VERSION ""

NS_ :

BS_:

BU_:

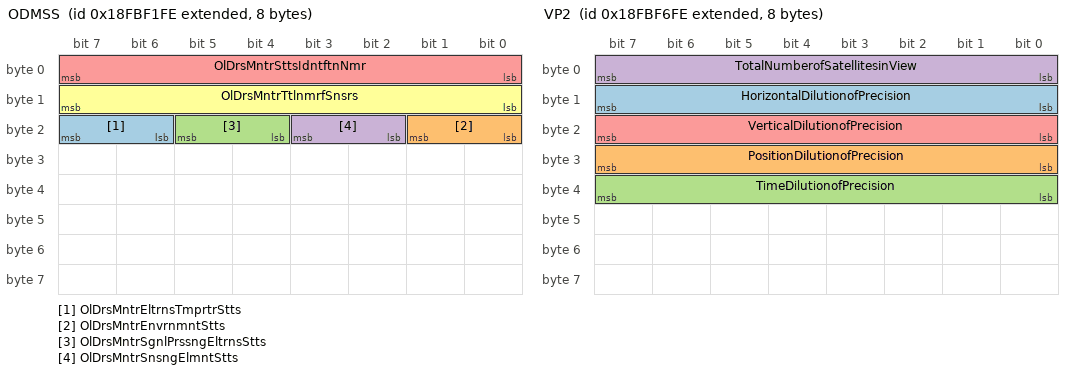
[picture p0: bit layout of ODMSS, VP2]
BO_ 2566648318 ODMSS: 8 Vector__XXX
 SG_ OlDrsMntrEltrnsTmprtrStts : 22|2@1+ (1,0) [0|3] "" Vector__XXX
 SG_ OlDrsMntrEnvrnmntStts : 16|2@1+ (1,0) [0|3] "" Vector__XXX
 SG_ OlDrsMntrSgnlPrssngEltrnsStts : 20|2@1+ (1,0) [0|3] "" Vector__XXX
 SG_ OlDrsMntrSnsngElmntStts : 18|2@1+ (1,0) [0|3] "" Vector__XXX
 SG_ OlDrsMntrSttsIdntftnNmr : 0|8@1+ (1,0) [0|250] "count" Vector__XXX
 SG_ OlDrsMntrTtlnmrfSnsrs : 8|8@1+ (1,0) [0|250] "count" Vector__XXX

BO_ 2566649086 A2DOC2: 8 Vector__XXX
 SG_ Atttt2DOCIttDPFOttDtPss : 32|16@1+ (0.1,0) [0|6425.5] "kPa" Vector__XXX
 SG_ Atttt2DsOxdtCtstItPss : 0|16@1+ (0.1,0) [0|6425.5] "kPa" Vector__XXX
 SG_ Atttt2DsOxdtCtstOttPss : 16|16@1+ (0.1,0) [0|6425.5] "kPa" Vector__XXX

BO_ 2566649342 A1DOC2: 8 Vector__XXX
 SG_ Atttt1DOCIttDPFOttDtPss : 32|16@1+ (0.1,0) [0|6425.5] "kPa" Vector__XXX
 SG_ Atttt1DsOxdtCtstItPss : 0|16@1+ (0.1,0) [0|6425.5] "kPa" Vector__XXX
 SG_ Atttt1DsOxdtCtstOttPss : 16|16@1+ (0.1,0) [0|6425.5] "kPa" Vector__XXX

BO_ 2566649598 VP2: 8 Vector__XXX
 SG_ HorizontalDilutionofPrecision : 8|8@1+ (0.1,0) [0|25] "Ratio" Vector__XXX
 SG_ PositionDilutionofPrecision : 24|8@1+ (0.1,0) [0|25] "Ratio" Vector__XXX
 SG_ TimeDilutionofPrecision : 32|8@1+ (0.1,0) [0|25] "Ratio" Vector__XXX
 SG_ TotalNumberofSatellitesinView : 0|8@1+ (1,0) [0|250] "count" Vector__XXX
 SG_ VerticalDilutionofPrecision : 16|8@1+ (0.1,0) [0|25] "Ratio" Vector__XXX

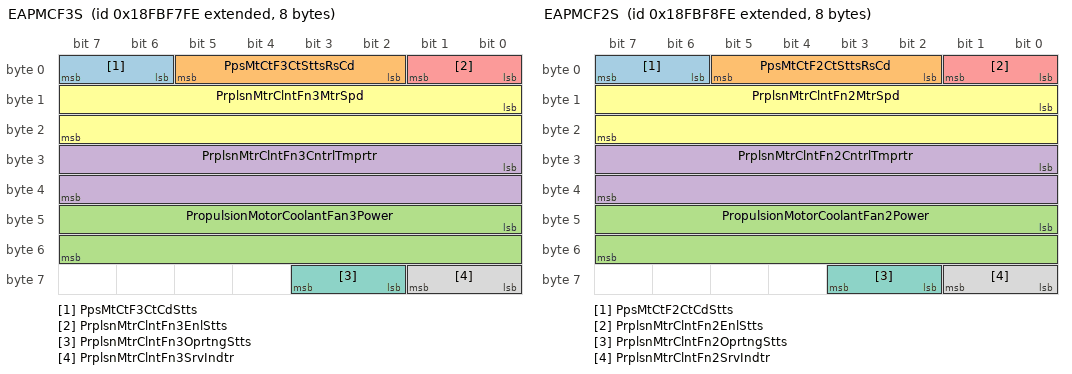
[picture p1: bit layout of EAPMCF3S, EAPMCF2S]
BO_ 2566649854 EAPMCF3S: 8 Vector__XXX
 SG_ PpsMtCtF3CtCdStts : 6|2@1+ (1,0) [0|3] "" Vector__XXX
 SG_ PpsMtCtF3CtSttsRsCd : 2|4@1+ (1,0) [0|15] "" Vector__XXX
 SG_ PropulsionMotorCoolantFan3Power : 40|16@1+ (0.5,0) [0|32127.5] "W" Vector__XXX
 SG_ PrplsnMtrClntFn3CntrlTmprtr : 24|16@1+ (0.03125,-273) [-273|1734.96875] "degC" Vector__XXX
 SG_ PrplsnMtrClntFn3EnlStts : 0|2@1+ (1,0) [0|3] "" Vector__XXX
 SG_ PrplsnMtrClntFn3MtrSpd : 8|16@1+ (0.5,0) [0|32127.5] "rpm" Vector__XXX
 SG_ PrplsnMtrClntFn3OprtngStts : 58|2@1+ (1,0) [0|3] "" Vector__XXX
 SG_ PrplsnMtrClntFn3SrvIndtr : 56|2@1+ (1,0) [0|3] "" Vector__XXX

BO_ 2566650110 EAPMCF2S: 8 Vector__XXX
 SG_ PpsMtCtF2CtCdStts : 6|2@1+ (1,0) [0|3] "" Vector__XXX
 SG_ PpsMtCtF2CtSttsRsCd : 2|4@1+ (1,0) [0|15] "" Vector__XXX
 SG_ PropulsionMotorCoolantFan2Power : 40|16@1+ (0.5,0) [0|32127.5] "W" Vector__XXX
 SG_ PrplsnMtrClntFn2CntrlTmprtr : 24|16@1+ (0.03125,-273) [-273|1734.96875] "degC" Vector__XXX
 SG_ PrplsnMtrClntFn2EnlStts : 0|2@1+ (1,0) [0|3] "" Vector__XXX
 SG_ PrplsnMtrClntFn2MtrSpd : 8|16@1+ (0.5,0) [0|32127.5] "rpm" Vector__XXX
 SG_ PrplsnMtrClntFn2OprtngStts : 58|2@1+ (1,0) [0|3] "" Vector__XXX
 SG_ PrplsnMtrClntFn2SrvIndtr : 56|2@1+ (1,0) [0|3] "" Vector__XXX

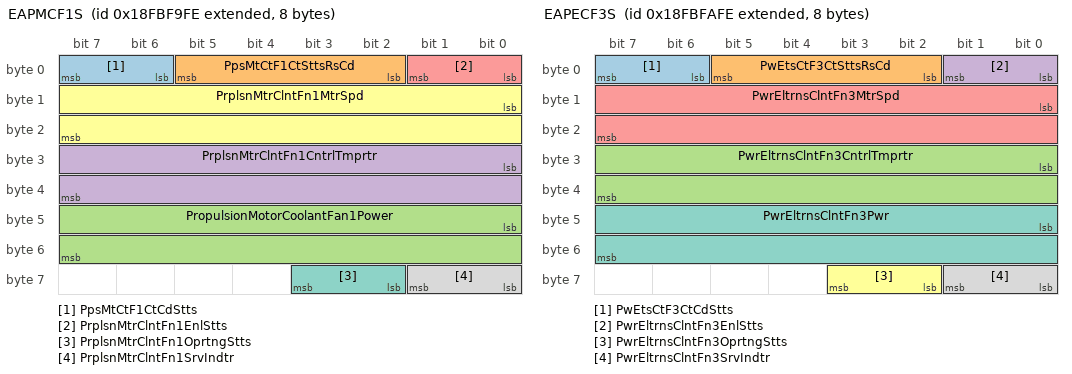
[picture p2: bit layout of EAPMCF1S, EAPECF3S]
BO_ 2566650366 EAPMCF1S: 8 Vector__XXX
 SG_ PpsMtCtF1CtCdStts : 6|2@1+ (1,0) [0|3] "" Vector__XXX
 SG_ PpsMtCtF1CtSttsRsCd : 2|4@1+ (1,0) [0|15] "" Vector__XXX
 SG_ PropulsionMotorCoolantFan1Power : 40|16@1+ (0.5,0) [0|32127.5] "W" Vector__XXX
 SG_ PrplsnMtrClntFn1CntrlTmprtr : 24|16@1+ (0.03125,-273) [-273|1734.96875] "degC" Vector__XXX
 SG_ PrplsnMtrClntFn1EnlStts : 0|2@1+ (1,0) [0|3] "" Vector__XXX
 SG_ PrplsnMtrClntFn1MtrSpd : 8|16@1+ (0.5,0) [0|32127.5] "rpm" Vector__XXX
 SG_ PrplsnMtrClntFn1OprtngStts : 58|2@1+ (1,0) [0|3] "" Vector__XXX
 SG_ PrplsnMtrClntFn1SrvIndtr : 56|2@1+ (1,0) [0|3] "" Vector__XXX

BO_ 2566650622 EAPECF3S: 8 Vector__XXX
 SG_ PwEtsCtF3CtCdStts : 6|2@1+ (1,0) [0|3] "" Vector__XXX
 SG_ PwEtsCtF3CtSttsRsCd : 2|4@1+ (1,0) [0|15] "" Vector__XXX
 SG_ PwrEltrnsClntFn3CntrlTmprtr : 24|16@1+ (0.03125,-273) [-273|1734.96875] "degC" Vector__XXX
 SG_ PwrEltrnsClntFn3EnlStts : 0|2@1+ (1,0) [0|3] "" Vector__XXX
 SG_ PwrEltrnsClntFn3MtrSpd : 8|16@1+ (0.5,0) [0|32127.5] "rpm" Vector__XXX
 SG_ PwrEltrnsClntFn3OprtngStts : 58|2@1+ (1,0) [0|3] "" Vector__XXX
 SG_ PwrEltrnsClntFn3Pwr : 40|16@1+ (0.5,0) [0|32127.5] "W" Vector__XXX
 SG_ PwrEltrnsClntFn3SrvIndtr : 56|2@1+ (1,0) [0|3] "" Vector__XXX

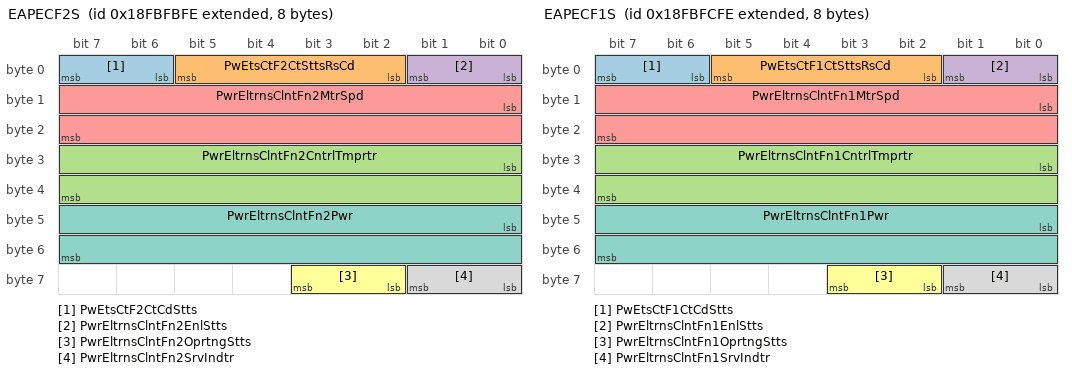
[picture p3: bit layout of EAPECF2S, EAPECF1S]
BO_ 2566650878 EAPECF2S: 8 Vector__XXX
 SG_ PwEtsCtF2CtCdStts : 6|2@1+ (1,0) [0|3] "" Vector__XXX
 SG_ PwEtsCtF2CtSttsRsCd : 2|4@1+ (1,0) [0|15] "" Vector__XXX
 SG_ PwrEltrnsClntFn2CntrlTmprtr : 24|16@1+ (0.03125,-273) [-273|1734.96875] "degC" Vector__XXX
 SG_ PwrEltrnsClntFn2EnlStts : 0|2@1+ (1,0) [0|3] "" Vector__XXX
 SG_ PwrEltrnsClntFn2MtrSpd : 8|16@1+ (0.5,0) [0|32127.5] "rpm" Vector__XXX
 SG_ PwrEltrnsClntFn2OprtngStts : 58|2@1+ (1,0) [0|3] "" Vector__XXX
 SG_ PwrEltrnsClntFn2Pwr : 40|16@1+ (0.5,0) [0|32127.5] "W" Vector__XXX
 SG_ PwrEltrnsClntFn2SrvIndtr : 56|2@1+ (1,0) [0|3] "" Vector__XXX

BO_ 2566651134 EAPECF1S: 8 Vector__XXX
 SG_ PwEtsCtF1CtCdStts : 6|2@1+ (1,0) [0|3] "" Vector__XXX
 SG_ PwEtsCtF1CtSttsRsCd : 2|4@1+ (1,0) [0|15] "" Vector__XXX
 SG_ PwrEltrnsClntFn1CntrlTmprtr : 24|16@1+ (0.03125,-273) [-273|1734.96875] "degC" Vector__XXX
 SG_ PwrEltrnsClntFn1EnlStts : 0|2@1+ (1,0) [0|3] "" Vector__XXX
 SG_ PwrEltrnsClntFn1MtrSpd : 8|16@1+ (0.5,0) [0|32127.5] "rpm" Vector__XXX
 SG_ PwrEltrnsClntFn1OprtngStts : 58|2@1+ (1,0) [0|3] "" Vector__XXX
 SG_ PwrEltrnsClntFn1Pwr : 40|16@1+ (0.5,0) [0|32127.5] "W" Vector__XXX
 SG_ PwrEltrnsClntFn1SrvIndtr : 56|2@1+ (1,0) [0|3] "" Vector__XXX

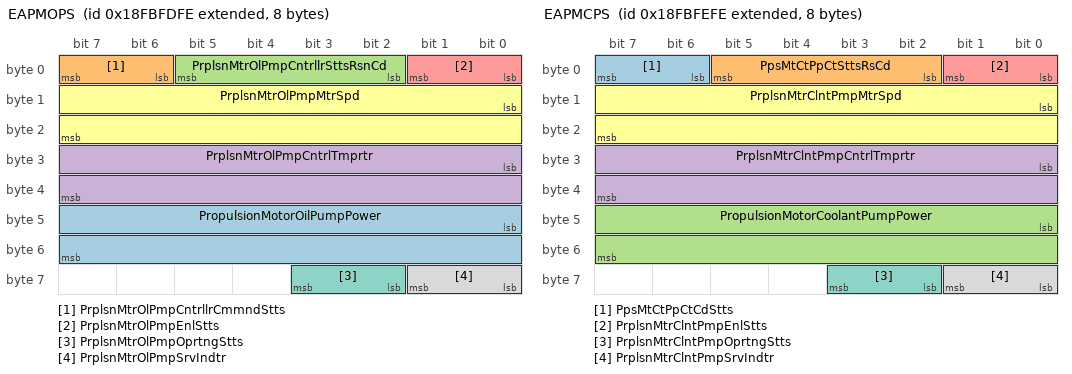
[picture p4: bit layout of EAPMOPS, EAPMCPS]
BO_ 2566651390 EAPMOPS: 8 Vector__XXX
 SG_ PropulsionMotorOilPumpPower : 40|16@1+ (0.5,0) [0|32127.5] "W" Vector__XXX
 SG_ PrplsnMtrOlPmpCntrllrCmmndStts : 6|2@1+ (1,0) [0|3] "" Vector__XXX
 SG_ PrplsnMtrOlPmpCntrllrSttsRsnCd : 2|4@1+ (1,0) [0|15] "" Vector__XXX
 SG_ PrplsnMtrOlPmpCntrlTmprtr : 24|16@1+ (0.03125,-273) [-273|1734.96875] "degC" Vector__XXX
 SG_ PrplsnMtrOlPmpEnlStts : 0|2@1+ (1,0) [0|3] "" Vector__XXX
 SG_ PrplsnMtrOlPmpMtrSpd : 8|16@1+ (0.5,0) [0|32127.5] "rpm" Vector__XXX
 SG_ PrplsnMtrOlPmpOprtngStts : 58|2@1+ (1,0) [0|3] "" Vector__XXX
 SG_ PrplsnMtrOlPmpSrvIndtr : 56|2@1+ (1,0) [0|3] "" Vector__XXX

BO_ 2566651646 EAPMCPS: 8 Vector__XXX
 SG_ PpsMtCtPpCtCdStts : 6|2@1+ (1,0) [0|3] "" Vector__XXX
 SG_ PpsMtCtPpCtSttsRsCd : 2|4@1+ (1,0) [0|15] "" Vector__XXX
 SG_ PropulsionMotorCoolantPumpPower : 40|16@1+ (0.5,0) [0|32127.5] "W" Vector__XXX
 SG_ PrplsnMtrClntPmpCntrlTmprtr : 24|16@1+ (0.03125,-273) [-273|1734.96875] "degC" Vector__XXX
 SG_ PrplsnMtrClntPmpEnlStts : 0|2@1+ (1,0) [0|3] "" Vector__XXX
 SG_ PrplsnMtrClntPmpMtrSpd : 8|16@1+ (0.5,0) [0|32127.5] "rpm" Vector__XXX
 SG_ PrplsnMtrClntPmpOprtngStts : 58|2@1+ (1,0) [0|3] "" Vector__XXX
 SG_ PrplsnMtrClntPmpSrvIndtr : 56|2@1+ (1,0) [0|3] "" Vector__XXX

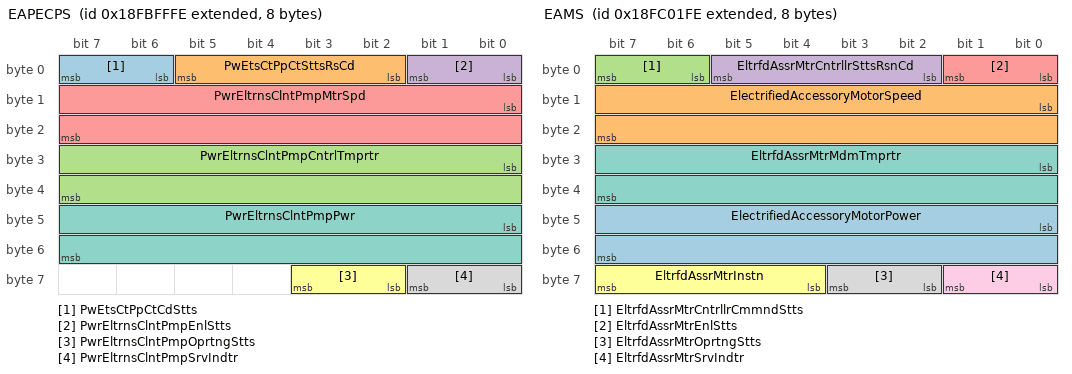
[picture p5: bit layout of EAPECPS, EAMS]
BO_ 2566651902 EAPECPS: 8 Vector__XXX
 SG_ PwEtsCtPpCtCdStts : 6|2@1+ (1,0) [0|3] "" Vector__XXX
 SG_ PwEtsCtPpCtSttsRsCd : 2|4@1+ (1,0) [0|15] "" Vector__XXX
 SG_ PwrEltrnsClntPmpCntrlTmprtr : 24|16@1+ (0.03125,-273) [-273|1734.96875] "degC" Vector__XXX
 SG_ PwrEltrnsClntPmpEnlStts : 0|2@1+ (1,0) [0|3] "" Vector__XXX
 SG_ PwrEltrnsClntPmpMtrSpd : 8|16@1+ (0.5,0) [0|32127.5] "rpm" Vector__XXX
 SG_ PwrEltrnsClntPmpOprtngStts : 58|2@1+ (1,0) [0|3] "" Vector__XXX
 SG_ PwrEltrnsClntPmpPwr : 40|16@1+ (0.5,0) [0|32127.5] "W" Vector__XXX
 SG_ PwrEltrnsClntPmpSrvIndtr : 56|2@1+ (1,0) [0|3] "" Vector__XXX

BO_ 2566652414 EAMS: 8 Vector__XXX
 SG_ ElectrifiedAccessoryMotorPower : 40|16@1+ (0.5,0) [0|32127.5] "W" Vector__XXX
 SG_ ElectrifiedAccessoryMotorSpeed : 8|16@1+ (0.5,0) [0|32127.5] "rpm" Vector__XXX
 SG_ EltrfdAssrMtrCntrllrCmmndStts : 6|2@1+ (1,0) [0|3] "" Vector__XXX
 SG_ EltrfdAssrMtrCntrllrSttsRsnCd : 2|4@1+ (1,0) [0|15] "" Vector__XXX
 SG_ EltrfdAssrMtrEnlStts : 0|2@1+ (1,0) [0|3] "" Vector__XXX
 SG_ EltrfdAssrMtrInstn : 60|4@1+ (1,0) [0|15] "" Vector__XXX
 SG_ EltrfdAssrMtrMdmTmprtr : 24|16@1+ (0.03125,-273) [-273|1734.96875] "degC" Vector__XXX
 SG_ EltrfdAssrMtrOprtngStts : 58|2@1+ (1,0) [0|3] "" Vector__XXX
 SG_ EltrfdAssrMtrSrvIndtr : 56|2@1+ (1,0) [0|3] "" Vector__XXX

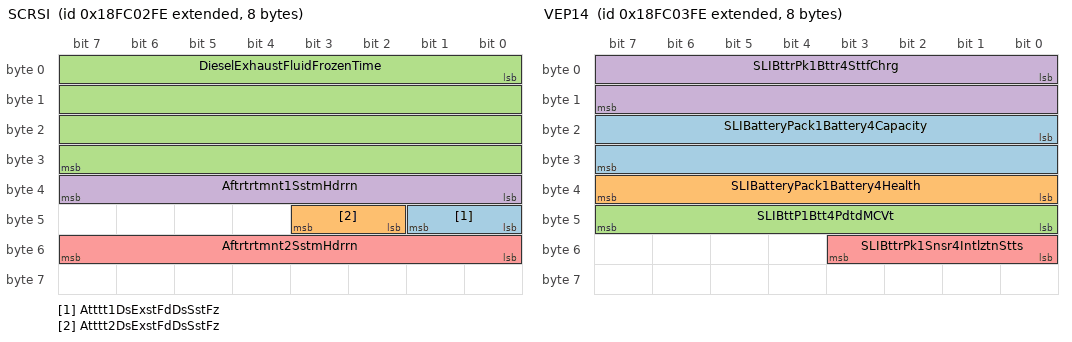
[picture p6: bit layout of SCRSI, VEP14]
BO_ 2566652670 SCRSI: 8 Vector__XXX
 SG_ Atttt1DsExstFdDsSstFz : 40|2@1+ (1,0) [0|3] "" Vector__XXX
 SG_ Atttt2DsExstFdDsSstFz : 42|2@1+ (1,0) [0|3] "" Vector__XXX
 SG_ DieselExhaustFluidFrozenTime : 0|32@1+ (1,0) [0|4211081215] "s" Vector__XXX
 SG_ Aftrtrtmnt1SstmHdrrn : 32|8@1+ (1,0) [0|250] "%" Vector__XXX
 SG_ Aftrtrtmnt2SstmHdrrn : 48|8@1+ (1,0) [0|250] "%" Vector__XXX

BO_ 2566652926 VEP14: 8 Vector__XXX
 SG_ SLIBatteryPack1Battery4Capacity : 16|16@1+ (1,0) [0|64255] "Ah" Vector__XXX
 SG_ SLIBatteryPack1Battery4Health : 32|8@1+ (0.5,0) [0|125] "%" Vector__XXX
 SG_ SLIBttP1Btt4PdtdMCVt : 40|8@1+ (0.2,0) [0|50] "V" Vector__XXX
 SG_ SLIBttrPk1Bttr4SttfChrg : 0|16@1+ (0.0025,0) [0|160.6375] "%" Vector__XXX
 SG_ SLIBttrPk1Snsr4IntlztnStts : 48|4@1+ (1,0) [0|15] "" Vector__XXX

BO_ 2566653182 VEP13: 8 Vector__XXX
 SG_ SLIBatteryPack1Battery4Voltage : 24|16@1+ (0.05,0) [0|3212.75] "V" Vector__XXX
 SG_ SLIBttrPk1Bttr4NtCrrnt : 0|16@1+ (0.05,-1600) [-1600|1612.75] "A" Vector__XXX
 SG_ SLIBttrPk1Bttr4Tmprtr : 16|8@1+ (1,-40) [-40|210] "degC" Vector__XXX

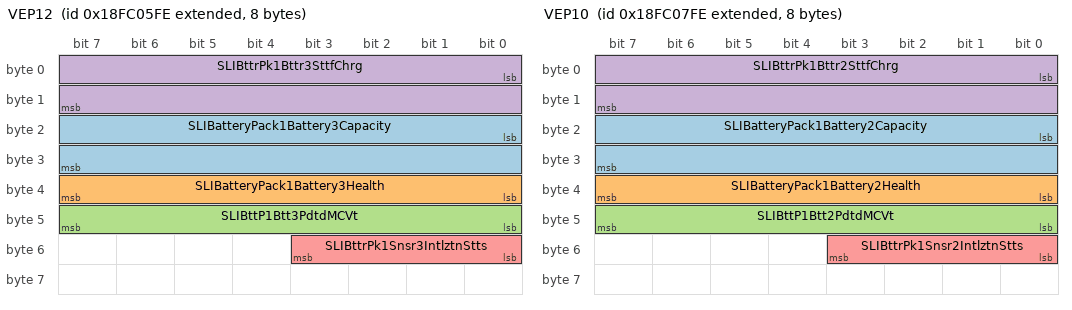
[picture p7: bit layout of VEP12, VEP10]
BO_ 2566653438 VEP12: 8 Vector__XXX
 SG_ SLIBatteryPack1Battery3Capacity : 16|16@1+ (1,0) [0|64255] "Ah" Vector__XXX
 SG_ SLIBatteryPack1Battery3Health : 32|8@1+ (0.5,0) [0|125] "%" Vector__XXX
 SG_ SLIBttP1Btt3PdtdMCVt : 40|8@1+ (0.2,0) [0|50] "V" Vector__XXX
 SG_ SLIBttrPk1Bttr3SttfChrg : 0|16@1+ (0.0025,0) [0|160.6375] "%" Vector__XXX
 SG_ SLIBttrPk1Snsr3IntlztnStts : 48|4@1+ (1,0) [0|15] "" Vector__XXX

BO_ 2566653694 VEP11: 8 Vector__XXX
 SG_ SLIBatteryPack1Battery3Voltage : 24|16@1+ (0.05,0) [0|3212.75] "V" Vector__XXX
 SG_ SLIBttrPk1Bttr3NtCrrnt : 0|16@1+ (0.05,-1600) [-1600|1612.75] "A" Vector__XXX
 SG_ SLIBttrPk1Bttr3Tmprtr : 16|8@1+ (1,-40) [-40|210] "degC" Vector__XXX

BO_ 2566653950 VEP10: 8 Vector__XXX
 SG_ SLIBatteryPack1Battery2Capacity : 16|16@1+ (1,0) [0|64255] "Ah" Vector__XXX
 SG_ SLIBatteryPack1Battery2Health : 32|8@1+ (0.5,0) [0|125] "%" Vector__XXX
 SG_ SLIBttP1Btt2PdtdMCVt : 40|8@1+ (0.2,0) [0|50] "V" Vector__XXX
 SG_ SLIBttrPk1Bttr2SttfChrg : 0|16@1+ (0.0025,0) [0|160.6375] "%" Vector__XXX
 SG_ SLIBttrPk1Snsr2IntlztnStts : 48|4@1+ (1,0) [0|15] "" Vector__XXX

BO_ 2566654206 VEP9: 8 Vector__XXX
 SG_ SLIBatteryPack1Battery2Voltage : 24|16@1+ (0.05,0) [0|3212.75] "V" Vector__XXX
 SG_ SLIBttrPk1Bttr2NtCrrnt : 0|16@1+ (0.05,-1600) [-1600|1612.75] "A" Vector__XXX
 SG_ SLIBttrPk1Bttr2Tmprtr : 16|8@1+ (1,-40) [-40|210] "degC" Vector__XXX

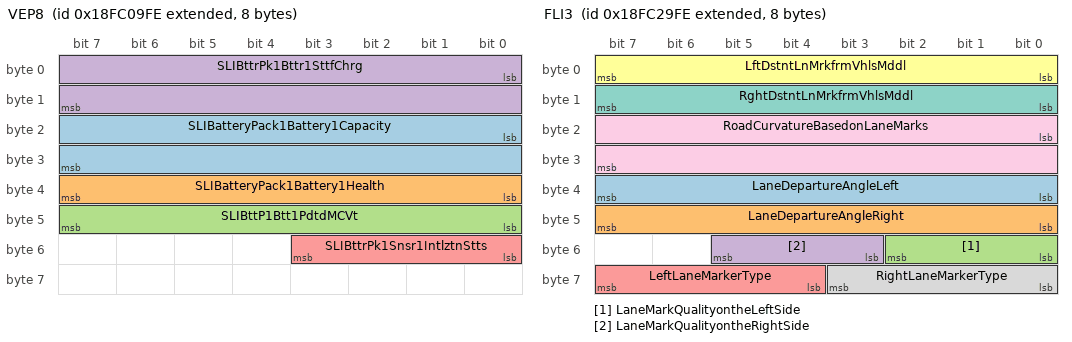
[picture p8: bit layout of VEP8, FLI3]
BO_ 2566654462 VEP8: 8 Vector__XXX
 SG_ SLIBatteryPack1Battery1Capacity : 16|16@1+ (1,0) [0|64255] "Ah" Vector__XXX
 SG_ SLIBatteryPack1Battery1Health : 32|8@1+ (0.5,0) [0|125] "%" Vector__XXX
 SG_ SLIBttP1Btt1PdtdMCVt : 40|8@1+ (0.2,0) [0|50] "V" Vector__XXX
 SG_ SLIBttrPk1Bttr1SttfChrg : 0|16@1+ (0.0025,0) [0|160.6375] "%" Vector__XXX
 SG_ SLIBttrPk1Snsr1IntlztnStts : 48|4@1+ (1,0) [0|15] "" Vector__XXX

BO_ 2566654718 VEP7: 8 Vector__XXX
 SG_ SLIBatteryPack1Battery1Voltage : 24|16@1+ (0.05,0) [0|3212.75] "V" Vector__XXX
 SG_ SLIBttrPk1Bttr1NtCrrnt : 0|16@1+ (0.05,-1600) [-1600|1612.75] "A" Vector__XXX
 SG_ SLIBttrPk1Bttr1Tmprtr : 16|8@1+ (1,-40) [-40|210] "degC" Vector__XXX

BO_ 2566654974 EEC20: 8 Vector__XXX
 SG_ AtlMxmmAvllEngnPrntFl : 16|8@1+ (0.4,0) [0|100] "%" Vector__XXX
 SG_ EsttdEPstLsssPtTqHRst : 0|16@1+ (0.0015625,0) [0|100.3984375] "%" Vector__XXX
 SG_ NmnlFrtnPrntTrqHghRsltn : 24|16@1+ (0.0015625,0) [0|100.3984375] "%" Vector__XXX
 SG_ AsltEngnLdPrntArMss : 40|16@1+ (0.025,0) [0|1606.375] "%" Vector__XXX

BO_ 2566655742 PHRPS: 8 Vector__XXX
 SG_ RearHitchPitchSensitivity : 8|8@1+ (0.4,0) [0|100] "%" Vector__XXX
 SG_ RearHitchRollSensitivity : 0|8@1+ (0.4,0) [0|100] "%" Vector__XXX

BO_ 2566656254 AMB3: 8 Vector__XXX
 SG_ BarometricAbsolutePressure2 : 0|16@1+ (0.1,0) [0|6425.5] "kPa" Vector__XXX
 SG_ EngineIntake2AirTemperature : 16|8@1+ (1,-40) [-40|210] "degC" Vector__XXX
 SG_ EngnPwrDrtRltvHmdtDffrn : 24|16@1+ (0.01,-321.27) [-321.27|321.28] "%" Vector__XXX

BO_ 2566656510 TGFI: 8 Vector__XXX
 SG_ EngnTtlGssFlVlmUsd : 0|32@1+ (0.5,0) [0|2105540607.5] "m*m*m" Vector__XXX
 SG_ EngnTtlGssIdlFlVlmUsd : 32|32@1+ (0.5,0) [0|2105540607.5] "m*m*m" Vector__XXX

BO_ 2566658302 PLST2: 8 Vector__XXX
 SG_ TotalPayloadTransactionCount : 0|32@1+ (1,0) [0|4211081215] "count" Vector__XXX

BO_ 2566658558 PLST1: 8 Vector__XXX
 SG_ TotalDeliveredPayloadWeight : 0|32@1+ (100,0) [0|421108121500] "kg" Vector__XXX
 SG_ TotalHaulCycleCount : 32|32@1+ (1,0) [0|4211081215] "count" Vector__XXX

BO_ 2566661118 LFC2: 8 Vector__XXX
 SG_ EngineTotalDieselFuelDemand : 0|32@1+ (0.5,0) [0|2105540607.5] "l" Vector__XXX

BO_ 2566661374 AT2T1I2: 8 Vector__XXX
 SG_ Aftrtrtmnt2DslExhstFldTnkHtr2 : 16|8@1+ (0.4,0) [0|100] "%" Vector__XXX
 SG_ Aftrtrtmnt2DslExhstFldTnkVlm2 : 0|8@1+ (0.4,0) [0|100] "%" Vector__XXX
 SG_ Atttt2DsExstFdTTpt2 : 8|8@1+ (1,-40) [-40|210] "degC" Vector__XXX

BO_ 2566661630 AT1T1I2: 8 Vector__XXX
 SG_ Aftrtrtmnt1DslExhstFldTnkHtr2 : 16|8@1+ (0.4,0) [0|100] "%" Vector__XXX
 SG_ Aftrtrtmnt1DslExhstFldTnkVlm2 : 0|8@1+ (0.4,0) [0|100] "%" Vector__XXX
 SG_ Atttt1DsExstFdTTpt2 : 8|8@1+ (1,-40) [-40|210] "degC" Vector__XXX

BO_ 2566661886 A2DEFI2: 8 Vector__XXX
 SG_ Atttt2DsExstFdCt2Tpt : 8|8@1+ (1,-40) [-40|210] "degC" Vector__XXX
 SG_ Atttt2DsExstFdCtTpt : 0|8@1+ (1,-40) [-40|210] "degC" Vector__XXX

BO_ 2566662142 A1DEFI2: 8 Vector__XXX
 SG_ Atttt1DsExstFdCt1Tpt : 0|8@1+ (1,-40) [-40|210] "degC" Vector__XXX
 SG_ Atttt1DsExstFdCt2Tpt : 8|8@1+ (1,-40) [-40|210] "degC" Vector__XXX

BO_ 2566662654 FLI3: 8 Vector__XXX
 SG_ LaneDepartureAngleLeft : 32|8@1+ (0.1,-12.5) [-12.5|12.5] "deg" Vector__XXX
 SG_ LaneDepartureAngleRight : 40|8@1+ (0.1,-12.5) [-12.5|12.5] "deg" Vector__XXX
 SG_ LaneMarkQualityontheLeftSide : 48|3@1+ (1,0) [0|7] "" Vector__XXX
 SG_ LaneMarkQualityontheRightSide : 51|3@1+ (1,0) [0|7] "" Vector__XXX
 SG_ LeftLaneMarkerType : 60|4@1+ (1,0) [0|15] "" Vector__XXX
 SG_ LftDstntLnMrkfrmVhlsMddl : 0|8@1+ (0.02,0) [0|5] "m" Vector__XXX
 SG_ RghtDstntLnMrkfrmVhlsMddl : 8|8@1+ (0.02,0) [0|5] "m" Vector__XXX
 SG_ RightLaneMarkerType : 56|4@1+ (1,0) [0|15] "" Vector__XXX
 SG_ RoadCurvatureBasedonLaneMarks : 16|16@1+ (0.0078125,-250) [-250|251.992] "1/km" Vector__XXX

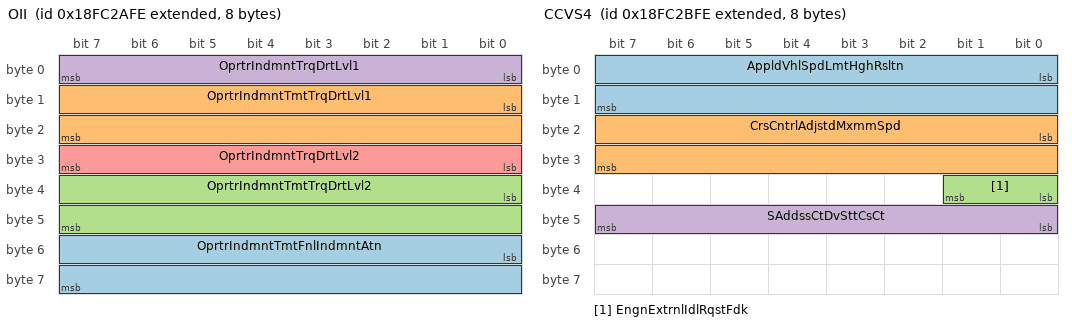
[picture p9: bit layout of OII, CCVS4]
BO_ 2566662910 OII: 8 Vector__XXX
 SG_ OprtrIndmntTmtFnlIndmntAtn : 48|16@1+ (1,0) [0|64255] "min" Vector__XXX
 SG_ OprtrIndmntTmtTrqDrtLvl1 : 8|16@1+ (1,0) [0|64255] "min" Vector__XXX
 SG_ OprtrIndmntTmtTrqDrtLvl2 : 32|16@1+ (1,0) [0|64255] "min" Vector__XXX
 SG_ OprtrIndmntTrqDrtLvl1 : 0|8@1+ (1,0) [0|250] "%" Vector__XXX
 SG_ OprtrIndmntTrqDrtLvl2 : 24|8@1+ (1,0) [0|250] "%" Vector__XXX

BO_ 2566663166 CCVS4: 8 Vector__XXX
 SG_ AppldVhlSpdLmtHghRsltn : 0|16@1+ (0.00390625,0) [0|250.996] "km/h" Vector__XXX
 SG_ CrsCntrlAdjstdMxmmSpd : 16|16@1+ (0.00390625,0) [0|250.996] "km/h" Vector__XXX
 SG_ EngnExtrnlIdlRqstFdk : 32|2@1+ (1,0) [0|3] "" Vector__XXX
 SG_ SAddssCtDvSttCsCt : 40|8@1+ (1,0) [0|255] "SA" Vector__XXX

BO_ 2566663422 BCLC: 8 Vector__XXX
 SG_ TrlrBrkClprLnngClrnAxl1Lft : 20|2@1+ (1,0) [0|3] "" Vector__XXX
 SG_ TrlrBrkClprLnngClrnAxl1Rght : 22|2@1+ (1,0) [0|3] "" Vector__XXX
 SG_ TrlrBrkClprLnngClrnAxl2Lft : 24|2@1+ (1,0) [0|3] "" Vector__XXX
 SG_ TrlrBrkClprLnngClrnAxl2Rght : 26|2@1+ (1,0) [0|3] "" Vector__XXX
 SG_ TrlrBrkClprLnngClrnAxl3Lft : 28|2@1+ (1,0) [0|3] "" Vector__XXX
 SG_ TrlrBrkClprLnngClrnAxl3Rght : 30|2@1+ (1,0) [0|3] "" Vector__XXX
 SG_ TrlrBrkClprLnngClrnAxl4Lft : 32|2@1+ (1,0) [0|3] "" Vector__XXX
 SG_ TrlrBrkClprLnngClrnAxl4Rght : 34|2@1+ (1,0) [0|3] "" Vector__XXX
 SG_ TrlrBrkClprLnngClrnAxl5Lft : 36|2@1+ (1,0) [0|3] "" Vector__XXX
 SG_ TrlrBrkClprLnngClrnAxl5Rght : 38|2@1+ (1,0) [0|3] "" Vector__XXX
 SG_ TrtrBrkClprLnngClrnAxl1Lft : 0|2@1+ (1,0) [0|3] "" Vector__XXX
 SG_ TrtrBrkClprLnngClrnAxl1Rght : 2|2@1+ (1,0) [0|3] "" Vector__XXX
 SG_ TrtrBrkClprLnngClrnAxl2Lft : 4|2@1+ (1,0) [0|3] "" Vector__XXX
 SG_ TrtrBrkClprLnngClrnAxl2Rght : 6|2@1+ (1,0) [0|3] "" Vector__XXX
 SG_ TrtrBrkClprLnngClrnAxl3Lft : 8|2@1+ (1,0) [0|3] "" Vector__XXX
 SG_ TrtrBrkClprLnngClrnAxl3Rght : 10|2@1+ (1,0) [0|3] "" Vector__XXX
 SG_ TrtrBrkClprLnngClrnAxl4Lft : 12|2@1+ (1,0) [0|3] "" Vector__XXX
 SG_ TrtrBrkClprLnngClrnAxl4Rght : 14|2@1+ (1,0) [0|3] "" Vector__XXX
 SG_ TrtrBrkClprLnngClrnAxl5Lft : 16|2@1+ (1,0) [0|3] "" Vector__XXX
 SG_ TrtrBrkClprLnngClrnAxl5Rght : 18|2@1+ (1,0) [0|3] "" Vector__XXX

BO_ 2566663678 AF5: 8 Vector__XXX
 SG_ EngnFl2InjtrMtrngRl1Tmprtr2 : 32|8@1+ (1,-40) [-40|210] "degC" Vector__XXX
 SG_ LNGTank1VaporPressure : 0|16@1+ (0.1,0) [0|6425.5] "kPa" Vector__XXX
 SG_ LNGTank2VaporPressure : 16|16@1+ (0.1,0) [0|6425.5] "kPa" Vector__XXX

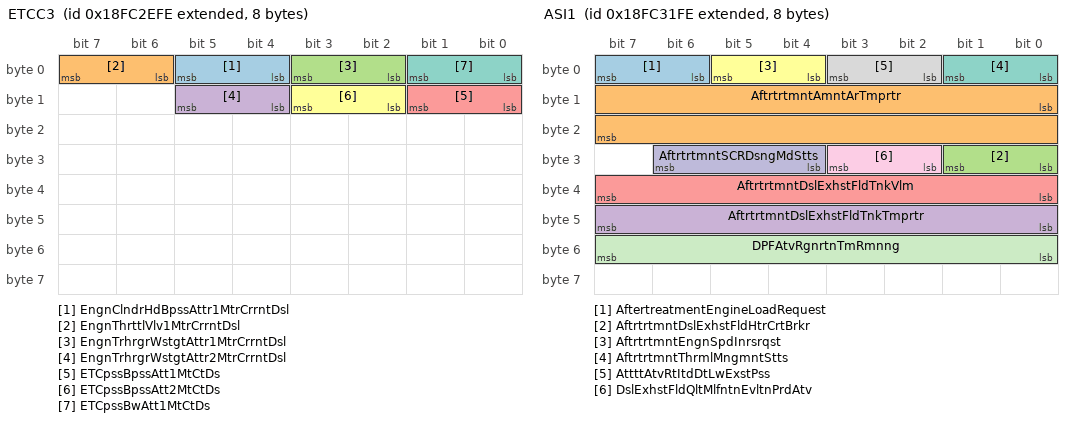
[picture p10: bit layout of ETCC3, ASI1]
BO_ 2566663934 ETCC3: 8 Vector__XXX
 SG_ EngnClndrHdBpssAttr1MtrCrrntDsl : 4|2@1+ (1,0) [0|3] "" Vector__XXX
 SG_ EngnThrttlVlv1MtrCrrntDsl : 6|2@1+ (1,0) [0|3] "" Vector__XXX
 SG_ EngnTrhrgrWstgtAttr1MtrCrrntDsl : 2|2@1+ (1,0) [0|3] "" Vector__XXX
 SG_ EngnTrhrgrWstgtAttr2MtrCrrntDsl : 12|2@1+ (1,0) [0|3] "" Vector__XXX
 SG_ ETCpssBpssAtt1MtCtDs : 8|2@1+ (1,0) [0|3] "" Vector__XXX
 SG_ ETCpssBpssAtt2MtCtDs : 10|2@1+ (1,0) [0|3] "" Vector__XXX
 SG_ ETCpssBwAtt1MtCtDs : 0|2@1+ (1,0) [0|3] "" Vector__XXX

BO_ 2566664702 ASI1: 8 Vector__XXX
 SG_ AftertreatmentEngineLoadRequest : 6|2@1+ (1,0) [0|3] "" Vector__XXX
 SG_ AftrtrtmntAmntArTmprtr : 8|16@1+ (0.03125,-273) [-273|1734.96875] "degC" Vector__XXX
 SG_ AftrtrtmntDslExhstFldHtrCrtBrkr : 24|2@1+ (1,0) [0|3] "" Vector__XXX
 SG_ AftrtrtmntDslExhstFldTnkTmprtr : 40|8@1+ (1,-40) [-40|210] "degC" Vector__XXX
 SG_ AftrtrtmntDslExhstFldTnkVlm : 32|8@1+ (0.4,0) [0|100] "%" Vector__XXX
 SG_ AftrtrtmntEngnSpdInrsrqst : 4|2@1+ (1,0) [0|3] "" Vector__XXX
 SG_ AftrtrtmntThrmlMngmntStts : 0|2@1+ (1,0) [0|3] "" Vector__XXX
 SG_ AttttAtvRtItdDtLwExstPss : 2|2@1+ (1,0) [0|3] "" Vector__XXX
 SG_ DslExhstFldQltMlfntnEvltnPrdAtv : 26|2@1+ (1,0) [0|3] "" Vector__XXX
 SG_ AftrtrtmntSCRDsngMdStts : 28|3@1+ (1,0) [0|7] "" Vector__XXX
 SG_ DPFAtvRgnrtnTmRmnng : 48|8@1+ (1,0) [0|250] "min" Vector__XXX

BO_ 2566665726 AT2P1I: 8 Vector__XXX
 SG_ Aftrtrtmnt2DslExhstFldPmpHtr : 0|8@1+ (0.4,0) [0|100] "%" Vector__XXX
 SG_ Atttt2DsExstFdPp2MtSpd : 8|16@1+ (0.5,0) [0|32127.5] "rpm" Vector__XXX

BO_ 2566667262 EEBT3: 8 Vector__XXX
 SG_ EngineEndBearing17Temperature : 0|8@1+ (1,-40) [-40|210] "degC" Vector__XXX
 SG_ EngineEndBearing18Temperature : 8|8@1+ (1,-40) [-40|210] "degC" Vector__XXX
 SG_ EngineEndBearing19Temperature : 16|8@1+ (1,-40) [-40|210] "degC" Vector__XXX
 SG_ EngineEndBearing20Temperature : 24|8@1+ (1,-40) [-40|210] "degC" Vector__XXX

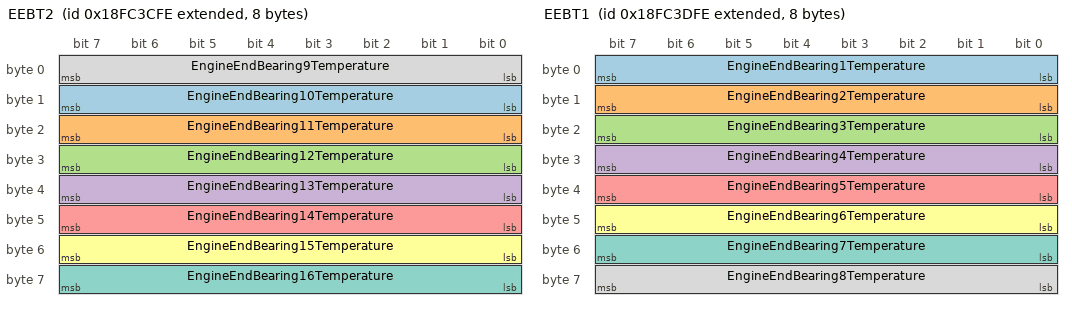
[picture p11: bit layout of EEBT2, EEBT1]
BO_ 2566667518 EEBT2: 8 Vector__XXX
 SG_ EngineEndBearing10Temperature : 8|8@1+ (1,-40) [-40|210] "degC" Vector__XXX
 SG_ EngineEndBearing11Temperature : 16|8@1+ (1,-40) [-40|210] "degC" Vector__XXX
 SG_ EngineEndBearing12Temperature : 24|8@1+ (1,-40) [-40|210] "degC" Vector__XXX
 SG_ EngineEndBearing13Temperature : 32|8@1+ (1,-40) [-40|210] "degC" Vector__XXX
 SG_ EngineEndBearing14Temperature : 40|8@1+ (1,-40) [-40|210] "degC" Vector__XXX
 SG_ EngineEndBearing15Temperature : 48|8@1+ (1,-40) [-40|210] "degC" Vector__XXX
 SG_ EngineEndBearing16Temperature : 56|8@1+ (1,-40) [-40|210] "degC" Vector__XXX
 SG_ EngineEndBearing9Temperature : 0|8@1+ (1,-40) [-40|210] "degC" Vector__XXX

BO_ 2566667774 EEBT1: 8 Vector__XXX
 SG_ EngineEndBearing1Temperature : 0|8@1+ (1,-40) [-40|210] "degC" Vector__XXX
 SG_ EngineEndBearing2Temperature : 8|8@1+ (1,-40) [-40|210] "degC" Vector__XXX
 SG_ EngineEndBearing3Temperature : 16|8@1+ (1,-40) [-40|210] "degC" Vector__XXX
 SG_ EngineEndBearing4Temperature : 24|8@1+ (1,-40) [-40|210] "degC" Vector__XXX
 SG_ EngineEndBearing5Temperature : 32|8@1+ (1,-40) [-40|210] "degC" Vector__XXX
 SG_ EngineEndBearing6Temperature : 40|8@1+ (1,-40) [-40|210] "degC" Vector__XXX
 SG_ EngineEndBearing7Temperature : 48|8@1+ (1,-40) [-40|210] "degC" Vector__XXX
 SG_ EngineEndBearing8Temperature : 56|8@1+ (1,-40) [-40|210] "degC" Vector__XXX

BO_ 2566668030 HEDPI: 8 Vector__XXX
 SG_ HeatExchangerDebrisPurgeStatus : 0|2@1+ (1,0) [0|3] "" Vector__XXX
 SG_ HtExhngrDrsPrgApprhng : 2|2@1+ (1,0) [0|3] "" Vector__XXX

BO_ 2566668286 ETCC2: 8 Vector__XXX
 SG_ EngnStgdTrhrgrSlndStts : 0|8@1+ (0.4,0) [0|100] "%" Vector__XXX

BO_ 2566668542 EHF2PC: 8 Vector__XXX
 SG_ EngnFl2PmpHdrlDrtnlVlv : 16|8@1+ (0.4,0) [0|100] "%" Vector__XXX
 SG_ EngnFl2PmpHdrlFlwCntrlVlv : 0|8@1+ (0.4,0) [0|100] "%" Vector__XXX
 SG_ EngnFl2PmpHdrlPrssr : 24|16@1+ (2,0) [0|128510] "kPa" Vector__XXX
 SG_ EngnFl2PmpHdrlSwshPltAngl : 8|8@1+ (0.4,0) [0|100] "%" Vector__XXX

BO_ 2566668798 AF4: 8 Vector__XXX
 SG_ EngnFl2InjtrMtrngRl1Prssr : 0|16@1+ (2,0) [0|128510] "kPa" Vector__XXX
 SG_ EngnFl2InjtrMtrngRl1Prssr2 : 48|16@1+ (2,0) [0|128510] "kPa" Vector__XXX
 SG_ EngnFl2InjtrMtrngRl1Tmprtr : 32|8@1+ (1,-40) [-40|210] "degC" Vector__XXX
 SG_ EngnFl2InjtrMtrngRl2Prssr : 16|16@1+ (2,0) [0|128510] "kPa" Vector__XXX
 SG_ EngnFl2InjtrMtrngRl2Tmprtr : 40|8@1+ (1,-40) [-40|210] "degC" Vector__XXX

BO_ 2566669054 TIRE2: 8 Vector__XXX
 SG_ RequiredTirePressure : 24|16@1+ (1,0) [0|64255] "kPa" Vector__XXX
 SG_ TireLocation : 0|8@1+ (8,0) [0|0] "bit-mapped" Vector__XXX
 SG_ TirePressureExtendedRange : 8|16@1+ (1,0) [0|64255] "kPa" Vector__XXX

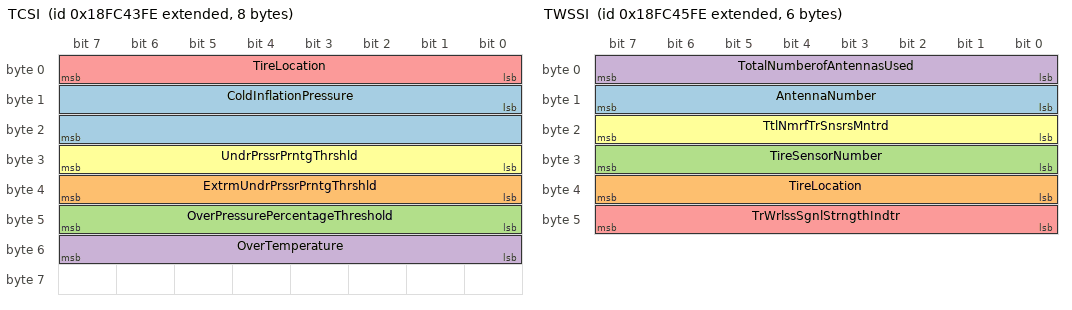
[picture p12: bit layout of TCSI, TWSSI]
BO_ 2566669310 TCSI: 8 Vector__XXX
 SG_ ColdInflationPressure : 8|16@1+ (1,0) [0|64255] "kPa" Vector__XXX
 SG_ ExtrmUndrPrssrPrntgThrshld : 32|8@1+ (0.5,0) [0|125] "%" Vector__XXX
 SG_ OverPressurePercentageThreshold : 40|8@1+ (0.5,0) [0|125] "%" Vector__XXX
 SG_ OverTemperature : 48|8@1+ (1,-40) [-40|210] "degC" Vector__XXX
 SG_ TireLocation : 0|8@1+ (8,0) [0|0] "bit-mapped" Vector__XXX
 SG_ UndrPrssrPrntgThrshld : 24|8@1+ (0.5,0) [0|125] "%" Vector__XXX

BO_ 2566669822 TWSSI: 6 Vector__XXX
 SG_ AntennaNumber : 8|8@1+ (1,0) [0|250] "count" Vector__XXX
 SG_ TireLocation : 32|8@1+ (8,0) [0|0] "bit-mapped" Vector__XXX
 SG_ TireSensorNumber : 24|8@1+ (1,0) [0|250] "count" Vector__XXX
 SG_ TotalNumberofAntennasUsed : 0|8@1+ (1,0) [0|250] "count" Vector__XXX
 SG_ TrWrlssSgnlStrngthIndtr : 40|8@1+ (0.5,-125) [-125|0] "dBm" Vector__XXX
 SG_ TtlNmrfTrSnsrsMntrd : 16|8@1+ (1,0) [0|250] "count" Vector__XXX

BO_ 2566670078 TSIS: 200 Vector__XXX
 SG_ NumberofTireSensors : 0|8@1+ (1,0) [0|250] "count" Vector__XXX
 SG_ TireLocation : 16|8@1+ (1,0) [0|255] "count" Vector__XXX
 SG_ TireNumber : 8|8@1+ (1,0) [0|250] "count" Vector__XXX
 SG_ TireSensorIdentificationNumber : 24|8@1+ (1,0) [0|255] "ASCII" Vector__XXX

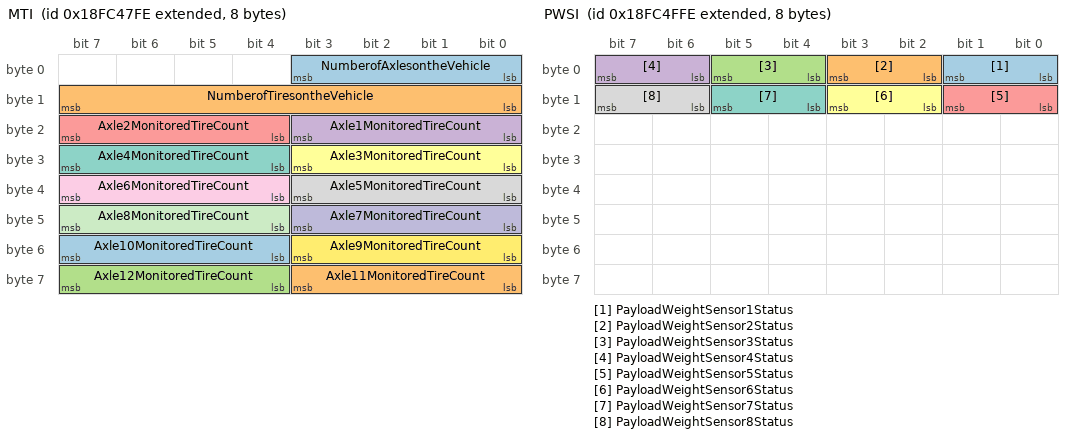
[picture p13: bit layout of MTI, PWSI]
BO_ 2566670334 MTI: 8 Vector__XXX
 SG_ Axle10MonitoredTireCount : 52|4@1+ (1,0) [0|13] "count" Vector__XXX
 SG_ Axle11MonitoredTireCount : 56|4@1+ (1,0) [0|13] "count" Vector__XXX
 SG_ Axle12MonitoredTireCount : 60|4@1+ (1,0) [0|13] "count" Vector__XXX
 SG_ Axle1MonitoredTireCount : 16|4@1+ (1,0) [0|13] "count" Vector__XXX
 SG_ Axle2MonitoredTireCount : 20|4@1+ (1,0) [0|13] "count" Vector__XXX
 SG_ Axle3MonitoredTireCount : 24|4@1+ (1,0) [0|13] "count" Vector__XXX
 SG_ Axle4MonitoredTireCount : 28|4@1+ (1,0) [0|13] "count" Vector__XXX
 SG_ Axle5MonitoredTireCount : 32|4@1+ (1,0) [0|13] "count" Vector__XXX
 SG_ Axle6MonitoredTireCount : 36|4@1+ (1,0) [0|13] "count" Vector__XXX
 SG_ Axle7MonitoredTireCount : 40|4@1+ (1,0) [0|13] "count" Vector__XXX
 SG_ Axle8MonitoredTireCount : 44|4@1+ (1,0) [0|13] "count" Vector__XXX
 SG_ Axle9MonitoredTireCount : 48|4@1+ (1,0) [0|13] "count" Vector__XXX
 SG_ NumberofAxlesontheVehicle : 0|4@1+ (1,0) [0|13] "count" Vector__XXX
 SG_ NumberofTiresontheVehicle : 8|8@1+ (1,0) [0|250] "count" Vector__XXX

BO_ 2566670590 AT2HI2: 24 Vector__XXX
 SG_ Atttt2SCRSstAvDstBtwSstCEvts : 160|32@1+ (0.125,0) [0|526385151.875] "km" Vector__XXX
 SG_ Atttt2SCRSstAvTBtwSstCEvts : 128|32@1+ (1,0) [0|4211081215] "s" Vector__XXX
 SG_ Atttt2SCRSstTtNSstCEvts : 32|32@1+ (1,0) [0|4211081215] "count" Vector__XXX
 SG_ Atttt2SCRSstTtNSstCItRqsts : 64|32@1+ (1,0) [0|4211081215] "count" Vector__XXX
 SG_ Atttt2SCRSstTtNSstCMRqsts : 96|32@1+ (1,0) [0|4211081215] "count" Vector__XXX
 SG_ Atttt2SCRSstTtSstCT : 0|32@1+ (1,0) [0|4211081215] "s" Vector__XXX

BO_ 2566670846 AT1HI2: 28 Vector__XXX
 SG_ Aftrtrtmnt1SCRSstmTtlClnngTm : 0|32@1+ (1,0) [0|4211081215] "s" Vector__XXX
 SG_ Atttt1SCRSstAvDstBtwSstCEvts : 160|32@1+ (0.125,0) [0|526385151.875] "km" Vector__XXX
 SG_ Atttt1SCRSstAvTBtwSstCEvts : 128|32@1+ (1,0) [0|4211081215] "s" Vector__XXX
 SG_ Atttt1SCRSstTtNSstCEvts : 32|32@1+ (1,0) [0|4211081215] "count" Vector__XXX
 SG_ Atttt1SCRSstTtNSstCItRqsts : 64|32@1+ (1,0) [0|4211081215] "count" Vector__XXX
 SG_ Atttt1SCRSstTtNSstCMRqsts : 96|32@1+ (1,0) [0|4211081215] "count" Vector__XXX
 SG_ TtlAftrtrtmntOprtngHrs : 192|32@1+ (1,0) [0|4211081215] "s" Vector__XXX

BO_ 2566671102 SCRSC: 8 Vector__XXX
 SG_ Atttt1SCRSstCdtsNtMtAtvC : 60|2@1+ (1,0) [0|3] "" Vector__XXX
 SG_ SCRSstCItdDtAtPdOId : 26|2@1+ (1,0) [0|3] "" Vector__XXX
 SG_ SCRSstCItdDtLwExstTpt : 34|2@1+ (1,0) [0|3] "" Vector__XXX
 SG_ SCRSstCItdDtPtSstLt : 42|2@1+ (1,0) [0|3] "" Vector__XXX
 SG_ SCRSstCItdDtVSpdAvAwdSpd : 30|2@1+ (1,0) [0|3] "" Vector__XXX
 SG_ SCRSstCItdDtVSpdBwAwdSpd : 46|2@1+ (1,0) [0|3] "" Vector__XXX
 SG_ SCRSstmClnngAtmtInttnCnfgrtn : 48|2@1+ (1,0) [0|3] "" Vector__XXX
 SG_ SCRSstmClnngInhtdDtClthDsnggd : 20|2@1+ (1,0) [0|3] "" Vector__XXX
 SG_ SCRSstmClnngInhtdDtEngnNtWrmdUp : 44|2@1+ (1,0) [0|3] "" Vector__XXX
 SG_ SCRSstmClnngInhtdDtInhtSwth : 18|2@1+ (1,0) [0|3] "" Vector__XXX
 SG_ SCRSstmClnngInhtdDtOtfNtrl : 28|2@1+ (1,0) [0|3] "" Vector__XXX
 SG_ SCRSstmClnngInhtdDtPrkngBrkNtSt : 32|2@1+ (1,0) [0|3] "" Vector__XXX
 SG_ SCRSstmClnngInhtdDtPTOAtv : 24|2@1+ (1,0) [0|3] "" Vector__XXX
 SG_ SCRSstmClnngInhtdDtSrvBrkAtv : 22|2@1+ (1,0) [0|3] "" Vector__XXX
 SG_ SCRSstmClnngInhtdDtSstmFltAtv : 36|2@1+ (1,0) [0|3] "" Vector__XXX
 SG_ SCRSstmClnngInhtdDtSstmTmt : 38|2@1+ (1,0) [0|3] "" Vector__XXX
 SG_ SCRSstmClnngInhtdDtTmprrSstmLkt : 40|2@1+ (1,0) [0|3] "" Vector__XXX
 SG_ SCRSstmClnngInhtdStts : 16|2@1+ (1,0) [0|3] "" Vector__XXX
 SG_ SCRSystemCleaningForcedStatus : 53|3@1+ (1,0) [0|7] "" Vector__XXX
 SG_ SCRSystemCleaningLampCommand : 0|3@1+ (1,0) [0|7] "" Vector__XXX
 SG_ SCRSystemCleaningStatus : 10|2@1+ (1,0) [0|3] "" Vector__XXX

BO_ 2566671358 EEC17: 8 Vector__XXX
 SG_ CylinderFuelRate : 48|16@1+ (0.03125,0) [0|2007.96875] "mg/stroke" Vector__XXX
 SG_ EngineExhaustFlowRate : 32|16@1+ (0.2,0) [0|12851] "kg/h" Vector__XXX
 SG_ PEMSEngineFuelMassFlowRate : 0|16@1+ (0.02,0) [0|1285.1] "g/s" Vector__XXX
 SG_ VehicleFuelRate : 16|16@1+ (0.02,0) [0|1285.1] "g/s" Vector__XXX

BO_ 2566671614 SCROII3: 8 Vector__XXX
 SG_ NSCROptIdtOvdEvtsR : 24|8@1+ (1,0) [0|250] "count" Vector__XXX
 SG_ SCROprtrIndmntOvrrdEnl : 0|2@1+ (1,0) [0|3] "" Vector__XXX
 SG_ SCROprtrIndmntOvrrdTmRmnng : 8|16@1+ (1,0) [0|64255] "s" Vector__XXX
 SG_ TtlNmrfSCROprtrIndmntOvrrdEvnts : 32|16@1+ (1,0) [0|64255] "count" Vector__XXX

BO_ 2566671870 A2SCRDSI3: 8 Vector__XXX
 SG_ Aftrtrtmnt2DslExhstFldDsr2Prssr : 24|8@1+ (4,0) [0|1000] "kPa" Vector__XXX
 SG_ Aftrtrtmnt2DslExhstFldDsrPrssr : 0|8@1+ (4,0) [0|1000] "kPa" Vector__XXX
 SG_ Atttt2DsExstFdDs2AstPss : 8|8@1+ (8,0) [0|2000] "kPa" Vector__XXX
 SG_ Atttt2DsExstFdDs2Tpt : 16|8@1+ (1,-40) [-40|210] "degC" Vector__XXX

BO_ 2566672126 A1SCRDSI3: 8 Vector__XXX
 SG_ Aftrtrtmnt1DslExhstFldDsr2Prssr : 24|8@1+ (4,0) [0|1000] "kPa" Vector__XXX
 SG_ Aftrtrtmnt1DslExhstFldDsrPrssr : 0|8@1+ (4,0) [0|1000] "kPa" Vector__XXX
 SG_ Atttt1DsExstFdDs2AstPss : 8|8@1+ (8,0) [0|2000] "kPa" Vector__XXX
 SG_ Atttt1DsExstFdDs2Tpt : 16|8@1+ (1,-40) [-40|210] "degC" Vector__XXX

BO_ 2566672382 PWSI: 8 Vector__XXX
 SG_ PayloadWeightSensor1Status : 0|2@1+ (1,0) [0|3] "" Vector__XXX
 SG_ PayloadWeightSensor2Status : 2|2@1+ (1,0) [0|3] "" Vector__XXX
 SG_ PayloadWeightSensor3Status : 4|2@1+ (1,0) [0|3] "" Vector__XXX
 SG_ PayloadWeightSensor4Status : 6|2@1+ (1,0) [0|3] "" Vector__XXX
 SG_ PayloadWeightSensor5Status : 8|2@1+ (1,0) [0|3] "" Vector__XXX
 SG_ PayloadWeightSensor6Status : 10|2@1+ (1,0) [0|3] "" Vector__XXX
 SG_ PayloadWeightSensor7Status : 12|2@1+ (1,0) [0|3] "" Vector__XXX
 SG_ PayloadWeightSensor8Status : 14|2@1+ (1,0) [0|3] "" Vector__XXX

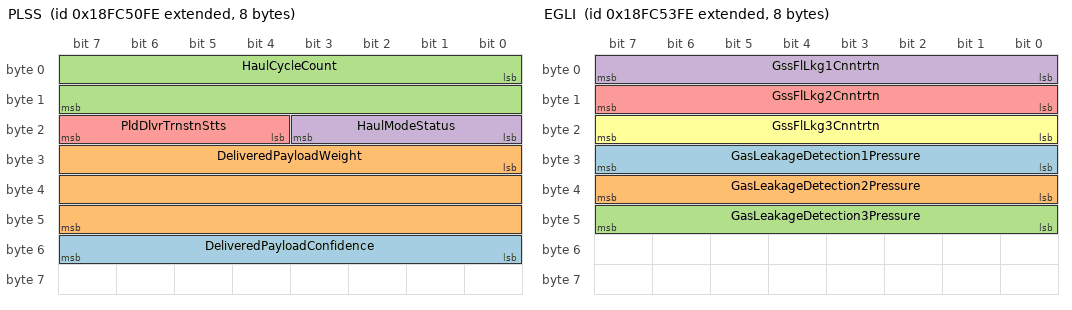
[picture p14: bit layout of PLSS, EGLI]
BO_ 2566672638 PLSS: 8 Vector__XXX
 SG_ DeliveredPayloadConfidence : 48|8@1+ (0.5,0) [0|125] "%" Vector__XXX
 SG_ DeliveredPayloadWeight : 24|24@1+ (2,0) [0|32899070] "kg" Vector__XXX
 SG_ HaulCycleCount : 0|16@1+ (1,0) [0|64255] "count" Vector__XXX
 SG_ HaulModeStatus : 16|4@1+ (1,0) [0|15] "" Vector__XXX
 SG_ PldDlvrTrnstnStts : 20|4@1+ (1,0) [0|15] "" Vector__XXX

BO_ 2566673406 EGLI: 8 Vector__XXX
 SG_ GasLeakageDetection1Pressure : 24|8@1+ (4,0) [0|1000] "kPa" Vector__XXX
 SG_ GasLeakageDetection2Pressure : 32|8@1+ (4,0) [0|1000] "kPa" Vector__XXX
 SG_ GasLeakageDetection3Pressure : 40|8@1+ (4,0) [0|1000] "kPa" Vector__XXX
 SG_ GssFlLkg1Cnntrtn : 0|8@1+ (0.5,0) [0|125] "%" Vector__XXX
 SG_ GssFlLkg2Cnntrtn : 8|8@1+ (0.5,0) [0|125] "%" Vector__XXX
 SG_ GssFlLkg3Cnntrtn : 16|8@1+ (0.5,0) [0|125] "%" Vector__XXX

BO_ 2566674174 SCROII2: 8 Vector__XXX
 SG_ AftrtrtmntSCRMlfntnTm : 0|32@1+ (1,0) [0|4211081215] "s" Vector__XXX
 SG_ SCROperatorInducementTotalTime : 32|32@1+ (1,0) [0|4211081215] "s" Vector__XXX

BO_ 2566674430 SCROII1: 8 Vector__XXX
 SG_ DslExhstFldQltMlfntnTm : 32|32@1+ (1,0) [0|4211081215] "s" Vector__XXX
 SG_ DslExhstFldTnk1EmptTm : 0|32@1+ (1,0) [0|4211081215] "s" Vector__XXX

BO_ 2566674686 TCI7: 8 Vector__XXX
 SG_ EngnTrhrgr2LOlPrssr : 0|8@1+ (4,0) [0|1000] "kPa" Vector__XXX
 SG_ EngnTrhrgr2OlTmprtr : 24|16@1+ (0.03125,-273) [-273|1734.96875] "degC" Vector__XXX
 SG_ EngnTrhrgr3LOlPrssr : 8|8@1+ (4,0) [0|1000] "kPa" Vector__XXX
 SG_ EngnTrhrgr4LOlPrssr : 16|8@1+ (4,0) [0|1000] "kPa" Vector__XXX

BO_ 2566675966 HVESSCFG: 200 Vector__XXX
 SG_ HVESSNominalVoltage : 0|16@1+ (0.05,0) [0|3212.75] "V" Vector__XXX
 SG_ HVESSRmmnddMnmmOprtngVltg : 16|16@1+ (0.05,0) [0|3212.75] "V" Vector__XXX
 SG_ HVESSRmmnddMxmmOprtngVltg : 32|16@1+ (0.05,0) [0|3212.75] "V" Vector__XXX
 SG_ HVESSRmmnddMnmmSttOfChrg : 48|16@1+ (0.0015625,0) [0|100.3984375] "%" Vector__XXX
 SG_ HVESSRmmnddMxmmSttOfChrg : 64|16@1+ (0.0015625,0) [0|100.3984375] "%" Vector__XXX
 SG_ HVESSRmmnddMxmmOprtngTmprtr : 80|16@1+ (0.03125,-273) [-273|1734.96875] "degC" Vector__XXX
 SG_ HVESSRmmnddMnmmOprtngTmprtr : 96|16@1+ (0.03125,-273) [-273|1734.96875] "degC" Vector__XXX
 SG_ HVESSCellMaximumVoltageLimit : 112|8@1+ (0.02044,0) [0|5.11] "V" Vector__XXX
 SG_ HVESSCellMinimumVoltageLimit : 120|8@1+ (0.02044,0) [0|5.11] "V" Vector__XXX
 SG_ HVESSNumberofHVESPsConfigured : 128|8@1+ (1,0) [0|250] "count" Vector__XXX

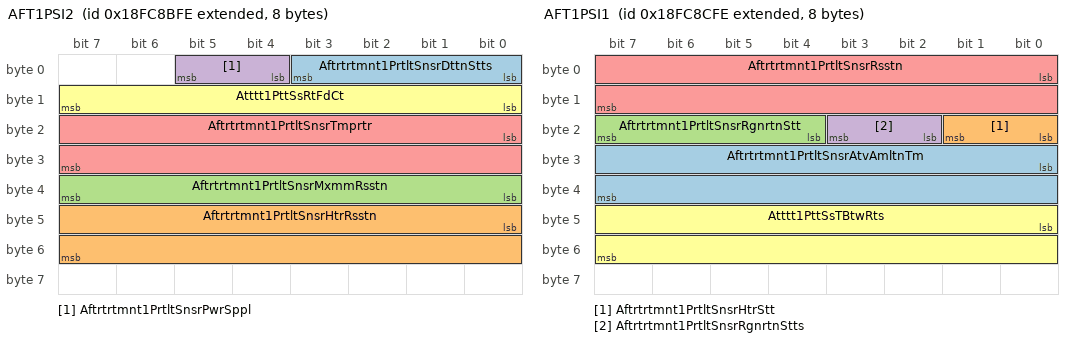
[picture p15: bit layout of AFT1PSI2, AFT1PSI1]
BO_ 2566687742 AFT1PSI2: 8 Vector__XXX
 SG_ Aftrtrtmnt1PrtltSnsrDttnStts : 0|4@1+ (1,0) [0|15] "" Vector__XXX
 SG_ Aftrtrtmnt1PrtltSnsrHtrRsstn : 40|16@1+ (0.1,0) [0|6425.5] "ohm" Vector__XXX
 SG_ Aftrtrtmnt1PrtltSnsrMxmmRsstn : 32|8@1+ (250,0) [0|62500] "kohm" Vector__XXX
 SG_ Aftrtrtmnt1PrtltSnsrPwrSppl : 4|2@1+ (1,0) [0|3] "" Vector__XXX
 SG_ Aftrtrtmnt1PrtltSnsrTmprtr : 16|16@1+ (0.03125,-273) [-273|1734.96875] "degC" Vector__XXX
 SG_ Atttt1PttSsRtFdCt : 8|8@1+ (1,0) [0|250] "count" Vector__XXX

BO_ 2566687998 AFT1PSI1: 8 Vector__XXX
 SG_ Aftrtrtmnt1PrtltSnsrAtvAmltnTm : 24|16@1+ (6,0) [0|385530] "s" Vector__XXX
 SG_ Aftrtrtmnt1PrtltSnsrHtrStt : 16|2@1+ (1,0) [0|3] "" Vector__XXX
 SG_ Aftrtrtmnt1PrtltSnsrRgnrtnStt : 20|4@1+ (1,0) [0|15] "" Vector__XXX
 SG_ Aftrtrtmnt1PrtltSnsrRgnrtnStts : 18|2@1+ (1,0) [0|3] "" Vector__XXX
 SG_ Aftrtrtmnt1PrtltSnsrRsstn : 0|16@1+ (1,0) [0|64255] "kohm" Vector__XXX
 SG_ Atttt1PttSsTBtwRts : 40|16@1+ (6,0) [0|385530] "s" Vector__XXX

BO_ 2566689278 EEN: 8 Vector__XXX
 SG_ EngineExhaustDesiredNOx : 16|16@1+ (0.05,-200) [-200|3012.75] "ppm" Vector__XXX
 SG_ EngineExhaustNOx : 0|16@1+ (0.05,-200) [-200|3012.75] "ppm" Vector__XXX
 SG_ EngnExhstNOxSnsrPwrSppl : 32|2@1+ (1,0) [0|3] "" Vector__XXX

BO_ 2566689534 AFR: 8 Vector__XXX
 SG_ EngineMainChamberAirFuelRatio : 0|16@1+ (0.001,0) [0|64.255] "Ratio" Vector__XXX
 SG_ EnginePrechamberAirFuelRatio : 32|16@1+ (0.001,0) [0|64.255] "Ratio" Vector__XXX
 SG_ EngnMnChmrDsrdArFlRt : 16|16@1+ (0.001,0) [0|64.255] "Ratio" Vector__XXX
 SG_ EngnPrhmrDsrdArFlRt : 48|16@1+ (0.001,0) [0|64.255] "Ratio" Vector__XXX

BO_ 2566689790 GFP2: 8 Vector__XXX
 SG_ EngnMnChmrFlAsltPrssr : 0|16@1+ (0.1,0) [0|6425.5] "kPa" Vector__XXX
 SG_ EngnMnChmrFlDsrdAsltPrssr : 16|16@1+ (0.1,0) [0|6425.5] "kPa" Vector__XXX
 SG_ EngnPrhmrFlAsltPrssr : 32|16@1+ (0.1,0) [0|6425.5] "kPa" Vector__XXX
 SG_ EngnPrhmrFlDsrdAsltPrssr : 48|16@1+ (0.1,0) [0|6425.5] "kPa" Vector__XXX

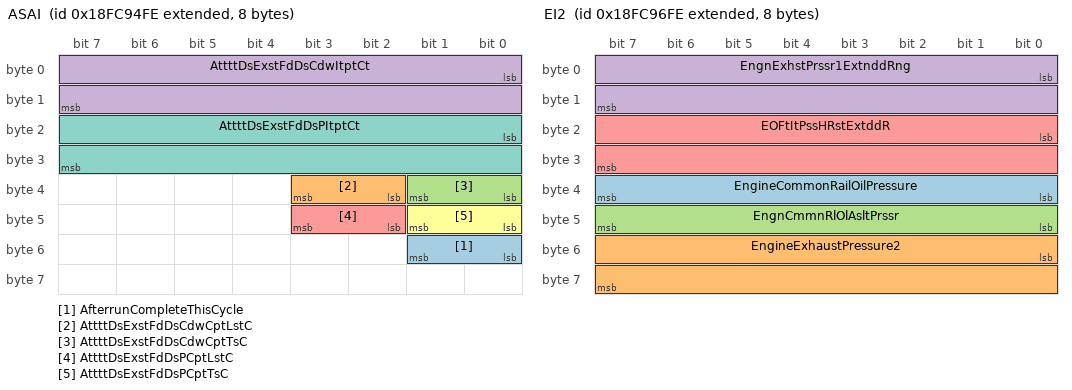
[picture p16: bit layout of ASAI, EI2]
BO_ 2566690046 ASAI: 8 Vector__XXX
 SG_ AfterrunCompleteThisCycle : 48|2@1+ (1,0) [0|3] "" Vector__XXX
 SG_ AttttDsExstFdDsCdwCptLstC : 34|2@1+ (1,0) [0|3] "" Vector__XXX
 SG_ AttttDsExstFdDsCdwCptTsC : 32|2@1+ (1,0) [0|3] "" Vector__XXX
 SG_ AttttDsExstFdDsCdwItptCt : 0|16@1+ (1,0) [0|64255] "count" Vector__XXX
 SG_ AttttDsExstFdDsPCptLstC : 42|2@1+ (1,0) [0|3] "" Vector__XXX
 SG_ AttttDsExstFdDsPCptTsC : 40|2@1+ (1,0) [0|3] "" Vector__XXX
 SG_ AttttDsExstFdDsPItptCt : 16|16@1+ (1,0) [0|64255] "count" Vector__XXX

BO_ 2566690558 EI2: 8 Vector__XXX
 SG_ EngineCommonRailOilPressure : 32|8@1+ (4,0) [0|1000] "kPa" Vector__XXX
 SG_ EngineExhaustPressure2 : 48|16@1+ (0.0078125,-250) [-250|251.99] "kPa" Vector__XXX
 SG_ EngnCmmnRlOlAsltPrssr : 40|8@1+ (4,0) [0|1000] "kPa" Vector__XXX
 SG_ EngnExhstPrssr1ExtnddRng : 0|16@1+ (0.125,0) [0|8031.875] "kPa" Vector__XXX
 SG_ EOFtItPssHRstExtddR : 16|16@1+ (0.1,0) [0|6425.5] "kPa" Vector__XXX

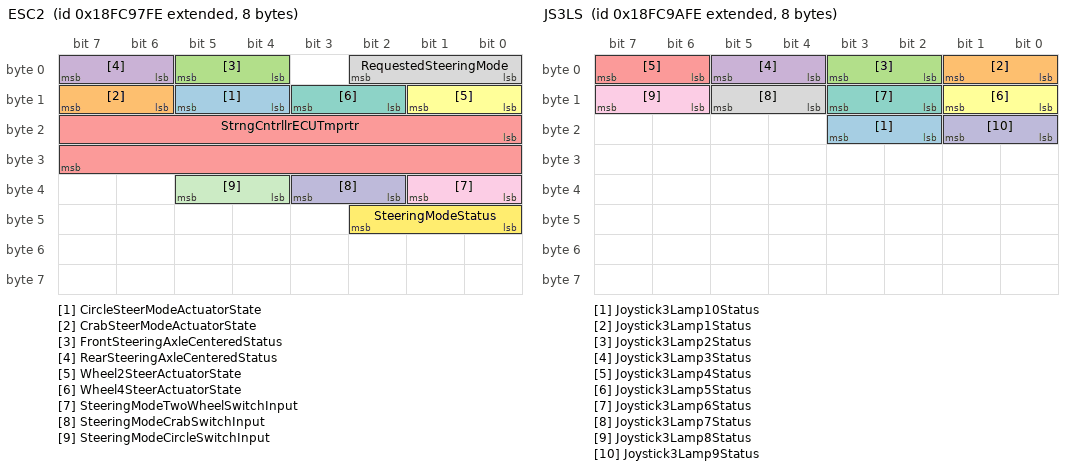
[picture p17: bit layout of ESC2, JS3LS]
BO_ 2566690814 ESC2: 8 Vector__XXX
 SG_ CircleSteerModeActuatorState : 12|2@1+ (1,0) [0|3] "" Vector__XXX
 SG_ CrabSteerModeActuatorState : 14|2@1+ (1,0) [0|3] "" Vector__XXX
 SG_ FrontSteeringAxleCenteredStatus : 4|2@1+ (1,0) [0|3] "" Vector__XXX
 SG_ RearSteeringAxleCenteredStatus : 6|2@1+ (1,0) [0|3] "" Vector__XXX
 SG_ StrngCntrllrECUTmprtr : 16|16@1+ (0.03125,-273) [-273|1734.96875] "degC" Vector__XXX
 SG_ Wheel2SteerActuatorState : 8|2@1+ (1,0) [0|3] "" Vector__XXX
 SG_ Wheel4SteerActuatorState : 10|2@1+ (1,0) [0|3] "" Vector__XXX
 SG_ RequestedSteeringMode : 0|3@1+ (1,0) [0|7] "" Vector__XXX
 SG_ SteeringModeTwoWheelSwitchInput : 32|2@1+ (1,0) [0|3] "" Vector__XXX
 SG_ SteeringModeCrabSwitchInput : 34|2@1+ (1,0) [0|3] "" Vector__XXX
 SG_ SteeringModeCircleSwitchInput : 36|2@1+ (1,0) [0|3] "" Vector__XXX
 SG_ SteeringModeStatus : 40|3@1+ (1,0) [0|7] "" Vector__XXX

BO_ 2566691326 AUI: 200 Vector__XXX
 SG_ AssemblyUnitIdentification : 8|8@1+ (1,0) [0|255] "ASCII" Vector__XXX
 SG_ NmrfAssmlUntIdntftnFlds : 0|8@1+ (1,0) [0|250] "count" Vector__XXX

BO_ 2566691582 JS3LS: 8 Vector__XXX
 SG_ Joystick3Lamp10Status : 18|2@1+ (1,0) [0|3] "" Vector__XXX
 SG_ Joystick3Lamp1Status : 0|2@1+ (1,0) [0|3] "" Vector__XXX
 SG_ Joystick3Lamp2Status : 2|2@1+ (1,0) [0|3] "" Vector__XXX
 SG_ Joystick3Lamp3Status : 4|2@1+ (1,0) [0|3] "" Vector__XXX
 SG_ Joystick3Lamp4Status : 6|2@1+ (1,0) [0|3] "" Vector__XXX
 SG_ Joystick3Lamp5Status : 8|2@1+ (1,0) [0|3] "" Vector__XXX
 SG_ Joystick3Lamp6Status : 10|2@1+ (1,0) [0|3] "" Vector__XXX
 SG_ Joystick3Lamp7Status : 12|2@1+ (1,0) [0|3] "" Vector__XXX
 SG_ Joystick3Lamp8Status : 14|2@1+ (1,0) [0|3] "" Vector__XXX
 SG_ Joystick3Lamp9Status : 16|2@1+ (1,0) [0|3] "" Vector__XXX

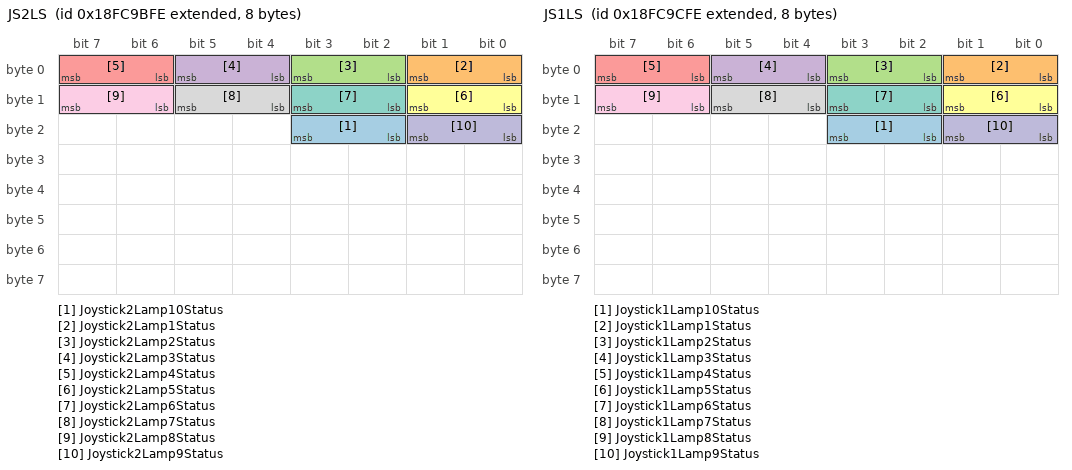
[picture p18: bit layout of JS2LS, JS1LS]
BO_ 2566691838 JS2LS: 8 Vector__XXX
 SG_ Joystick2Lamp10Status : 18|2@1+ (1,0) [0|3] "" Vector__XXX
 SG_ Joystick2Lamp1Status : 0|2@1+ (1,0) [0|3] "" Vector__XXX
 SG_ Joystick2Lamp2Status : 2|2@1+ (1,0) [0|3] "" Vector__XXX
 SG_ Joystick2Lamp3Status : 4|2@1+ (1,0) [0|3] "" Vector__XXX
 SG_ Joystick2Lamp4Status : 6|2@1+ (1,0) [0|3] "" Vector__XXX
 SG_ Joystick2Lamp5Status : 8|2@1+ (1,0) [0|3] "" Vector__XXX
 SG_ Joystick2Lamp6Status : 10|2@1+ (1,0) [0|3] "" Vector__XXX
 SG_ Joystick2Lamp7Status : 12|2@1+ (1,0) [0|3] "" Vector__XXX
 SG_ Joystick2Lamp8Status : 14|2@1+ (1,0) [0|3] "" Vector__XXX
 SG_ Joystick2Lamp9Status : 16|2@1+ (1,0) [0|3] "" Vector__XXX

BO_ 2566692094 JS1LS: 8 Vector__XXX
 SG_ Joystick1Lamp10Status : 18|2@1+ (1,0) [0|3] "" Vector__XXX
 SG_ Joystick1Lamp1Status : 0|2@1+ (1,0) [0|3] "" Vector__XXX
 SG_ Joystick1Lamp2Status : 2|2@1+ (1,0) [0|3] "" Vector__XXX
 SG_ Joystick1Lamp3Status : 4|2@1+ (1,0) [0|3] "" Vector__XXX
 SG_ Joystick1Lamp4Status : 6|2@1+ (1,0) [0|3] "" Vector__XXX
 SG_ Joystick1Lamp5Status : 8|2@1+ (1,0) [0|3] "" Vector__XXX
 SG_ Joystick1Lamp6Status : 10|2@1+ (1,0) [0|3] "" Vector__XXX
 SG_ Joystick1Lamp7Status : 12|2@1+ (1,0) [0|3] "" Vector__XXX
 SG_ Joystick1Lamp8Status : 14|2@1+ (1,0) [0|3] "" Vector__XXX
 SG_ Joystick1Lamp9Status : 16|2@1+ (1,0) [0|3] "" Vector__XXX

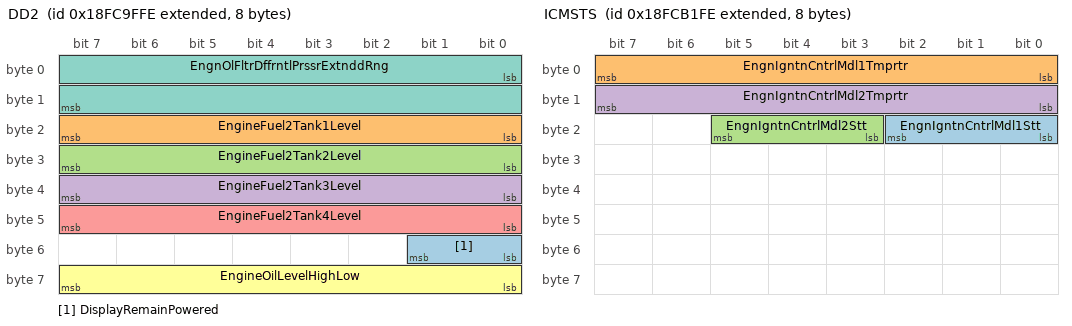
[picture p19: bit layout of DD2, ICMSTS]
BO_ 2566692862 DD2: 8 Vector__XXX
 SG_ DisplayRemainPowered : 48|2@1+ (1,0) [0|3] "" Vector__XXX
 SG_ EngineFuel2Tank1Level : 16|8@1+ (0.4,0) [0|100] "%" Vector__XXX
 SG_ EngineFuel2Tank2Level : 24|8@1+ (0.4,0) [0|100] "%" Vector__XXX
 SG_ EngineFuel2Tank3Level : 32|8@1+ (0.4,0) [0|100] "%" Vector__XXX
 SG_ EngineFuel2Tank4Level : 40|8@1+ (0.4,0) [0|100] "%" Vector__XXX
 SG_ EngineOilLevelHighLow : 56|8@1+ (0.5,-62.5) [-62.5|62.5] "l" Vector__XXX
 SG_ EngnOlFltrDffrntlPrssrExtnddRng : 0|16@1+ (0.0078125,-250) [-250|251.99] "kPa" Vector__XXX

BO_ 2566697470 ICMSTS: 8 Vector__XXX
 SG_ EngnIgntnCntrlMdl1Stt : 16|3@1+ (1,0) [0|7] "" Vector__XXX
 SG_ EngnIgntnCntrlMdl1Tmprtr : 0|8@1+ (1,-40) [-40|210] "degC" Vector__XXX
 SG_ EngnIgntnCntrlMdl2Stt : 19|3@1+ (1,0) [0|7] "" Vector__XXX
 SG_ EngnIgntnCntrlMdl2Tmprtr : 8|8@1+ (1,-40) [-40|210] "degC" Vector__XXX

CM_ BO_ 2566648318 "Oil Debris Monitoring System Status";
CM_ SG_ 2566648318 OlDrsMntrEltrnsTmprtrStts "Oil Debris Monitor Electronics Temperature Status: Temperature indicator for the Oil Debris Monitor (ODM) Electronics.00b = Acceptable temperature01b = Temperature is outside of limits10b = Reserved11b = Not available";
CM_ SG_ 2566648318 OlDrsMntrEnvrnmntStts "Oil Debris Monitor Environment Status: Status of the electrical and mechanical environment surrounding the Oil Debris Monitor (ODM) Sensor.00b = Acceptable environment01b = Excessive noise in signal10b = Reserved11b = Not available";
CM_ SG_ 2566648318 OlDrsMntrSgnlPrssngEltrnsStts "Oil Debris Monitor Signal Processing Electronics Status: Status of the Oil Debris Monitor (ODM) signal processing electronics.00b = Electronics functioning normally01b = Fault in electronics10b = Reserved11b = Not available";
CM_ SG_ 2566648318 OlDrsMntrSnsngElmntStts "Oil Debris Monitor Sensing Element Status: Status of the Oil Debris Monitor (ODM) sensing element.00b = Sensing element OK01b = Fault with sensing element10b = Reserved11b = Not available";
CM_ SG_ 2566648318 OlDrsMntrSttsIdntftnNmr "Oil Debris Monitor Status Identification Number: Identification number of the Oil Debris Monitoring (ODM) sensor being reported. Identification numbers are application specific.";
CM_ SG_ 2566648318 OlDrsMntrTtlnmrfSnsrs "Oil Debris Monitor Total number of Sensors: Total number of Oil Debris Monitoring (ODM) sensors configured for this application.";
CM_ BO_ 2566649086 "Aftertreatment 2 Diesel Oxidation Catalyst 2";
CM_ SG_ 2566649086 Atttt2DOCIttDPFOttDtPss "Aftertreatment 2 DOC Intake to DPF Outlet Delta Pressure: Aftertreatment 2 Diesel Oxidation Catalyst intake to Diesel Particulate Filter outlet differential pressure in exhaust bank 1.";
CM_ SG_ 2566649086 Atttt2DsOxdtCtstItPss "Aftertreatment 2 Diesel Oxidation Catalyst Intake Pressure: Aftertreatment 2 Diesel Oxidation Catalyst absolute pressure measured at the DOC intake in exhaust bank 1.";
CM_ SG_ 2566649086 Atttt2DsOxdtCtstOttPss "Aftertreatment 2 Diesel Oxidation Catalyst Outlet Pressure: Aftertreatment 2 Diesel Oxidation Catalyst absolute pressure measured at the DOC outlet in exhaust bank 1.";
CM_ BO_ 2566649342 "Aftertreatment 1 Diesel Oxidation Catalyst 2";
CM_ SG_ 2566649342 Atttt1DOCIttDPFOttDtPss "Aftertreatment 1 DOC Intake to DPF Outlet Delta Pressure: Aftertreatment 1 Diesel Oxidation Catalyst intake to Diesel Particulate Filter outlet differential pressure in exhaust bank 1.";
CM_ SG_ 2566649342 Atttt1DsOxdtCtstItPss "Aftertreatment 1 Diesel Oxidation Catalyst Intake Pressure: Aftertreatment 1 Diesel Oxidation Catalyst absolute pressure measured at the DOC intake in exhaust bank 1.";
CM_ SG_ 2566649342 Atttt1DsOxdtCtstOttPss "Aftertreatment 1 Diesel Oxidation Catalyst Outlet Pressure: Aftertreatment 1 Diesel Oxidation Catalyst absolute pressure measured at the DOC outlet in exhaust bank 1.";
CM_ BO_ 2566649598 "Vehicle Position 2";
CM_ SG_ 2566649598 HorizontalDilutionofPrecision "Horizontal Dilution of Precision: Provides the dilution of precision in the horizontal (X-Y plane axis) direction as calculated by the positioning and locating system receiver. The dilution of precision factor is calculated from the observed position...";
CM_ SG_ 2566649598 PositionDilutionofPrecision "Position Dilution of Precision: Provides the dilution of precision for the overall position (X-Y-Z coordinate system) as calculated by the positioning and locating system receiver. The dilution of precision factor is calculated from the observed sate...";
CM_ SG_ 2566649598 TimeDilutionofPrecision "Time Dilution of Precision: Provides the estimated receiver clock error as calculated by the positioning and locating system receiver from the satellites’ clock data. The dilution of precision factor is calculated from the observed satellites (at lea...";
CM_ SG_ 2566649598 TotalNumberofSatellitesinView "Total Number of Satellites in View: Indicates the number of satellites in view of the positioning and locating system receiver.";
CM_ SG_ 2566649598 VerticalDilutionofPrecision "Vertical Dilution of Precision: Provides the dilution of precision in the vertical (Z axis) direction as calculated by the positioning and locating system receiver. The dilution of precision factor is calculated from the observed positions of the obs...";
CM_ BO_ 2566649854 "Electrified Accessory Propulsion Motor Coolant Fan 3 Status";
CM_ SG_ 2566649854 PpsMtCtF3CtCdStts "Propulsion Motor Coolant Fan 3 Controller Command Status: Indicates the source of the speed command to the Propulsion Motor Coolant Fan 3 system or component.00b is communicated when the controller is self-controlled  (e.g. based on a temperature sen...";
CM_ SG_ 2566649854 PpsMtCtF3CtSttsRsCd "Propulsion Motor Coolant Fan 3 Controller Status Reason Code: Provides the reason code describing the unique failure of the Propulsion Motor Coolant Fan 3 system or component.If a detailed reason code is not used by the supporting application, or thi...";
CM_ SG_ 2566649854 PropulsionMotorCoolantFan3Power "Propulsion Motor Coolant Fan 3 Power: Calculated electrical power consumed by the Propulsion Motor Coolant Fan 3.";
CM_ SG_ 2566649854 PrplsnMtrClntFn3CntrlTmprtr "Propulsion Motor Coolant Fan 3 Control Temperature: A temperature measured and reported by the device.  It may be used for direct or remote (by another controller) control of the Fan 3.  For example, this may be the temperature of the fluid flowing t...";
CM_ SG_ 2566649854 PrplsnMtrClntFn3EnlStts "Propulsion Motor Coolant Fan 3 Enable Status: Enable and direction status of the Propulsion Motor Coolant Fan 3 system or component.00b = Accessory Motor Off01b = Accessory Motor On - Normal, Forward, or Default Direction10b = Accessory Motor On - Re...";
CM_ SG_ 2566649854 PrplsnMtrClntFn3MtrSpd "Propulsion Motor Coolant Fan 3 Motor Speed: Motor Speed of the Propulsion Motor Coolant Fan 3. ";
CM_ SG_ 2566649854 PrplsnMtrClntFn3OprtngStts "Propulsion Motor Coolant Fan 3 Operating Status: Indicates the operating status of the Propulsion Motor Coolant Fan 3 system or component.This parameter is used to inform other devices that this system or component is no longer performing to its oper...";
CM_ SG_ 2566649854 PrplsnMtrClntFn3SrvIndtr "Propulsion Motor Coolant Fan 3 Service Indicator: Indicates that service is required for the Propulsion Motor Coolant Fan 3 system or component.An active indication may convey a need for component replacement or periodic service.  The Propulsion Moto...";
CM_ BO_ 2566650110 "Electrified Accessory Propulsion Motor Coolant Fan 2 Status";
CM_ SG_ 2566650110 PpsMtCtF2CtCdStts "Propulsion Motor Coolant Fan 2 Controller Command Status: Indicates the source of the speed command to the Propulsion Motor Coolant Fan 2 system or component.00b is communicated when the controller is self-controlled  (e.g. based on a temperature sen...";
CM_ SG_ 2566650110 PpsMtCtF2CtSttsRsCd "Propulsion Motor Coolant Fan 2 Controller Status Reason Code: Provides the reason code describing the unique failure of the Propulsion Motor Coolant Fan 2 system or component.If a detailed reason code is not used by the supporting application, or thi...";
CM_ SG_ 2566650110 PropulsionMotorCoolantFan2Power "Propulsion Motor Coolant Fan 2 Power: Calculated electrical power consumed by the Propulsion Motor Coolant Fan 2.";
CM_ SG_ 2566650110 PrplsnMtrClntFn2CntrlTmprtr "Propulsion Motor Coolant Fan 2 Control Temperature: A temperature measured and reported by the device.  It may be used for direct or remote (by another controller) control of the Fan 2.  For example, this may be the temperature of the fluid flowing t...";
CM_ SG_ 2566650110 PrplsnMtrClntFn2EnlStts "Propulsion Motor Coolant Fan 2 Enable Status: Enable and direction status of the Propulsion Motor Coolant Fan 2 system or component.00b = Accessory Motor Off01b = Accessory Motor On - Normal, Forward, or Default Direction10b = Accessory Motor On - Re...";
CM_ SG_ 2566650110 PrplsnMtrClntFn2MtrSpd "Propulsion Motor Coolant Fan 2 Motor Speed: Motor Speed of the Propulsion Motor Coolant Fan 2. ";
CM_ SG_ 2566650110 PrplsnMtrClntFn2OprtngStts "Propulsion Motor Coolant Fan 2 Operating Status: Indicates the operating status of the Propulsion Motor Coolant Fan 2 system or component.This parameter is used to inform other devices that this system or component is no longer performing to its oper...";
CM_ SG_ 2566650110 PrplsnMtrClntFn2SrvIndtr "Propulsion Motor Coolant Fan 2 Service Indicator: Indicates that service is required for the Propulsion Motor Coolant Fan 2 system or component.An active indication may convey a need for component replacement or periodic service.  The Propulsion Moto...";
CM_ BO_ 2566650366 "Electrified Accessory Propulsion Motor Coolant Fan 1 Status";
CM_ SG_ 2566650366 PpsMtCtF1CtCdStts "Propulsion Motor Coolant Fan 1 Controller Command Status: Indicates the source of the speed command to the Propulsion Motor Coolant Fan 1 system or component.00b is communicated when the controller is self-controlled  (e.g. based on a temperature sen...";
CM_ SG_ 2566650366 PpsMtCtF1CtSttsRsCd "Propulsion Motor Coolant Fan 1 Controller Status Reason Code: Provides the reason code describing the unique failure of the Propulsion Motor Coolant Fan 1 system or component.If a detailed reason code is not used by the supporting application, or thi...";
CM_ SG_ 2566650366 PropulsionMotorCoolantFan1Power "Propulsion Motor Coolant Fan 1 Power: Calculated electrical power consumed by the Propulsion Motor Coolant Fan 1.";
CM_ SG_ 2566650366 PrplsnMtrClntFn1CntrlTmprtr "Propulsion Motor Coolant Fan 1 Control Temperature: A temperature measured and reported by the device.  It may be used for direct or remote (by another controller) control of the Fan 1.  For example, this may be the temperature of the fluid flowing t...";
CM_ SG_ 2566650366 PrplsnMtrClntFn1EnlStts "Propulsion Motor Coolant Fan 1 Enable Status: Enable and direction status of the Propulsion Motor Coolant Fan 1 system or component.00b = Accessory Motor Off01b = Accessory Motor On - Normal, Forward, or Default Direction10b = Accessory Motor On - Re...";
CM_ SG_ 2566650366 PrplsnMtrClntFn1MtrSpd "Propulsion Motor Coolant Fan 1 Motor Speed: Motor Speed of the Propulsion Motor Coolant Fan 1. ";
CM_ SG_ 2566650366 PrplsnMtrClntFn1OprtngStts "Propulsion Motor Coolant Fan 1 Operating Status: Indicates the operating status of the Propulsion Motor Coolant Fan 1 system or component.This parameter is used to inform other devices that this system or component is no longer performing to its oper...";
CM_ SG_ 2566650366 PrplsnMtrClntFn1SrvIndtr "Propulsion Motor Coolant Fan 1 Service Indicator: Indicates that service is required for the Propulsion Motor Coolant Fan 1 system or component.An active indication may convey a need for component replacement or periodic service.  The Propulsion Moto...";
CM_ BO_ 2566650622 "Electrified Accessory Power Electronics Coolant Fan 3 Status";
CM_ SG_ 2566650622 PwEtsCtF3CtCdStts "Power Electronics Coolant Fan 3 Controller Command Status: Indicates the source of the speed command to the Power Electronics Coolant Fan 3 system or component.00b is communicated when the controller is self-controlled  (e.g. based on a temperature s...";
CM_ SG_ 2566650622 PwEtsCtF3CtSttsRsCd "Power Electronics Coolant Fan 3 Controller Status Reason Code: Provides the reason code describing the unique failure of the Power Electronics Coolant Fan 3 system or component.  If a detailed reason code is not used by the supporting application, or...";
CM_ SG_ 2566650622 PwrEltrnsClntFn3CntrlTmprtr "Power Electronics Coolant Fan 3 Control Temperature: A temperature measured and reported by the device.  It may be used for direct or remote (by another controller) control of the Fan 3.  For example, this may be the temperature of the fluid flowing ...";
CM_ SG_ 2566650622 PwrEltrnsClntFn3EnlStts "Power Electronics Coolant Fan 3 Enable Status: Enable and direction status of the Power Electronics Coolant Fan 3 system or component.00b = Accessory Motor Off01b = Accessory Motor On - Normal, Forward, or Default Direction10b = Accessory Motor On - ...";
CM_ SG_ 2566650622 PwrEltrnsClntFn3MtrSpd "Power Electronics Coolant Fan 3 Motor Speed: Motor Speed of the Power Electronics Coolant Fan 3. ";
CM_ SG_ 2566650622 PwrEltrnsClntFn3OprtngStts "Power Electronics Coolant Fan 3 Operating Status: Indicates the operating status of the Power Electronics Coolant Fan 3 system or component.This parameter is used to inform other devices that this system or component is no longer performing to its op...";
CM_ SG_ 2566650622 PwrEltrnsClntFn3Pwr "Power Electronics Coolant Fan 3 Power: Calculated electrical power consumed by the Power Electronics Coolant Fan 3.";
CM_ SG_ 2566650622 PwrEltrnsClntFn3SrvIndtr "Power Electronics Coolant Fan 3 Service Indicator: Indicates that service is required for the Power Electronics Coolant Fan 3 system or component.An active indication may convey a need for component replacement or periodic service.  The Power Electro...";
CM_ BO_ 2566650878 "Electrified Accessory Power Electronics Coolant Fan 2 Status";
CM_ SG_ 2566650878 PwEtsCtF2CtCdStts "Power Electronics Coolant Fan 2 Controller Command Status: Indicates the source of the speed command to the Power Electronics Coolant Fan 2 system or component.00b is communicated when the controller is self-controlled  (e.g. based on a temperature s...";
CM_ SG_ 2566650878 PwEtsCtF2CtSttsRsCd "Power Electronics Coolant Fan 2 Controller Status Reason Code: Provides the reason code describing the unique failure of the Power Electronics Coolant Fan 2 system or component.If a detailed reason code is not used by the supporting application, or t...";
CM_ SG_ 2566650878 PwrEltrnsClntFn2CntrlTmprtr "Power Electronics Coolant Fan 2 Control Temperature: A temperature measured and reported by the device.  It may be used for direct or remote (by another controller) control of the Fan 2.  For example, this may be the temperature of the fluid flowing ...";
CM_ SG_ 2566650878 PwrEltrnsClntFn2EnlStts "Power Electronics Coolant Fan 2 Enable Status: Enable and direction status of the Power Electronics Coolant Fan 2 system or component.00b = Accessory Motor Off01b = Accessory Motor On - Normal, Forward, or Default Direction10b = Accessory Motor On - ...";
CM_ SG_ 2566650878 PwrEltrnsClntFn2MtrSpd "Power Electronics Coolant Fan 2 Motor Speed: Motor Speed of the Power Electronics Coolant Fan 2. ";
CM_ SG_ 2566650878 PwrEltrnsClntFn2OprtngStts "Power Electronics Coolant Fan 2 Operating Status: Indicates the operating status of the Power Electronics Coolant Fan 2 system or component.This parameter is used to inform other devices that this system or component is no longer performing to its op...";
CM_ SG_ 2566650878 PwrEltrnsClntFn2Pwr "Power Electronics Coolant Fan 2 Power: Calculated electrical power consumed by the Power Electronics Coolant Fan 2.";
CM_ SG_ 2566650878 PwrEltrnsClntFn2SrvIndtr "Power Electronics Coolant Fan 2 Service Indicator: Indicates that service is required for the Power Electronics Coolant Fan 2 system or component.An active indication may convey a need for component replacement or periodic service.  The Power Electro...";
CM_ BO_ 2566651134 "Electrified Accessory Power Electronics Coolant Fan 1 Status";
CM_ SG_ 2566651134 PwEtsCtF1CtCdStts "Power Electronics Coolant Fan 1 Controller Command Status: Indicates the source of the speed command to the Power Electronics Coolant Fan 1 system or component.00b is communicated when the controller is self-controlled  (e.g. based on a temperature s...";
CM_ SG_ 2566651134 PwEtsCtF1CtSttsRsCd "Power Electronics Coolant Fan 1 Controller Status Reason Code: Provides the reason code describing the unique failure of the Power Electronics Coolant Fan 1 system or component.If a detailed reason code is not used by the supporting application, or t...";
CM_ SG_ 2566651134 PwrEltrnsClntFn1CntrlTmprtr "Power Electronics Coolant Fan 1 Control Temperature: A temperature measured and reported by the device.  It may be used for direct or remote (by another controller) control of the Fan 1.  For example, this may be the temperature of the fluid flowing ...";
CM_ SG_ 2566651134 PwrEltrnsClntFn1EnlStts "Power Electronics Coolant Fan 1 Enable Status: Enable and direction status of the Power Electronics Coolant Fan 1 system or component.00b = Accessory Motor Off01b = Accessory Motor On - Normal, Forward, or Default Direction10b = Accessory Motor On - ...";
CM_ SG_ 2566651134 PwrEltrnsClntFn1MtrSpd "Power Electronics Coolant Fan 1 Motor Speed: Motor Speed of the Power Electronics Coolant Fan 1. ";
CM_ SG_ 2566651134 PwrEltrnsClntFn1OprtngStts "Power Electronics Coolant Fan 1 Operating Status: Indicates the operating status of the Power Electronics Coolant Fan 1 system or component.This parameter is used to inform other devices that this system or component is no longer performing to its op...";
CM_ SG_ 2566651134 PwrEltrnsClntFn1Pwr "Power Electronics Coolant Fan 1 Power: Calculated electrical power consumed by the Power Electronics Coolant Fan 1.";
CM_ SG_ 2566651134 PwrEltrnsClntFn1SrvIndtr "Power Electronics Coolant Fan 1 Service Indicator: Indicates that service is required for the Power Electronics Coolant Fan 1 system or component.An active indication may convey a need for component replacement or periodic service.  The Power Electro...";
CM_ BO_ 2566651390 "Electrified Accessory Propulsion Motor Oil Pump Status";
CM_ SG_ 2566651390 PropulsionMotorOilPumpPower "Propulsion Motor Oil Pump Power: Calculated electrical power consumed by the Propulsion Motor Oil Pump.";
CM_ SG_ 2566651390 PrplsnMtrOlPmpCntrllrCmmndStts "Propulsion Motor Oil Pump Controller Command Status: Indicates the source of the speed command to the Propulsion Motor Oil Pump system or component.00b is communicated when the controller is self-controlled  (e.g. based on a temperature sensor).01b i...";
CM_ SG_ 2566651390 PrplsnMtrOlPmpCntrllrSttsRsnCd "Propulsion Motor Oil Pump Controller Status Reason Code: Provides the reason code describing the unique failure of the Propulsion Motor Oil Pump system or component.If a detailed reason code is not used by the supporting application, or this reason c...";
CM_ SG_ 2566651390 PrplsnMtrOlPmpCntrlTmprtr "Propulsion Motor Oil Pump Control Temperature: A temperature measured and reported by the device.  It may be used for direct or remote (e.g. by another controller) control of the pump.  For example, this may be the temperature of the fluid flowing th...";
CM_ SG_ 2566651390 PrplsnMtrOlPmpEnlStts "Propulsion Motor Oil Pump Enable Status: Enable and direction status of the Propulsion Motor Oil Pump system or component.00b = Accessory Motor Off01b = Accessory Motor On - Normal, Forward, or Default Direction10b = Accessory Motor On - Reverse Dire...";
CM_ SG_ 2566651390 PrplsnMtrOlPmpMtrSpd "Propulsion Motor Oil Pump Motor Speed: Motor Speed of the Propulsion Motor Oil Pump. ";
CM_ SG_ 2566651390 PrplsnMtrOlPmpOprtngStts "Propulsion Motor Oil Pump Operating Status: Indicates the operating status of the Propulsion Motor Oil Pump system or component.This parameter is used to inform other devices that this system or component is no longer performing to its operational ca...";
CM_ SG_ 2566651390 PrplsnMtrOlPmpSrvIndtr "Propulsion Motor Oil Pump Service Indicator: Indicates that service is required for the Propulsion Motor Oil Pump system or component.An active indication may convey a need for component replacement or periodic service.  The Propulsion Motor Oil Pump...";
CM_ BO_ 2566651646 "Electrified Accessory Propulsion Motor Coolant Pump Status";
CM_ SG_ 2566651646 PpsMtCtPpCtCdStts "Propulsion Motor Coolant Pump Controller Command Status: Indicates the source of the speed command to the Propulsion Motor Coolant Pump system or component.00b is communicated when the controller is self-controlled  (e.g. based on a temperature senso...";
CM_ SG_ 2566651646 PpsMtCtPpCtSttsRsCd "Propulsion Motor Coolant Pump Controller Status Reason Code: Provides the reason code describing the unique failure of the Propulsion Motor Coolant Pump system or component.If a detailed reason code is not used by the supporting application, or this ...";
CM_ SG_ 2566651646 PropulsionMotorCoolantPumpPower "Propulsion Motor Coolant Pump Power: Calculated electrical power consumed by the Propulsion Motor Coolant Pump.";
CM_ SG_ 2566651646 PrplsnMtrClntPmpCntrlTmprtr "Propulsion Motor Coolant Pump Control Temperature: A temperature measured and reported by the device.  It may be used for direct or remote (e.g. by another controller) control of the pump.  For example, this may be the temperature of the fluid flowin...";
CM_ SG_ 2566651646 PrplsnMtrClntPmpEnlStts "Propulsion Motor Coolant Pump Enable Status: Enable and direction status of the Propulsion Motor Coolant Pump system or component.00b = Accessory Motor Off01b = Accessory Motor On - Normal, Forward, or Default Direction10b = Accessory Motor On - Reve...";
CM_ SG_ 2566651646 PrplsnMtrClntPmpMtrSpd "Propulsion Motor Coolant Pump Motor Speed: Motor Speed of the Propulsion Motor Coolant Pump. ";
CM_ SG_ 2566651646 PrplsnMtrClntPmpOprtngStts "Propulsion Motor Coolant Pump Operating Status: Indicates the operating status of the Propulsion Motor Coolant Pump system or component.This parameter is used to inform other devices that this system or component is no longer performing to its operat...";
CM_ SG_ 2566651646 PrplsnMtrClntPmpSrvIndtr "Propulsion Motor Coolant Pump Service Indicator: Indicates that service is required for the Propulsion Motor Coolant Pump system or component.An active indication may convey a need for component replacement or periodic service.  The Propulsion Motor ...";
CM_ BO_ 2566651902 "Electrified Accessory Power Electronics Coolant Pump Status";
CM_ SG_ 2566651902 PwEtsCtPpCtCdStts "Power Electronics Coolant Pump Controller Command Status: Indicates the source of the speed command to the Power Electronics Coolant Pump system or component.00b is communicated when the controller is self-controlled  (e.g. based on a temperature sen...";
CM_ SG_ 2566651902 PwEtsCtPpCtSttsRsCd "Power Electronics Coolant Pump Controller Status Reason Code: Provides the reason code describing the unique failure of the Power Electronics Coolant Pump system or component.If a detailed reason code is not used by the supporting application, or thi...";
CM_ SG_ 2566651902 PwrEltrnsClntPmpCntrlTmprtr "Power Electronics Coolant Pump Control Temperature: A temperature measured and reported by the device.  It may be used for direct or remote (e.g. by another controller) control of the pump.  For example, this may be the temperature of the fluid flowi...";
CM_ SG_ 2566651902 PwrEltrnsClntPmpEnlStts "Power Electronics Coolant Pump Enable Status: Enable and direction status of the Power Electronics Coolant Pump system or component.00b = Accessory Motor Off01b = Accessory Motor On - Normal, Forward, or Default Direction10b = Accessory Motor On - Re...";
CM_ SG_ 2566651902 PwrEltrnsClntPmpMtrSpd "Power Electronics Coolant Pump Motor Speed: Motor Speed of the Power Electronics Coolant Pump. ";
CM_ SG_ 2566651902 PwrEltrnsClntPmpOprtngStts "Power Electronics Coolant Pump Operating Status: Indicates the operating status of the Power Electronics Coolant Pump system or component.This parameter is used to inform other devices that this system or component is no longer performing to its oper...";
CM_ SG_ 2566651902 PwrEltrnsClntPmpPwr "Power Electronics Coolant Pump Power: Calculated electrical power consumed by the Power Electronics Coolant Pump.";
CM_ SG_ 2566651902 PwrEltrnsClntPmpSrvIndtr "Power Electronics Coolant Pump Service Indicator: Indicates that service is required for the Power Electronics Coolant Pump system or component.An active indication may convey a need for component replacement or periodic service.  The Power Electroni...";
CM_ BO_ 2566652414 "Electrified Accessory Motor Status";
CM_ SG_ 2566652414 ElectrifiedAccessoryMotorPower "Electrified Accessory Motor Power: Calculated electrical power consumed by this Electrified Accessory Motor.";
CM_ SG_ 2566652414 ElectrifiedAccessoryMotorSpeed "Electrified Accessory Motor Speed: Speed of this Electrified Accessory Motor. ";
CM_ SG_ 2566652414 EltrfdAssrMtrCntrllrCmmndStts "Electrified Accessory Motor Controller Command Status: Indicates the source of the speed command to this Electrified Accessory Motor system or component.00b is communicated when the controller is self-controlled (e.g. based on a temperature sensor).0...";
CM_ SG_ 2566652414 EltrfdAssrMtrCntrllrSttsRsnCd "Electrified Accessory Motor Controller Status Reason Code: Provides the reason code describing the unique failure of this Electrified Accessory Motor system or component.If a detailed reason code is not used by the supporting application, or this rea...";
CM_ SG_ 2566652414 EltrfdAssrMtrEnlStts "Electrified Accessory Motor Enable Status: Enable and direction status of this Electrified Accessory Motor system or component.00b = Accessory Motor Off01b = Accessory Motor On - Normal, Forward, or Default Direction10b = Accessory Motor On - Reverse...";
CM_ SG_ 2566652414 EltrfdAssrMtrInstn "Electrified Accessory Motor Instance: Indicates the electrified accessory instance that is providing status.0000b = Instance 10001b = Instance 20010b = Instance 30011b = Instance 40100b = Instance 50101b = Instance 60110b = Instance 70111b = Instance...";
CM_ SG_ 2566652414 EltrfdAssrMtrMdmTmprtr "Electrified Accessory Motor Medium Temperature: A temperature measured and reported by the device.  It may be used for direct or remote (e.g. by another controller) control of the pump.  For example, this may be the temperature of the fluid flowing t...";
CM_ SG_ 2566652414 EltrfdAssrMtrOprtngStts "Electrified Accessory Motor Operating Status: Indicates the operating status of this Electrified Accessory Motor system or component.  This parameter is used to inform other devices that this system or component is no longer performing to its operati...";
CM_ SG_ 2566652414 EltrfdAssrMtrSrvIndtr "Electrified Accessory Motor Service Indicator: Indicates that service is required for this Electrified Accessory Motor system or component.  An active indication may convey a need for component replacement or periodic service.  The Electrified Access...";
CM_ BO_ 2566652670 "SCR System Information";
CM_ SG_ 2566652670 Atttt1DsExstFdDsSstFz "Aftertreatment 1 Diesel Exhaust Fluid Dosing System Frozen: All or part of the diesel exhaust fluid system (DEF tank, DEF supply lines, DEF pump, and DEF doser, etc.) in bank 1 is frozen.In situations where it is desired to report the DEF system froz...";
CM_ SG_ 2566652670 Atttt2DsExstFdDsSstFz "Aftertreatment 2 Diesel Exhaust Fluid Dosing System Frozen: All or part of the diesel exhaust fluid system (DEF tank, DEF supply lines, DEF pump, and DEF doser, etc.) in bank 2 is frozen.In situations where it is desired to report the DEF system froz...";
CM_ SG_ 2566652670 DieselExhaustFluidFrozenTime "Diesel Exhaust Fluid Frozen Time: Indicates the amount of time the diesel exhaust fluid is frozen while key switch is on. This will accumulate over the life of the product, and will never be reset.This parameter is not for engine applications that ar...";
CM_ SG_ 2566652670 Aftrtrtmnt1SstmHdrrn "Aftertreatment 1 System Hydrocarbon: The ratio of the mass of hydrocarbon present in the aftertreatment system compared to the maximum allowable mass of hydrocarbon for the aftertreatment system. 100% represents the maximum percentage of hydrocarbon ...";
CM_ SG_ 2566652670 Aftrtrtmnt2SstmHdrrn "Aftertreatment 2 System Hydrocarbon: The ratio of the mass of hydrocarbon present in the aftertreatment 2 system compared to the maximum allowable mass of hydrocarbon for the aftertreatment system. 100% represents the maximum percentage of hydrocarbo...";
CM_ BO_ 2566652926 "Vehicle Electrical Power 14";
CM_ SG_ 2566652926 SLIBatteryPack1Battery4Capacity "SLI Battery Pack 1 Battery 4 Capacity: Total reserve capacity of the fourth battery in the first battery pack used for starting the engine, for lighting, and for ignition (SLI).  This value could be the original capacity, rated capacity, or the capac...";
CM_ SG_ 2566652926 SLIBatteryPack1Battery4Health "SLI Battery Pack 1 Battery 4 Health: Capacity of the fourth battery in the first battery pack relative to its original specification for the battery pack used for starting the engine, for lighting, and for ignition (SLI). 0% means battery pack is not...";
CM_ SG_ 2566652926 SLIBttP1Btt4PdtdMCVt "SLI Battery Pack 1 Battery 4 Predicted Minimum Cranking Voltage: Prediction of the minimum battery voltage of the fourth battery in the first battery pack used for starting the engine, for lighting, and for ignition (SLI) during a crank event, under ...";
CM_ SG_ 2566652926 SLIBttrPk1Bttr4SttfChrg "SLI Battery Pack 1 Battery 4 State of Charge: Indicates the remaining charge of the fourth battery in the first battery pack used for starting the engine, for lighting, and for ignition (SLI). 0% means no charge remaining, 100% means full capacity at...";
CM_ SG_ 2566652926 SLIBttrPk1Snsr4IntlztnStts "SLI Battery Pack 1 Sensor 4 Initialization Status: The battery sensor may go through an initialization process when it is first connected to a battery.  This parameter reports the battery sensor's progress through the initialization process.0 = Initi...";
CM_ BO_ 2566653182 "Vehicle Electrical Power 13";
CM_ SG_ 2566653182 SLIBatteryPack1Battery4Voltage "SLI Battery Pack 1 Battery 4 Voltage: Voltage of the fourth battery in the first set of batteries (battery pack) used for starting the engine, for lighting, and for ignition (SLI). The relation to physical location is determined by the equipment manu...";
CM_ SG_ 2566653182 SLIBttrPk1Bttr4NtCrrnt "SLI Battery Pack 1 Battery 4 Net Current: Net flow of electrical current into/out of the fourth battery in the first set of batteries (battery pack) used for starting the engine, for lighting, and for ignition (SLI). ";
CM_ SG_ 2566653182 SLIBttrPk1Bttr4Tmprtr "SLI Battery Pack 1 Battery 4 Temperature: Temperature of the fourth battery in the first set of batteries (battery pack) used for starting the engine, for lighting, and for ignition (SLI). The relation to physical location is determined by the equipm...";
CM_ BO_ 2566653438 "Vehicle Electrical Power 12";
CM_ SG_ 2566653438 SLIBatteryPack1Battery3Capacity "SLI Battery Pack 1 Battery 3 Capacity: Total reserve capacity of the third battery in the first battery pack used for starting the engine, for lighting, and for ignition (SLI).  This value could be the original capacity, rated capacity, or the capaci...";
CM_ SG_ 2566653438 SLIBatteryPack1Battery3Health "SLI Battery Pack 1 Battery 3 Health: Capacity of the third battery in the first battery pack relative to its original specification for the battery pack used for starting the engine, for lighting, and for ignition (SLI). 0% means battery pack is not ...";
CM_ SG_ 2566653438 SLIBttP1Btt3PdtdMCVt "SLI Battery Pack 1 Battery 3 Predicted Minimum Cranking Voltage: Prediction of the minimum battery voltage of the third battery in the first battery pack used for starting the engine, for lighting, and for ignition (SLI) during a crank event, under p...";
CM_ SG_ 2566653438 SLIBttrPk1Bttr3SttfChrg "SLI Battery Pack 1 Battery 3 State of Charge: Indicates the remaining charge of the third battery in the first battery pack used for starting the engine, for lighting, and for ignition (SLI). 0% means no charge remaining, 100% means full capacity at ...";
CM_ SG_ 2566653438 SLIBttrPk1Snsr3IntlztnStts "SLI Battery Pack 1 Sensor 3 Initialization Status: The battery sensor may go through an initialization process when it is first connected to a battery.  This parameter reports the battery sensor's progress through the initialization process.0 = Initi...";
CM_ BO_ 2566653694 "Vehicle Electrical Power 11";
CM_ SG_ 2566653694 SLIBatteryPack1Battery3Voltage "SLI Battery Pack 1 Battery 3 Voltage: Voltage of the third battery in the first set of batteries (battery pack) used for starting the engine, for lighting, and for ignition (SLI). The relation to physical location is determined by the equipment manuf...";
CM_ SG_ 2566653694 SLIBttrPk1Bttr3NtCrrnt "SLI Battery Pack 1 Battery 3 Net Current: Net flow of electrical current into/out of the third battery in the first set of batteries (battery pack) used for starting the engine, for lighting, and for ignition (SLI). ";
CM_ SG_ 2566653694 SLIBttrPk1Bttr3Tmprtr "SLI Battery Pack 1 Battery 3 Temperature: Temperature of the third battery in the first set of batteries (battery pack) used for starting the engine, for lighting, and for ignition (SLI). The relation to physical location is determined by the equipme...";
CM_ BO_ 2566653950 "Vehicle Electrical Power 10";
CM_ SG_ 2566653950 SLIBatteryPack1Battery2Capacity "SLI Battery Pack 1 Battery 2 Capacity: Total reserve capacity of the second battery in the first battery pack used for starting the engine, for lighting, and for ignition (SLI).  This value could be the original capacity, rated capacity, or the capac...";
CM_ SG_ 2566653950 SLIBatteryPack1Battery2Health "SLI Battery Pack 1 Battery 2 Health: Capacity of the second battery in the first battery pack relative to its original specification for the battery pack used for starting the engine, for lighting, and for ignition (SLI). 0% means battery pack is not...";
CM_ SG_ 2566653950 SLIBttP1Btt2PdtdMCVt "SLI Battery Pack 1 Battery 2 Predicted Minimum Cranking Voltage: Prediction of the minimum battery voltage of the second battery in the first battery pack used for starting the engine, for lighting, and for ignition (SLI) during a crank event, under ...";
CM_ SG_ 2566653950 SLIBttrPk1Bttr2SttfChrg "SLI Battery Pack 1 Battery 2 State of Charge: Indicates the remaining charge of the second battery in the first battery pack used for starting the engine, for lighting, and for ignition (SLI). 0% means no charge remaining, 100% means full capacity at...";
CM_ SG_ 2566653950 SLIBttrPk1Snsr2IntlztnStts "SLI Battery Pack 1 Sensor 2 Initialization Status: The battery sensor may go through an initialization process when it is first connected to a battery.  This parameter reports the battery sensor's progress through the initialization process.0 = Initi...";
CM_ BO_ 2566654206 "Vehicle Electrical Power 9";
CM_ SG_ 2566654206 SLIBatteryPack1Battery2Voltage "SLI Battery Pack 1 Battery 2 Voltage: Voltage of the second battery in the first set of batteries (battery pack) used for starting the engine, for lighting, and for ignition (SLI). The relation to physical location is determined by the equipment manu...";
CM_ SG_ 2566654206 SLIBttrPk1Bttr2NtCrrnt "SLI Battery Pack 1 Battery 2 Net Current: Net flow of electrical current into/out of the second battery in the first set of batteries (battery pack) used for starting the engine, for lighting, and for ignition (SLI). ";
CM_ SG_ 2566654206 SLIBttrPk1Bttr2Tmprtr "SLI Battery Pack 1 Battery 2 Temperature: Temperature of the second battery in the first set of batteries (battery pack) used for starting the engine, for lighting, and for ignition (SLI). The relation to physical location is determined by the equipm...";
CM_ BO_ 2566654462 "Vehicle Electrical Power 8";
CM_ SG_ 2566654462 SLIBatteryPack1Battery1Capacity "SLI Battery Pack 1 Battery 1 Capacity: Total reserve capacity of the first battery in the first battery pack used for starting the engine, for lighting, and for ignition (SLI).  This value could be the original capacity, rated capacity, or the capaci...";
CM_ SG_ 2566654462 SLIBatteryPack1Battery1Health "SLI Battery Pack 1 Battery 1 Health: Capacity of the first battery in the first battery pack relative to its original specification for the battery pack used for starting the engine, for lighting, and for ignition (SLI). 0% means battery pack is not ...";
CM_ SG_ 2566654462 SLIBttP1Btt1PdtdMCVt "SLI Battery Pack 1 Battery 1 Predicted Minimum Cranking Voltage: Prediction of the minimum battery voltage of the first battery in the first battery pack used for starting the engine, for lighting, and for ignition (SLI) during a crank event, under p...";
CM_ SG_ 2566654462 SLIBttrPk1Bttr1SttfChrg "SLI Battery Pack 1 Battery 1 State of Charge: Indicates the remaining charge of the first battery in the first battery pack used for starting the engine, for lighting, and for ignition (SLI). 0% means no charge remaining, 100% means full capacity at ...";
CM_ SG_ 2566654462 SLIBttrPk1Snsr1IntlztnStts "SLI Battery Pack 1 Sensor 1 Initialization Status: The battery sensor may go through an initialization process when it is first connected to a battery.  This parameter reports the battery sensor's progress through the initialization process.0 = Initi...";
CM_ BO_ 2566654718 "Vehicle Electrical Power 7";
CM_ SG_ 2566654718 SLIBatteryPack1Battery1Voltage "SLI Battery Pack 1 Battery 1 Voltage: Voltage of the first battery in the first set of batteries (battery pack) used for starting the engine, for lighting, and for ignition (SLI). The relation to physical location is determined by the equipment manuf...";
CM_ SG_ 2566654718 SLIBttrPk1Bttr1NtCrrnt "SLI Battery Pack 1 Battery 1 Net Current: Net flow of electrical current into/out of the first battery in the first set of batteries (battery pack) used for starting the engine, for lighting, and for ignition (SLI). ";
CM_ SG_ 2566654718 SLIBttrPk1Bttr1Tmprtr "SLI Battery Pack 1 Battery 1 Temperature: Temperature of the first battery in the first set of batteries (battery pack) used for starting the engine, for lighting, and for ignition (SLI). The relation to physical location is determined by the equipme...";
CM_ BO_ 2566654974 "Electronic Engine Controller 20";
CM_ SG_ 2566654974 AtlMxmmAvllEngnPrntFl "Actual Maximum Available Engine - Percent Fuel: The percent of torque limited fuel relative to the engine standard torque fuel.  The torque limited fuel in the Actual Maximum Available Engine - Percent Fuel shall take into consideration all engine to...";
CM_ SG_ 2566654974 EsttdEPstLsssPtTqHRst "Estimated Engine Parasitic Losses - Percent Torque (High Resolution): Indicates the estimated amount of torque loss due to engine parasitics, such as cooling fan, air compressor, air conditioning, etc. It is expressed as a percent of Engine Reference...";
CM_ SG_ 2566654974 NmnlFrtnPrntTrqHghRsltn "Nominal Friction Percent Torque (High Resolution): Indicates the amount of torque required by the basic engine itself added by the loss torque of accessories. It contains the frictional and thermodynamic loss of the engine itself, pumping torque loss...";
CM_ SG_ 2566654974 AsltEngnLdPrntArMss "Absolute Engine Load - Percent Air Mass: Absolute Engine Load - Percent Air Mass is the normalized value of air mass per intake stroke displayed as a percent.Vehicles which utilize spark or compression ignition engines for propulsion shall use the fo...";
CM_ BO_ 2566655742 "Primary or Rear Hitch Roll and Pitch Sensitivity";
CM_ SG_ 2566655742 RearHitchPitchSensitivity "Rear Hitch Pitch Sensitivity: The current sensitivity of the rear hitch pitch control expressed as a percentage of the maximum gain.  0% indicates minimal gain in the control loop; 100%, the maximum gain. Values near zero may result in no reaction by...";
CM_ SG_ 2566655742 RearHitchRollSensitivity "Rear Hitch Roll Sensitivity: The current sensitivity of the rear hitch roll control expressed as a percentage of the maximum gain.  0% indicates minimal gain in the control loop; 100%, the maximum gain. Values near zero may result in no reaction by t...";
CM_ BO_ 2566656254 "Ambient Conditions 3";
CM_ SG_ 2566656254 BarometricAbsolutePressure2 "Barometric Absolute Pressure 2: Second absolute air pressure measurement of the atmosphere.See SPN 108 or SPN 5685 as the primary barometric pressure measurement.";
CM_ SG_ 2566656254 EngineIntake2AirTemperature "Engine Intake 2 Air Temperature: Temperature of air entering through a second vehicle air induction system.";
CM_ SG_ 2566656254 EngnPwrDrtRltvHmdtDffrn "Engine Power Derate Relative Humidity Difference: Indicates the current relative humidity compared to available relative humidity before engine power derate occurs.Positive values represents how much relative humidity is available before the derate. ...";
CM_ BO_ 2566656510 "Total Gaseous Fuel Information";
CM_ SG_ 2566656510 EngnTtlGssFlVlmUsd "Engine Total Gaseous Fuel Volume Used: Accumulated volume of engine gaseous fuel used during vehicle operation, in standard cubic meters.See SPN 1040 for alternate units.";
CM_ SG_ 2566656510 EngnTtlGssIdlFlVlmUsd "Engine Total Gaseous Idle Fuel Volume Used: Accumulated volume of engine gaseous fuel used during vehicle operation under idle conditions, in standard cubic meters.";
CM_ BO_ 2566658302 "Payload System Totals 2";
CM_ SG_ 2566658302 TotalPayloadTransactionCount "Total Payload Transaction Count: The accumulated number of completed payload delivery transactions over the life of the product.If transaction status monitoring is supported via Payload Delivery Transaction Status (SPN 7702) then total payload transa...";
CM_ BO_ 2566658558 "Payload System Totals 1";
CM_ SG_ 2566658558 TotalDeliveredPayloadWeight "Total Delivered Payload Weight: The accumulated delivered payload mass over the life of the product.This should be a monotonically increasing number that sums delivered payload weights (SPN 6849) If transactions are supported (Payload Delivery Transa...";
CM_ SG_ 2566658558 TotalHaulCycleCount "Total Haul Cycle Count: The total accumulated number of haul cycles over the life of the product.This should be a monotonically increasing number that sums Haul Cycle Count (SPN 6847). If transactions are supported via Payload Delivery Transaction St...";
CM_ BO_ 2566661118 "Fuel Consumption (Liquid) 2";
CM_ SG_ 2566661118 EngineTotalDieselFuelDemand "Engine Total Diesel Fuel Demand: Accumulated amount of liquid fuel that would have been used during engine operation, including actual diesel fuel used and the diesel fuel that was displaced by gaseous fuel.This is the cumulative value of SPN 7596....";
CM_ BO_ 2566661374 "Aftertreatment 2 Diesel Exhaust Fluid Tank 1 Information 2";
CM_ SG_ 2566661374 Aftrtrtmnt2DslExhstFldTnkHtr2 "Aftertreatment 2 Diesel Exhaust Fluid Tank Heater 2: Percentage of heating applied to the second diesel exhaust fluid tank heater on aftertreatment 2. A value of 0% means no heating applied, a value of 100% means full heating applied. The diesel exha...";
CM_ SG_ 2566661374 Aftrtrtmnt2DslExhstFldTnkVlm2 "Aftertreatment 2 Diesel Exhaust Fluid Tank Volume 2: Second measurement of the ratio of volume of diesel exhaust fluid to the total volume of the diesel exhaust fluid storage container for aftertreatment system 2 (exhaust bank 2).  0% is empty and 10...";
CM_ SG_ 2566661374 Atttt2DsExstFdTTpt2 "Aftertreatment 2 Diesel Exhaust Fluid Tank Temperature 2: The second temperature of aftertreatment 2 diesel exhaust fluid in the storage tank.";
CM_ BO_ 2566661630 "Aftertreatment 1 Diesel Exhaust Fluid Tank 1 Information 2";
CM_ SG_ 2566661630 Aftrtrtmnt1DslExhstFldTnkHtr2 "Aftertreatment 1 Diesel Exhaust Fluid Tank Heater 2: Percentage of heating applied to the second diesel exhaust fluid tank heater on aftertreatment 1. A value of 0% means no heating applied, a value of 100% means full heating applied. The diesel exha...";
CM_ SG_ 2566661630 Aftrtrtmnt1DslExhstFldTnkVlm2 "Aftertreatment 1 Diesel Exhaust Fluid Tank Volume 2: Second measurement of the ratio of volume of diesel exhaust fluid to the total volume of the diesel exhaust fluid storage container for aftertreatment system 1 (exhaust bank 1).  0% is empty and 10...";
CM_ SG_ 2566661630 Atttt1DsExstFdTTpt2 "Aftertreatment 1 Diesel Exhaust Fluid Tank Temperature 2: The second temperature of aftertreatment 1 diesel exhaust fluid in the storage tank.";
CM_ BO_ 2566661886 "Aftertreatment 2 Diesel Exhaust Fluid Information 2";
CM_ SG_ 2566661886 Atttt2DsExstFdCt2Tpt "Aftertreatment 2 Diesel Exhaust Fluid Controller 2 Temperature: Temperature of the diesel exhaust fluid at the aftertreatment 2 diesel exhaust fluid controller 2.";
CM_ SG_ 2566661886 Atttt2DsExstFdCtTpt "Aftertreatment 2 Diesel Exhaust Fluid Controller Temperature: Temperature of the diesel exhaust fluid at the aftertreatment 2 diesel exhaust fluid controller.";
CM_ BO_ 2566662142 "Aftertreatment 1 Diesel Exhaust Fluid Information 2";
CM_ SG_ 2566662142 Atttt1DsExstFdCt1Tpt "Aftertreatment 1 Diesel Exhaust Fluid Controller 1 Temperature: Temperature of the diesel exhaust fluid at the aftertreatment 1 diesel exhaust fluid controller.For controllers that have more exhaust emissions control functions than only diesel exhaus...";
CM_ SG_ 2566662142 Atttt1DsExstFdCt2Tpt "Aftertreatment 1 Diesel Exhaust Fluid Controller 2 Temperature: Temperature of the diesel exhaust fluid at the aftertreatment 1 diesel exhaust fluid controller 2.";
CM_ BO_ 2566662654 "Forward Lane Image 3";
CM_ SG_ 2566662654 LaneDepartureAngleLeft "Lane Departure Angle Left: Angle between left lane mark and vehicle driving direction. The angle is positive while vehicle is moving towards the lane marks, and negative if not. Measured values outside the limits are represented by signal value 251.P...";
CM_ SG_ 2566662654 LaneDepartureAngleRight "Lane Departure Angle Right: Angle between right lane mark and vehicle driving direction. The angle is positive while vehicle is moving towards the lane marks, and negative if not. Measured values outside the limits are represented by signal value 251...";
CM_ SG_ 2566662654 LaneMarkQualityontheLeftSide "Lane Mark Quality on the Left Side: The quality of the nearest lane mark on the left side of the vehicle.000b = no lane marks detected001b = low reliablity of detected lane marks010b = good reliablity of detected lane marks011b = perfect recognition ...";
CM_ SG_ 2566662654 LaneMarkQualityontheRightSide "Lane Mark Quality on the Right Side: The quality of the nearest lane mark on the right side of the vehicle.000b = no lane marks detected001b = low reliablity of detected lane marks010b = good reliablity of detected lane marks011b = perfect recognitio...";
CM_ SG_ 2566662654 LeftLaneMarkerType "Left Lane Marker Type: Indicates the type of lane marker detected by the Forward Lane Imager on the left side. 0000b = Processing or not identified0001b = Solid0010b = Road edge0011b = Dashed0100b = Double lane marker0101b = Raised lane marker (e.g. ...";
CM_ SG_ 2566662654 LftDstntLnMrkfrmVhlsMddl "Left Distance to Lane Mark from Vehicle's Middle: Distance between middle of the vehicle front and the inner/right edge of the nearest lane mark on the left side as measured from the Forward Lane Imager. The value represents the lane width at camera ...";
CM_ SG_ 2566662654 RghtDstntLnMrkfrmVhlsMddl "Right Distance to Lane Mark from Vehicle's Middle: Distance between middle of the vehicle front and the inner/left edge of the nearest lane mark on the right side as measured from the Forward Lane Imager. The value represents the lane width at camera...";
CM_ SG_ 2566662654 RightLaneMarkerType "Right Lane Marker Type: Indicates the type of lane marker detected by the Forward Lane Imager on the right side. 0000b = Processing or not identified0001b = Solid0010b = Road edge0011b = Dashed0100b = Double lane marker0101b = Raised lane marker (e.g...";
CM_ SG_ 2566662654 RoadCurvatureBasedonLaneMarks "Road Curvature Based on Lane Marks: The road curvature parameter is based on lane marks as measured by the FLI.  It is the mean value of the road curvature of the lane marks on the left and right side of the lane. In case one of the lane mark is not ...";
CM_ BO_ 2566662910 "Operator Inducement Information";
CM_ SG_ 2566662910 OprtrIndmntTmtFnlIndmntAtn "Operator Inducement Time to Final Inducement Action: Indicates the time until the inducement strategy enforces the final level of engine emissions operator inducement. The final level of inducement can include derating the engine, shutting down the e...";
CM_ SG_ 2566662910 OprtrIndmntTmtTrqDrtLvl1 "Operator Inducement Time to Torque Derate Level 1: This parameter provides the time until Operator Inducement Torque Derate Level 1 (SPN 7425) is activated.When operator inducement is not active, this parameter will be set to FB00h. For systems where...";
CM_ SG_ 2566662910 OprtrIndmntTmtTrqDrtLvl2 "Operator Inducement Time to Torque Derate Level 2: This parameter provides the time until Operator Inducement Torque Derate Level 2 (SPN 7427) is activated.When operator inducement is not active or if a second level of derate does not exist, then thi...";
CM_ SG_ 2566662910 OprtrIndmntTrqDrtLvl1 "Operator Inducement Torque Derate Level 1: This is the first torque derate that will be applied to the engine operation due to operator inducement.  The torque derate indicated in this parameter will be active when the value in Operator Inducement Ti...";
CM_ SG_ 2566662910 OprtrIndmntTrqDrtLvl2 "Operator Inducement Torque Derate Level 2: This is the second torque derate that will be applied to the engine operation due to operator inducement. The torque derate level indicated in this parameter will be applied when the value in Operator Induce...";
CM_ BO_ 2566663166 "Cruise Control / Vehicle Speed 4";
CM_ SG_ 2566663166 AppldVhlSpdLmtHghRsltn "Applied Vehicle Speed Limit (High Resolution): The vehicle speed limit in effect.See SPN 2595 for alternate resolution.Note:  If a maximum vehicle speed limit is not selected, then the first byte of this parameter will be equal to FBh.";
CM_ SG_ 2566663166 CrsCntrlAdjstdMxmmSpd "Cruise Control Adjusted Maximum Speed: Present maximum vehicle velocity at which cruise can be set. This parameter is expected to change during run-time due to functionality that could influence the behavior of the cruise control algorithm. This func...";
CM_ SG_ 2566663166 EngnExtrnlIdlRqstFdk "Engine External Idle Request  Feedback: Indicates that the engine is altering the idle speed due to a request from an external source. 00b = No Idle Alteration Active - standard idle speed01b = Idle Alteration Active10b = Error11b = Not available...";
CM_ SG_ 2566663166 SAddssCtDvSttCsCt "Source Address of Controlling Device for Setting Cruise Control: The source address of the SAE J1939 device that is currently sending the Cruise Control Set Command (SPN 9843).If there are multiple devices sending Cruise Control Set Command with a va...";
CM_ BO_ 2566663422 "Brake Caliper Lining Clearance";
CM_ SG_ 2566663422 TrlrBrkClprLnngClrnAxl1Lft "Trailer Brake Caliper Lining Clearance Axle 1 Left: Brake caliper lining clearance for left brake on trailer axle 1.00b = Caliper lining clearance is adequate01b = Caliper lining clearance is low10b = Error11b = Not available / not applicable...";
CM_ SG_ 2566663422 TrlrBrkClprLnngClrnAxl1Rght "Trailer Brake Caliper Lining Clearance Axle 1 Right: Brake caliper lining clearance for right brake on trailer axle 1.00b = Caliper lining clearance is adequate01b = Caliper lining clearance is low10b = Error11b = Not available / not applicable...";
CM_ SG_ 2566663422 TrlrBrkClprLnngClrnAxl2Lft "Trailer Brake Caliper Lining Clearance Axle 2 Left: Brake caliper lining clearance for left brake on trailer axle 2.00b = Caliper lining clearance is adequate01b = Caliper lining clearance is low10b = Error11b = Not available / not applicable...";
CM_ SG_ 2566663422 TrlrBrkClprLnngClrnAxl2Rght "Trailer Brake Caliper Lining Clearance Axle 2 Right: Brake caliper lining clearance for right brake on trailer axle 2.00b = Caliper lining clearance is adequate01b = Caliper lining clearance is low10b = Error11b = Not available / not applicable...";
CM_ SG_ 2566663422 TrlrBrkClprLnngClrnAxl3Lft "Trailer Brake Caliper Lining Clearance Axle 3 Left: Brake caliper lining clearance for left brake on trailer axle 3.00b = Caliper lining clearance is adequate01b = Caliper lining clearance is low10b = Error11b = Not available / not applicable...";
CM_ SG_ 2566663422 TrlrBrkClprLnngClrnAxl3Rght "Trailer Brake Caliper Lining Clearance Axle 3 Right: Brake caliper lining clearance for right brake on trailer axle 3.00b = Caliper lining clearance is adequate01b = Caliper lining clearance is low10b = Error11b = Not available / not applicable...";
CM_ SG_ 2566663422 TrlrBrkClprLnngClrnAxl4Lft "Trailer Brake Caliper Lining Clearance Axle 4 Left: Brake caliper lining clearance for left brake on trailer axle 4.00b = Caliper lining clearance is adequate01b = Caliper lining clearance is low10b = Error11b = Not available / not applicable...";
CM_ SG_ 2566663422 TrlrBrkClprLnngClrnAxl4Rght "Trailer Brake Caliper Lining Clearance Axle 4 Right: Brake caliper lining clearance for right brake on trailer axle 4.00b = Caliper lining clearance is adequate01b = Caliper lining clearance is low10b = Error11b = Not available / not applicable...";
CM_ SG_ 2566663422 TrlrBrkClprLnngClrnAxl5Lft "Trailer Brake Caliper Lining Clearance Axle 5 Left: Brake caliper lining clearance for left brake on trailer axle 5.00b = Caliper lining clearance is adequate01b = Caliper lining clearance is low10b = Error11b = Not available / not applicable...";
CM_ SG_ 2566663422 TrlrBrkClprLnngClrnAxl5Rght "Trailer Brake Caliper Lining Clearance Axle 5 Right: Brake caliper lining clearance for right brake on trailer axle 5.00b = Caliper lining clearance is adequate01b = Caliper lining clearance is low10b = Error11b = Not available / not applicable...";
CM_ SG_ 2566663422 TrtrBrkClprLnngClrnAxl1Lft "Tractor Brake Caliper Lining Clearance Axle 1 Left: Brake caliper lining clearance for left brake on tractor axle 1.00b = Caliper lining clearance is adequate01b = Caliper lining clearance is low10b = Error11b = Not available / not applicable...";
CM_ SG_ 2566663422 TrtrBrkClprLnngClrnAxl1Rght "Tractor Brake Caliper Lining Clearance Axle 1 Right: Brake caliper lining clearance for right brake on tractor axle 1.00b = Caliper lining clearance is adequate01b = Caliper lining clearance is low10b = Error11b = Not available / not applicable...";
CM_ SG_ 2566663422 TrtrBrkClprLnngClrnAxl2Lft "Tractor Brake Caliper Lining Clearance Axle 2 Left: Brake caliper lining clearance for left brake on tractor axle 2.00b = Caliper lining clearance is adequate01b = Caliper lining clearance is low10b = Error11b = Not available / not applicable...";
CM_ SG_ 2566663422 TrtrBrkClprLnngClrnAxl2Rght "Tractor Brake Caliper Lining Clearance Axle 2 Right: Brake caliper lining clearance for right brake on tractor axle 2.00b = Caliper lining clearance is adequate01b = Caliper lining clearance is low10b = Error11b = Not available / not applicable...";
CM_ SG_ 2566663422 TrtrBrkClprLnngClrnAxl3Lft "Tractor Brake Caliper Lining Clearance Axle 3 Left: Brake caliper lining clearance for left brake on tractor axle 3.00b = Caliper lining clearance is adequate01b = Caliper lining clearance is low10b = Error11b = Not available / not applicable...";
CM_ SG_ 2566663422 TrtrBrkClprLnngClrnAxl3Rght "Tractor Brake Caliper Lining Clearance Axle 3 Right: Brake caliper lining clearance for right brake on tractor axle 3.00b = Caliper lining clearance is adequate01b = Caliper lining clearance is low10b = Error11b = Not available / not applicable...";
CM_ SG_ 2566663422 TrtrBrkClprLnngClrnAxl4Lft "Tractor Brake Caliper Lining Clearance Axle 4 Left: Brake caliper lining clearance for left brake on tractor axle 4.00b = Caliper lining clearance is adequate01b = Caliper lining clearance is low10b = Error11b = Not available / not applicable...";
CM_ SG_ 2566663422 TrtrBrkClprLnngClrnAxl4Rght "Tractor Brake Caliper Lining Clearance Axle 4 Right: Brake caliper lining clearance for right brake on tractor axle 4.00b = Caliper lining clearance is adequate01b = Caliper lining clearance is low10b = Error11b = Not available / not applicable...";
CM_ SG_ 2566663422 TrtrBrkClprLnngClrnAxl5Lft "Tractor Brake Caliper Lining Clearance Axle 5 Left: Brake caliper lining clearance for left brake on tractor axle 5.00b = Caliper lining clearance is adequate01b = Caliper lining clearance is low10b = Error11b = Not available / not applicable...";
CM_ SG_ 2566663422 TrtrBrkClprLnngClrnAxl5Rght "Tractor Brake Caliper Lining Clearance Axle 5 Right: Brake caliper lining clearance for right brake on tractor axle 5.00b = Caliper lining clearance is adequate01b = Caliper lining clearance is low10b = Error11b = Not available / not applicable...";
CM_ BO_ 2566663678 "Alternate Fuel 5";
CM_ SG_ 2566663678 EngnFl2InjtrMtrngRl1Tmprtr2 "Engine Fuel 2 Injector Metering Rail 1 Temperature 2: The second temperature of fuel 2 measured by first rail temperature sensor in the primary, or first, metering rail as delivered from the supply pump to the injector metering intake.";
CM_ SG_ 2566663678 LNGTank1VaporPressure "LNG Tank 1 Vapor Pressure: Gage pressure of the vapor in the first tank in a multi-tank system (or unique tank if single-tank system).";
CM_ SG_ 2566663678 LNGTank2VaporPressure "LNG Tank 2 Vapor Pressure: Gage pressure of the vapor in the second tank in a multi-tank system.";
CM_ BO_ 2566663934 "Engine Turbocharger Control 3";
CM_ SG_ 2566663934 EngnClndrHdBpssAttr1MtrCrrntDsl "Engine Cylinder Head Bypass Actuator 1 Motor Current Disable: Command to disable power to motor in the actuator to prevent unnecessary load on the component.00b = Do Not Disable01b = Disable10b = Reserved11b = Don't Care/Take No Action";
CM_ SG_ 2566663934 EngnThrttlVlv1MtrCrrntDsl "Engine Throttle Valve 1 Motor Current Disable: Command to disable power to motor in the actuator to prevent unnecessary load on the component.00b = Do Not Disable01b = Disable10b = Reserved11b = Don't Care/Take No Action";
CM_ SG_ 2566663934 EngnTrhrgrWstgtAttr1MtrCrrntDsl "Engine Turbocharger Wastegate Actuator 1 Motor Current Disable: Command to disable power to motor in the actuator to prevent unnecessary load on the component.00b = Do Not Disable01b = Disable10b = Reserved11b = Don't Care/Take No Action";
CM_ SG_ 2566663934 EngnTrhrgrWstgtAttr2MtrCrrntDsl "Engine Turbocharger Wastegate Actuator 2 Motor Current Disable: Command to disable power to motor in wastegate actuator 2 to prevent unnecessary load on the component.00b = Do Not Disable01b = Disable10b = Reserved11b = Don't Care/Take No Action...";
CM_ SG_ 2566663934 ETCpssBpssAtt1MtCtDs "Engine Turbocharger Compressor Bypass Actuator 1 Motor Current Disable: Command to disable power to motor in bypass actuator 1 to prevent unnecessary load on the component.00b = Do Not Disable01b = Disable10b = Reserved11b = Don't Care/Take No Action...";
CM_ SG_ 2566663934 ETCpssBpssAtt2MtCtDs "Engine Turbocharger Compressor Bypass Actuator 2 Motor Current Disable: Command to disable power to motor in bypass actuator 2 to prevent unnecessary load on the component.00b = Do Not Disable01b = Disable10b = Reserved11b = Don't Care/Take No Action...";
CM_ SG_ 2566663934 ETCpssBwAtt1MtCtDs "Engine Turbocharger Compressor Blowoff Actuator 1 Motor Current Disable: Command to disable power to motor in the actuator to prevent unnecessary load on the component.00b = Do Not Disable01b = Disable10b = Reserved11b = Don't Care/Take No Action...";
CM_ BO_ 2566664702 "Aftertreatment System Information 1";
CM_ SG_ 2566664702 AftertreatmentEngineLoadRequest "Aftertreatment Engine Load Request: Indicates whether the aftertreatment desires engine load to be applied. This is meant to notify the operator that the aftertreatment is requesting engine load for thermal purposes.The operator is expected to add lo...";
CM_ SG_ 2566664702 AftrtrtmntAmntArTmprtr "Aftertreatment Ambient Air Temperature: Temperature of ambient air near the aftertreatment components such as DEF tank and DEF lines.";
CM_ SG_ 2566664702 AftrtrtmntDslExhstFldHtrCrtBrkr "Aftertreatment Diesel Exhaust Fluid Heater Circuit Breaker: The status of the circuit breaker that is used to heat the diesel exhaust fluid.00b = off01b = on10b = error11b = not available";
CM_ SG_ 2566664702 AftrtrtmntDslExhstFldTnkTmprtr "Aftertreatment Diesel Exhaust Fluid Tank Temperature: The derived diesel exhaust fluid tank temperature in applications with multiple temperature sensors in a single tank. The SP data will be derived from all temperature sensors in the tank.Note: Thi...";
CM_ SG_ 2566664702 AftrtrtmntDslExhstFldTnkVlm "Aftertreatment Diesel Exhaust Fluid Tank Volume: The derived diesel exhaust fluid tank volume in applications with multiple level sensors in a single tank. The SP data will be derived from all level sensors in the tank.Note: This SP can be derived fr...";
CM_ SG_ 2566664702 AftrtrtmntEngnSpdInrsrqst "Aftertreatment Engine Speed Increase request: Indicates whether the aftertreatment desires engine speed control in order to increase the engine speed. This is meant to notify the operator that the aftertreatment is requesting an increase in engine sp...";
CM_ SG_ 2566664702 AftrtrtmntThrmlMngmntStts "Aftertreatment Thermal Management Status: Indicates whether Aftertreatment Thermal Management process is active.Aftertreatment Thermal Management indicates that the exhaust temperatures have been controlled for the normal functioning of the aftertrea...";
CM_ SG_ 2566664702 AttttAtvRtItdDtLwExstPss "Aftertreatment Active Regeneration Inhibited Due to Low Exhaust Pressure: The state of aftertreatment active regeneration inhibition due to low exhaust pressure.Aftertreatment Regeneration is a process of increasing the temperature at the exhaust and...";
CM_ SG_ 2566664702 DslExhstFldQltMlfntnEvltnPrdAtv "Diesel Exhaust Fluid Quality Malfunction Evaluation Period Active: This parameter is used to notify the operator that a DEF Quality and DEF Level evaluation period, also known as a judgement period, is currently active.The judgement period is require...";
CM_ SG_ 2566664702 AftrtrtmntSCRDsngMdStts "Aftertreatment SCR Dosing Mode Status: Indicates that the aftertreatment system is dosing in standard or reduced mode.Standard indicates that the system will dose at maximum capacity where the reduced mode will dose at minimum capacity  (e.g., IMO 3 ...";
CM_ SG_ 2566664702 DPFAtvRgnrtnTmRmnng "DPF Active Regeneration Time Remaining: Indicates approximate remaining time of the parked active DPF Regeneration. This time is not for passive regeneration.If active regeneration is not in progress, this parameter shall respond with FBh.";
CM_ BO_ 2566665726 "Aftertreatment 2 Diesel Exhaust Fluid Pump 1 Information";
CM_ SG_ 2566665726 Aftrtrtmnt2DslExhstFldPmpHtr "Aftertreatment 2 Diesel Exhaust Fluid Pump Heater: Percentage of heating applied to the aftertreatment 2 diesel exhaust fluid pump heater.  A value of 0% means no heating applied, a value of 100% means full heating applied. The diesel exhaust fluid p...";
CM_ SG_ 2566665726 Atttt2DsExstFdPp2MtSpd "Aftertreatment 2 Diesel Exhaust Fluid Pump 2 Motor Speed: Rotational speed of the motor driving the second pump for the diesel exhaust fluid used in aftertreatment system 2 (exhaust bank 2).";
CM_ BO_ 2566667262 "Engine End Bearing Temperature 3";
CM_ SG_ 2566667262 EngineEndBearing17Temperature "Engine End Bearing 17 Temperature: Temperature of end bearing of the connecting rod for cylinder 17 on the engine";
CM_ SG_ 2566667262 EngineEndBearing18Temperature "Engine End Bearing 18 Temperature: Temperature of end bearing of the connecting rod for cylinder 18 on the engine";
CM_ SG_ 2566667262 EngineEndBearing19Temperature "Engine End Bearing 19 Temperature: Temperature of end bearing of the connecting rod for cylinder 19 on the engine";
CM_ SG_ 2566667262 EngineEndBearing20Temperature "Engine End Bearing 20 Temperature: Temperature of end bearing of the connecting rod for cylinder 20 on the engine";
CM_ BO_ 2566667518 "Engine End Bearing Temperature 2";
CM_ SG_ 2566667518 EngineEndBearing10Temperature "Engine End Bearing 10 Temperature: Temperature of end bearing of the connecting rod for cylinder 10 on the engine";
CM_ SG_ 2566667518 EngineEndBearing11Temperature "Engine End Bearing 11 Temperature: Temperature of end bearing of the connecting rod for cylinder 11 on the engine";
CM_ SG_ 2566667518 EngineEndBearing12Temperature "Engine End Bearing 12 Temperature: Temperature of end bearing of the connecting rod for cylinder 12 on the engine";
CM_ SG_ 2566667518 EngineEndBearing13Temperature "Engine End Bearing 13 Temperature: Temperature of end bearing of the connecting rod for cylinder 13 on the engine";
CM_ SG_ 2566667518 EngineEndBearing14Temperature "Engine End Bearing 14 Temperature: Temperature of end bearing of the connecting rod for cylinder 14 on the engine";
CM_ SG_ 2566667518 EngineEndBearing15Temperature "Engine End Bearing 15 Temperature: Temperature of end bearing of the connecting rod for cylinder 15 on the engine";
CM_ SG_ 2566667518 EngineEndBearing16Temperature "Engine End Bearing 16 Temperature: Temperature of end bearing of the connecting rod for cylinder 16 on the engine";
CM_ SG_ 2566667518 EngineEndBearing9Temperature "Engine End Bearing 9 Temperature: Temperature of end bearing of the connecting rod for cylinder 9 on the engine";
CM_ BO_ 2566667774 "Engine End Bearing Temperature 1";
CM_ SG_ 2566667774 EngineEndBearing1Temperature "Engine End Bearing 1 Temperature: Temperature of end bearing of the connecting rod for cylinder 1 on the engine";
CM_ SG_ 2566667774 EngineEndBearing2Temperature "Engine End Bearing 2 Temperature: Temperature of end bearing of the connecting rod for cylinder 2 on the engine";
CM_ SG_ 2566667774 EngineEndBearing3Temperature "Engine End Bearing 3 Temperature: Temperature of end bearing of the connecting rod for cylinder 3 on the engine";
CM_ SG_ 2566667774 EngineEndBearing4Temperature "Engine End Bearing 4 Temperature: Temperature of end bearing of the connecting rod for cylinder 4 on the engine";
CM_ SG_ 2566667774 EngineEndBearing5Temperature "Engine End Bearing 5 Temperature: Temperature of end bearing of the connecting rod for cylinder 5 on the engine";
CM_ SG_ 2566667774 EngineEndBearing6Temperature "Engine End Bearing 6 Temperature: Temperature of end bearing of the connecting rod for cylinder 6 on the engine";
CM_ SG_ 2566667774 EngineEndBearing7Temperature "Engine End Bearing 7 Temperature: Temperature of end bearing of the connecting rod for cylinder 7 on the engine";
CM_ SG_ 2566667774 EngineEndBearing8Temperature "Engine End Bearing 8 Temperature: Temperature of end bearing of the connecting rod for cylinder 8 on the engine";
CM_ BO_ 2566668030 "Heat Exchanger Debris Purge Information";
CM_ SG_ 2566668030 HeatExchangerDebrisPurgeStatus "Heat Exchanger Debris Purge Status: Indicates whether the system is currently purging debris from the heat exchanger.00b = Inactive01b = Active10b = SAE reserved11b = Not available";
CM_ SG_ 2566668030 HtExhngrDrsPrgApprhng "Heat Exchanger Debris Purge Approaching: Status signal which indicates that purging the debris from the heat exchanger is imminent.00b = Not approaching01b = Approaching10b = SAE reserved11b = Not available";
CM_ BO_ 2566668286 "Engine Turbocharger Control 2";
CM_ SG_ 2566668286 EngnStgdTrhrgrSlndStts "Engine Staged Turbocharger Solenoid Status: Current state of the staged turbocharger solenoid, normalized to percent, 0% represents not actuated and 100% represents fully actuated.";
CM_ BO_ 2566668542 "Engine Hydraulic Fuel 2 Pump Status";
CM_ SG_ 2566668542 EngnFl2PmpHdrlDrtnlVlv "Engine Fuel 2 Pump Hydraulic Directional Valve: Position of hydraulic directional valve to control application of hydraulic oil flow.  0% is no flow to the appliance; 100% is full flow to the appliance.";
CM_ SG_ 2566668542 EngnFl2PmpHdrlFlwCntrlVlv "Engine Fuel 2 Pump Hydraulic Flow Control Valve: Position of hydraulic pump flow control valve opening; 0% = fully closed, 100% = fully open.";
CM_ SG_ 2566668542 EngnFl2PmpHdrlPrssr "Engine Fuel 2 Pump Hydraulic Pressure: Hydraulic pressure in the lines of the hydraulically driven fuel 2 pump.";
CM_ SG_ 2566668542 EngnFl2PmpHdrlSwshPltAngl "Engine Fuel 2 Pump Hydraulic Swash Plate Angle: Position of hydraulic swash plate angle within hydraulic pump.  0% represents the lowest possible flow, 100% represents the maximum flow.";
CM_ BO_ 2566668798 "Alternate Fuel 4";
CM_ SG_ 2566668798 EngnFl2InjtrMtrngRl1Prssr "Engine Fuel 2 Injector Metering Rail 1 Pressure: The pressure of fuel 2 measured by first rail pressure sensor in the primary, or first, metering rail as delivered from the supply pump to the injector metering intake.";
CM_ SG_ 2566668798 EngnFl2InjtrMtrngRl1Prssr2 "Engine Fuel 2 Injector Metering Rail 1 Pressure 2: The second pressure of fuel 2 measured by first rail pressure sensor in the primary, or first, metering rail as delivered from the supply pump to the injector metering intake.";
CM_ SG_ 2566668798 EngnFl2InjtrMtrngRl1Tmprtr "Engine Fuel 2 Injector Metering Rail 1 Temperature: The temperature of fuel 2 measured by first rail temperature sensor in the primary, or first, metering rail as delivered from the supply pump to the injector metering intake.";
CM_ SG_ 2566668798 EngnFl2InjtrMtrngRl2Prssr "Engine Fuel 2 Injector Metering Rail 2 Pressure: The pressure of fuel 2 measured by first rail pressure sensor in the metering rail 2 as delivered from the supply pump to the injector metering intake.";
CM_ SG_ 2566668798 EngnFl2InjtrMtrngRl2Tmprtr "Engine Fuel 2 Injector Metering Rail 2 Temperature: The temperature of fuel 2 measured by first rail temperature sensor in the metering rail 2 as delivered from the supply pump to the injector metering intake.";
CM_ BO_ 2566669054 "Tire Condition Message 2";
CM_ SG_ 2566669054 RequiredTirePressure "Required Tire Pressure: The required tire pressure at which air is contained in cavity formed by tire and rim.This pressure of the tire is compensated to meet the specific physical environmental conditions (temperature) of the vehicle.";
CM_ SG_ 2566669054 TireLocation "Tire Location: Identifies which tire is associated with the parametric data in PGN 64578. Refer to SPN 929 for further details and examples. The low order 4 bits represent a position number, counting left to right when facing in the direction of norm...";
CM_ SG_ 2566669054 TirePressureExtendedRange "Tire Pressure (Extended Range): Pressure at which air is contained in cavity formed by tire and rim. See SPN 241 for alternate tire pressure with a lower range and coarser resolution.";
CM_ BO_ 2566669310 "Tire Configuration Status Information";
CM_ SG_ 2566669310 ColdInflationPressure "Cold Inflation Pressure: The cold inflation pressure of the tire. Cold inflation pressure is the default/reference inflation pressure suggested by the manufacturer for a specific tire.";
CM_ SG_ 2566669310 ExtrmUndrPrssrPrntgThrshld "Extreme Under Pressure Percentage Threshold: The percentage deviation from the set cold inflation pressure, for the extreme under tire pressure alert.";
CM_ SG_ 2566669310 OverPressurePercentageThreshold "Over Pressure Percentage Threshold: The percentage deviation from the set cold inflation pressure, for the over tire pressure alert.";
CM_ SG_ 2566669310 OverTemperature "Over Temperature: The temperature above which the over temperature alert will trigger.";
CM_ SG_ 2566669310 TireLocation "Tire Location: The location of monitored tire on the vehicle.The high order 4 bits indicate the vehicle axle position of the tire sensor, counting front to back on the vehicle, with the value 0 representing the front axle on the vehicle.The low order...";
CM_ SG_ 2566669310 UndrPrssrPrntgThrshld "Under Pressure Percentage Threshold: The percentage deviation from the set cold inflation pressure, for the under tire pressure alert.";
CM_ BO_ 2566669822 "Tire Wireless Signal Strength Indicator";
CM_ SG_ 2566669822 AntennaNumber "Antenna Number: Number of the antenna used to communicate signal strength of a group of sensors.  If a single antenna is used this will default to 01h. When multiple antennas are used, the first antenna will have a value of 1, 2nd antenna will be 2, ...";
CM_ SG_ 2566669822 TireLocation "Tire Location: The location of monitored tire on the vehicle.The high order 4 bits indicate the vehicle axle position of the tire sensor, counting front to back on the vehicle, with the value 0 representing the front axle on the vehicle.The low order...";
CM_ SG_ 2566669822 TireSensorNumber "Tire Sensor Number: The number of the monitored tire sensor that corresponds with the tire wireless signal strength indicator. The location of the numbered tire is reported in the tire sensor location SP (SPN 6965). The value FFh indicates this SP is...";
CM_ SG_ 2566669822 TotalNumberofAntennasUsed "Total Number of Antennas Used: Total count of antennas used in the specified vehicle system.";
CM_ SG_ 2566669822 TrWrlssSgnlStrngthIndtr "Tire Wireless Signal Strength Indicator: The wireless signal strength between the tire pressure sensor and the specified antenna, for the tire specified in the tire sensor number or tire sensor Location.";
CM_ SG_ 2566669822 TtlNmrfTrSnsrsMntrd "Total Number of Tire Sensors Monitored: Total number of tire sensors monitored for the specified antenna in this instance of the parameter group.";
CM_ BO_ 2566670078 "Tire Sensor Identification Status";
CM_ SG_ 2566670078 NumberofTireSensors "Number of Tire Sensors: Total count of monitored tire sensor identification numbers represented in this instance of the parameter group.";
CM_ SG_ 2566670078 TireLocation "Tire Location: The location of monitored tire that corresponds with the Tire Sensor Identification Number (SPN 6966). In order to specify the monitored tire by tire number, use the Tire Number SPN 6964.The high order 4 bits indicate the vehicle axle ...";
CM_ SG_ 2566670078 TireNumber "Tire Number: The number of the monitored tire that corresponds with the Tire Sensor Identification Number (SPN 6966).  In order to specify the monitored tire by location, use the Tire Location SPN 6965.The value FFh indicates this SP is not used.";
CM_ SG_ 2566670078 TireSensorIdentificationNumber "Tire Sensor Identification Number: The identification number of the tire specified in the tire number (SPN 6964) or tire location (SPN 6965).";
CM_ BO_ 2566670334 "Monitored Tire Information";
CM_ SG_ 2566670334 Axle10MonitoredTireCount "Axle 10 Monitored Tire Count: The number of tires on Axle 10 which are monitored by the tire monitor controller. The axle number increments from front to rear of the vehicle when facing the vehicle in the forward vehicle travel orientation. If the ax...";
CM_ SG_ 2566670334 Axle11MonitoredTireCount "Axle 11 Monitored Tire Count: The number of tires on Axle 11 which are monitored by the tire monitor controller. The axle number increments from front to rear of the vehicle when facing the vehicle in the forward vehicle travel orientation. If the ax...";
CM_ SG_ 2566670334 Axle12MonitoredTireCount "Axle 12 Monitored Tire Count: The number of tires on Axle 12 which are monitored by the tire monitor controller. The axle number increments from front to rear of the vehicle when facing the vehicle in the forward vehicle travel orientation. If the ax...";
CM_ SG_ 2566670334 Axle1MonitoredTireCount "Axle 1 Monitored Tire Count: The number of tires on Axle 1 which are monitored by the tire monitor controller. The axle number increments from front to rear of the vehicle when facing the vehicle in the forward vehicle travel orientation. If the axle...";
CM_ SG_ 2566670334 Axle2MonitoredTireCount "Axle 2 Monitored Tire Count: The number of tires on Axle 2 which are monitored by the tire monitor controller. The axle number increments from front to rear of the vehicle when facing the vehicle in the forward vehicle travel orientation. If the axle...";
CM_ SG_ 2566670334 Axle3MonitoredTireCount "Axle 3 Monitored Tire Count: The number of tires on Axle 3 which are monitored by the tire monitor controller. The axle number increments from front to rear of the vehicle when facing the vehicle in the forward vehicle travel orientation. If the axle...";
CM_ SG_ 2566670334 Axle4MonitoredTireCount "Axle 4 Monitored Tire Count: The number of tires on Axle 4 which are monitored by the tire monitor controller. The axle number increments from front to rear of the vehicle when facing the vehicle in the forward vehicle travel orientation. If the axle...";
CM_ SG_ 2566670334 Axle5MonitoredTireCount "Axle 5 Monitored Tire Count: The number of tires on Axle 5 which are monitored by the tire monitor controller. The axle number increments from front to rear of the vehicle when facing the vehicle in the forward vehicle travel orientation. If the axle...";
CM_ SG_ 2566670334 Axle6MonitoredTireCount "Axle 6 Monitored Tire Count: The number of tires on Axle 6 which are monitored by the tire monitor controller. The axle number increments from front to rear of the vehicle when facing the vehicle in the forward vehicle travel orientation. If the axle...";
CM_ SG_ 2566670334 Axle7MonitoredTireCount "Axle 7 Monitored Tire Count: The number of tires on Axle 7 which are monitored by the tire monitor controller. The axle number increments from front to rear of the vehicle when facing the vehicle in the forward vehicle travel orientation. If the axle...";
CM_ SG_ 2566670334 Axle8MonitoredTireCount "Axle 8 Monitored Tire Count: The number of tires on Axle 8 which are monitored by the tire monitor controller. The axle number increments from front to rear of the vehicle when facing the vehicle in the forward vehicle travel orientation. If the axle...";
CM_ SG_ 2566670334 Axle9MonitoredTireCount "Axle 9 Monitored Tire Count: The number of tires on Axle 9 which are monitored by the tire monitor controller. The axle number increments from front to rear of the vehicle when facing the vehicle in the forward vehicle travel orientation. If the axle...";
CM_ SG_ 2566670334 NumberofAxlesontheVehicle "Number of Axles on the Vehicle: The number of axles monitored for tire parameters. A maximum of 12 axles is defined.";
CM_ SG_ 2566670334 NumberofTiresontheVehicle "Number of Tires on the Vehicle: The total number of tires monitored for tire parameters. A maximum of 250 tires is defined.";
CM_ BO_ 2566670590 "Aftertreatment 2 Historical Information 2";
CM_ SG_ 2566670590 Atttt2SCRSstAvDstBtwSstCEvts "Aftertreatment 2 SCR System Average Distance Between System Cleaning Events: Indicates the average distance since last reset between cleaning events for the SCR system in bank 2.If the manufacturer allows this parameter to be reset, this distance is ...";
CM_ SG_ 2566670590 Atttt2SCRSstAvTBtwSstCEvts "Aftertreatment 2 SCR System Average Time Between System Cleaning Events: Indicates the average time since last reset between cleaning events for the SCR system in bank 2.If the manufacturer allows this parameter to be reset, this time is the average ...";
CM_ SG_ 2566670590 Atttt2SCRSstTtNSstCEvts "Aftertreatment 2 SCR System Total Number of System Cleaning Events: Total number of cleaning events that have occurred on the SCR system in bank 2 over the lifetime of the device.";
CM_ SG_ 2566670590 Atttt2SCRSstTtNSstCItRqsts "Aftertreatment 2 SCR System Total Number of System Cleaning Inhibit Requests: Total number of cleaning inhibit requests on the SCR system in bank 2 by the operator over the lifetime of the device.";
CM_ SG_ 2566670590 Atttt2SCRSstTtNSstCMRqsts "Aftertreatment 2 SCR System Total Number of System Cleaning Manual Requests: Total number of manual cleaning requests on the SCR system in bank 2 by the operator over the lifetime of the device.";
CM_ SG_ 2566670590 Atttt2SCRSstTtSstCT "Aftertreatment 2 SCR System Total System Cleaning Time: Total amount of time that a cleaning event has been active in the SCR system in bank 2 over the lifetime of the device.";
CM_ BO_ 2566670846 "Aftertreatment 1 Historical Information 2";
CM_ SG_ 2566670846 Aftrtrtmnt1SCRSstmTtlClnngTm "Aftertreatment 1 SCR System Total Cleaning Time: Total amount of time that a cleaning event has been active in the SCR system in bank 1 over the lifetime of the device.";
CM_ SG_ 2566670846 Atttt1SCRSstAvDstBtwSstCEvts "Aftertreatment 1 SCR System Average Distance Between System Cleaning Events: Indicates the average distance since last reset between cleaning events for the SCR system in bank 1.If the manufacturer allows this parameter to be reset, this distance is ...";
CM_ SG_ 2566670846 Atttt1SCRSstAvTBtwSstCEvts "Aftertreatment 1 SCR System Average Time Between System Cleaning Events: Indicates the average time since last reset between cleaning events for the SCR system in bank 1. If the manufacturer allows this parameter to be reset, this time is the average...";
CM_ SG_ 2566670846 Atttt1SCRSstTtNSstCEvts "Aftertreatment 1 SCR System Total Number of System Cleaning Events: Total number of cleaning events that have occurred on the SCR system in bank 1 over the lifetime of the device.";
CM_ SG_ 2566670846 Atttt1SCRSstTtNSstCItRqsts "Aftertreatment 1 SCR System Total Number of System Cleaning Inhibit Requests: Total number of cleaning inhibit requests on the SCR system in bank 1 by the operator over the lifetime of the device.";
CM_ SG_ 2566670846 Atttt1SCRSstTtNSstCMRqsts "Aftertreatment 1 SCR System Total Number of System Cleaning Manual Requests: Total number of manual cleaning requests on the SCR system in bank 1 by the operator over the lifetime of the device.";
CM_ SG_ 2566670846 TtlAftrtrtmntOprtngHrs "Total Aftertreatment Operating Hours: Accumulated time of operation of aftertreatment system.  Operating hours are accumulated only when there is air flowing thru the aftertreatment system.";
CM_ BO_ 2566671102 "SCR System Cleaning";
CM_ SG_ 2566671102 Atttt1SCRSstCdtsNtMtAtvC "Aftertreatment 1 SCR System Conditions Not Met for Active Cleaning: Indicates that SCR System 1 is not able to begin or continue an active cleaning event at the current engine operating conditions.00b = SCR System Cleaning not Inhibited01b = SCR Syst...";
CM_ SG_ 2566671102 SCRSstCItdDtAtPdOId "SCR System Cleaning Inhibited Due to Accelerator Pedal Off Idle: Indicates the state of SCR system cleaning inhibition due to the accelerator pedal being off idle.00b = not inhibited01b = inhibited10b = reserved for SAE assignment11b = not availableT...";
CM_ SG_ 2566671102 SCRSstCItdDtLwExstTpt "SCR System Cleaning Inhibited Due to Low Exhaust Temperature: Indicates the state of SCR system cleaning inhibition due to the exhaust temperature being too low.  This implies that the SCR system is too cold for cleaning.00b = not inhibited01b = inhi...";
CM_ SG_ 2566671102 SCRSstCItdDtPtSstLt "SCR System Cleaning Inhibited Due to Permanent System Lockout: Indicates the state of SCR system cleaning inhibition due to a permanent system lockout.00b = not inhibited01b = inhibited10b = reserved for SAE assignment11b = not availableThis SP indic...";
CM_ SG_ 2566671102 SCRSstCItdDtVSpdAvAwdSpd "SCR System Cleaning Inhibited Due to Vehicle Speed Above Allowed Speed: Indicates the state of SCR system cleaning inhibition due to the vehicle speed being above an allowed limit.00b = not inhibited01b = inhibited10b = reserved for SAE assignment11b...";
CM_ SG_ 2566671102 SCRSstCItdDtVSpdBwAwdSpd "SCR System Cleaning Inhibited Due to Vehicle Speed Below Allowed Speed: Indicates the state of SCR system cleaning inhibition due to the vehicle speed being less than the allowed vehicle speed.00b = not inhibited01b = inhibited10b = reserved for SAE ...";
CM_ SG_ 2566671102 SCRSstmClnngAtmtInttnCnfgrtn "SCR System Cleaning Automatic Initiation Configuration: Indicates the configuration of SCR system cleaning automatic initiation.00b = not enabled01b = enabled10b = reserved for SAE assignment11b = not available";
CM_ SG_ 2566671102 SCRSstmClnngInhtdDtClthDsnggd "SCR System Cleaning Inhibited Due to Clutch Disengaged: Indicates the state of SCR system cleaning event inhibition due to the clutch being disengaged.00b = not inhibited01b = inhibited10b = reserved for SAE assignment11b = not availableThis SP indic...";
CM_ SG_ 2566671102 SCRSstmClnngInhtdDtEngnNtWrmdUp "SCR System Cleaning Inhibited Due to Engine Not Warmed Up: Indicates the state of SCR system cleaning inhibition due to the engine not being warmed up.00b = not inhibited01b = inhibited10b = reserved for SAE assignment11b = not availableThis SP indic...";
CM_ SG_ 2566671102 SCRSstmClnngInhtdDtInhtSwth "SCR System Cleaning Inhibited Due to Inhibit Switch: Indicates the state of SCR system cleaning inhibition due to the SCR system cleaning Inhibit Switch.00b = not inhibited01b = inhibited10b = reserved for SAE assignment11b = not availableThis SP ind...";
CM_ SG_ 2566671102 SCRSstmClnngInhtdDtOtfNtrl "SCR System Cleaning Inhibited Due to Out of Neutral: Indicates the state of SCR system cleaning inhibition due to the accelerator pedal being out of neutral.00b = not inhibited01b = inhibited10b = reserved for SAE assignment11b = not availableThis SP...";
CM_ SG_ 2566671102 SCRSstmClnngInhtdDtPrkngBrkNtSt "SCR System Cleaning Inhibited Due to Parking Brake Not Set: Indicates the state of SCR system cleaning inhibition due to the parking brake being not set.00b = not inhibited01b = inhibited10b = reserved for SAE assignment11b = not availableThis SP ind...";
CM_ SG_ 2566671102 SCRSstmClnngInhtdDtPTOAtv "SCR System Cleaning Inhibited Due to PTO Active: Indicates the state of SCR system cleaning inhibition due to the PTO being active.00b = not inhibited01b = inhibited10b = reserved for SAE assignment11b = not availableThis SP indicates the reason for ...";
CM_ SG_ 2566671102 SCRSstmClnngInhtdDtSrvBrkAtv "SCR System Cleaning Inhibited Due to Service Brake Active: Indicates the state of SCR system cleaning inhibition due to the service brake being active.00b = not inhibited01b = inhibited10b = reserved for SAE assignment11b = not availableThis SP indic...";
CM_ SG_ 2566671102 SCRSstmClnngInhtdDtSstmFltAtv "SCR System Cleaning Inhibited Due to System Fault Active: Indicates the state of SCR system cleaning inhibition due to a system fault being active.00b = not inhibited01b = inhibited10b = reserved for SAE assignment11b = not availableThis SP indicates...";
CM_ SG_ 2566671102 SCRSstmClnngInhtdDtSstmTmt "SCR System Cleaning Inhibited Due to System Timeout: Indicates the state of SCR system cleaning inhibition due to a system timeout.00b = not inhibited01b = inhibited10b = reserved for SAE assignment11b = not availableThis SP indicates the reason for ...";
CM_ SG_ 2566671102 SCRSstmClnngInhtdDtTmprrSstmLkt "SCR System Cleaning Inhibited Due to Temporary System Lockout: Indicates the state of SCR system cleaning inhibition due to a temporary system lockout.00b = not inhibited01b = inhibited10b = reserved for SAE assignment11b = not availableThis SP indic...";
CM_ SG_ 2566671102 SCRSstmClnngInhtdStts "SCR System Cleaning Inhibited Status: Indicates the state of SCR system cleaning inhibition.00b = not inhibited01b = inhibited10b = reserved for SAE assignment11b = not availableThis SP indicates the reason for the SCR system cleaning event not being...";
CM_ SG_ 2566671102 SCRSystemCleaningForcedStatus "SCR System Cleaning Forced Status: Indicates the forced execution status of SCR system cleaning.000b = Not Active001b = Active – Forced by Switch (See SPN 3696)010b = Active – Forced by Service Tool 011b = Reserved for SAE Assignment100b = Reserved f...";
CM_ SG_ 2566671102 SCRSystemCleaningLampCommand "SCR System Cleaning Lamp Command: Command to control the SCR system cleaning lamp.000b = Off001b = On – solid010b = reserved for SAE assignment 011b = reserved for SAE assignment100b = On – fast blink (1 HZ)101b = reserved for SAE assignment110b = re...";
CM_ SG_ 2566671102 SCRSystemCleaningStatus "SCR System Cleaning Status: Indicates the state of SCR system cleaning.  This is an aggregate of bank 1 and bank 2.  It is a system status and not individual bank status.00b = not active01b = active10b = SCR system cleaning is needed - automatically ...";
CM_ BO_ 2566671358 "Electronic Engine Controller 17";
CM_ SG_ 2566671358 CylinderFuelRate "Cylinder Fuel Rate: Cylinder fuel rate shall indicate the amount of fuel injected into the cylinder for combustion during the most recent intake stroke of the engine.NOTE: Cylinder fuel rate shall indicate zero mg/stroke when the engine is not runnin...";
CM_ SG_ 2566671358 EngineExhaustFlowRate "Engine Exhaust Flow Rate: Engine Exhaust Flow Rate shall indicate the measured/calculated exhaust gas mass flow upstream of the aftertreatment system.Engine Exhaust Flow Rate shall be calculated as the average exhaust flow rate over the last 1000 mil...";
CM_ SG_ 2566671358 PEMSEngineFuelMassFlowRate "PEMS Engine Fuel Mass Flow Rate: PEMS Engine Fuel Mass Flow Rate shall indicate the amount of fuel consumed by the engine per unit of time (does not include fuel injected directly into the aftertreatment system, but does include fuel injected into th...";
CM_ SG_ 2566671358 VehicleFuelRate "Vehicle Fuel Rate: Vehicle Fuel Rate shall indicate the amount of fuel consumed by the engine and fuel injected directly into the aftertreatment system per unit of time, in grams per second.Vehicle Fuel Rate shall be calculated as the sum of the fuel...";
CM_ BO_ 2566671614 "SCR Operator Inducement Information 3";
CM_ SG_ 2566671614 NSCROptIdtOvdEvtsR "Number of SCR Operator Inducement Override Events Remaining: During an operator inducement event, the operator may be able to override the inducement multiple times. This parameter indicates the remaining number of times that the currently active ind...";
CM_ SG_ 2566671614 SCROprtrIndmntOvrrdEnl "SCR Operator Inducement Override Enable: Indicates if an operator inducement derate is allowed to be overridden.Note: Inducement override is only allowed under certain conditions approved by EPA/ARB.00b = Override not allowed01b = Override allowed10b...";
CM_ SG_ 2566671614 SCROprtrIndmntOvrrdTmRmnng "SCR Operator Inducement Override Time Remaining: This parameter is used to indicate the time remaining during an operator inducement override event.  See also SPN 7344 for an alternate SLOT.When an operator inducement is not active, this parameter in...";
CM_ SG_ 2566671614 TtlNmrfSCROprtrIndmntOvrrdEvnts "Total Number of SCR Operator Inducement Override Events: Indicates total number of operator inducement override events activated throughout the lifetime of engine operation.This number will remain at the maximum value once it is reached.See EU Commis...";
CM_ BO_ 2566671870 "Aftertreatment 2 SCR Dosing System Information 3";
CM_ SG_ 2566671870 Aftrtrtmnt2DslExhstFldDsr2Prssr "Aftertreatment 2 Diesel Exhaust Fluid Doser 2 Pressure: The SCR doser 2 diesel exhaust fluid gage pressure (measured closest to dosing valve) for aftertreatment system 2 (exhaust bank ). This is the gage equivalent to SPN 7464 .";
CM_ SG_ 2566671870 Aftrtrtmnt2DslExhstFldDsrPrssr "Aftertreatment 2 Diesel Exhaust Fluid Doser Pressure: The SCR dosing diesel exhaust fluid gage pressure (measured closest to dosing valve) for aftertreatment system 2 (exhaust bank 2). This is the gage equivalent to SPN 4387.";
CM_ SG_ 2566671870 Atttt2DsExstFdDs2AstPss "Aftertreatment 2 Diesel Exhaust Fluid Doser 2 Absolute Pressure: The SCR doser 2 diesel exhaust fluid absolute pressure (measured closest to dosing valve) for aftertreatment system 2 (exhaust bank 2).";
CM_ SG_ 2566671870 Atttt2DsExstFdDs2Tpt "Aftertreatment 2 Diesel Exhaust Fluid Doser 2 Temperature: The temperature (measured closest to doser valve) of the second DEF doser unit for aftertreatment system 2 (exhaust bank 2).";
CM_ BO_ 2566672126 "Aftertreatment 1 SCR Dosing System Information 3";
CM_ SG_ 2566672126 Aftrtrtmnt1DslExhstFldDsr2Prssr "Aftertreatment 1 Diesel Exhaust Fluid Doser 2 Pressure: The SCR doser 2 diesel exhaust fluid gage pressure (measured closest to dosing valve) for aftertreatment system 1 (exhaust bank 1). This is the gage equivalent to SPN 7459 .";
CM_ SG_ 2566672126 Aftrtrtmnt1DslExhstFldDsrPrssr "Aftertreatment 1 Diesel Exhaust Fluid Doser Pressure: The SCR dosing diesel exhaust fluid gage pressure (measured closest to dosing valve) for aftertreatment system 1 (exhaust bank 1). This is the gage equivalent to SPN 4334.";
CM_ SG_ 2566672126 Atttt1DsExstFdDs2AstPss "Aftertreatment 1 Diesel Exhaust Fluid Doser 2 Absolute Pressure: The SCR doser 2 diesel exhaust fluid absolute pressure (measured closest to dosing valve) for aftertreatment system 1 (exhaust bank 1).";
CM_ SG_ 2566672126 Atttt1DsExstFdDs2Tpt "Aftertreatment 1 Diesel Exhaust Fluid Doser 2 Temperature: The temperature (measured closest to dosing valve) of the second DEF dosing unit for aftertreatment system 1 (exhaust bank 1).";
CM_ BO_ 2566672382 "Payload Weight Sensor Information";
CM_ SG_ 2566672382 PayloadWeightSensor1Status "Payload Weight Sensor 1 Status: Status of the payload system sensor 1 measurement.00b = Sensor fully functional01b = Sensor degraded10b = Error (Sensor failed)11b = Not available";
CM_ SG_ 2566672382 PayloadWeightSensor2Status "Payload Weight Sensor 2 Status: Status of the payload system sensor 2 measurement.00b = Sensor fully functional01b = Sensor degraded10b = Error (Sensor failed)11b = Not available";
CM_ SG_ 2566672382 PayloadWeightSensor3Status "Payload Weight Sensor 3 Status: Status of the payload system sensor 3 measurement.00b = Sensor fully functional01b = Sensor degraded10b = Error (Sensor failed)11b = Not available";
CM_ SG_ 2566672382 PayloadWeightSensor4Status "Payload Weight Sensor 4 Status: Status of the payload system sensor 4 measurement.00b = Sensor fully functional01b = Sensor degraded10b = Error (Sensor failed)11b = Not available";
CM_ SG_ 2566672382 PayloadWeightSensor5Status "Payload Weight Sensor 5 Status: Status of the payload system sensor 5 measurement.00b = Sensor fully functional01b = Sensor degraded10b = Error (Sensor failed)11b = Not available";
CM_ SG_ 2566672382 PayloadWeightSensor6Status "Payload Weight Sensor 6 Status: Status of the payload system sensor 6 measurement.00b = Sensor fully functional01b = Sensor degraded10b = Error (Sensor failed)11b = Not available";
CM_ SG_ 2566672382 PayloadWeightSensor7Status "Payload Weight Sensor 7 Status: Status of the payload system sensor 7 measurement.00b = Sensor fully functional01b = Sensor degraded10b = Error (Sensor failed)11b = Not available";
CM_ SG_ 2566672382 PayloadWeightSensor8Status "Payload Weight Sensor 8 Status: Status of the payload system sensor 8 measurement.00b = Sensor fully functional01b = Sensor degraded10b = Error (Sensor failed)11b = Not available";
CM_ BO_ 2566672638 "Payload System Status";
CM_ SG_ 2566672638 DeliveredPayloadConfidence "Delivered Payload Confidence: The level of confidence of the delivered payload weight measurement. Higher confidence values indicate greater probability the delivered payload weight is the actual weight and providing feedback on the potential for imp...";
CM_ SG_ 2566672638 DeliveredPayloadWeight "Delivered Payload Weight: The delivered payload mass during the last haul cycle. This is the amount of material moved and delivered by a machine is a key work cycle parameter.Delivered payload weight is defined as the last loaded weight less the carr...";
CM_ SG_ 2566672638 HaulCycleCount "Haul Cycle Count: A counter incremented by 1 with each instance of a new haul cycle, defined as a dump to dump cycle. The counter shall increment from 0 to 64255, rolling over to 0 on the next increment after 64255.";
CM_ SG_ 2566672638 HaulModeStatus "Haul Mode Status: The current operating state of the haul cycle.0000b = Not in Haul Mode0001b = Loading -- Payload is being added to the machine0010b = Approaching Loaded -- Machine is near its maximum capacity0011b = Loaded -- Loading operation has ...";
CM_ SG_ 2566672638 PldDlvrTrnstnStts "Payload Delivery Transaction Status: The current state of the payload delivery transaction.When a transaction is in progress, a receiving node may monitor Haul Cycle Count (SPN 6847) and Delivered Payload Weight (SPN 6849) in order to track the progr...";
CM_ BO_ 2566673406 "Engine Gaseous Leakage Information";
CM_ SG_ 2566673406 GasLeakageDetection1Pressure "Gas Leakage Detection 1 Pressure: Pressure measured in gas leakage detection point 1. Measured media is of the gas, meaning it could be air, inert gas, fuel air mixture or charge air mixture, depending on the failure mode detected. The measurement po...";
CM_ SG_ 2566673406 GasLeakageDetection2Pressure "Gas Leakage Detection 2 Pressure: Pressure measured in gas leakage detection point 2. Measured media is of the gas, meaning it could be air, inert gas, fuel air mixture or charge air mixture, depending on the failure mode detected. The second measure...";
CM_ SG_ 2566673406 GasLeakageDetection3Pressure "Gas Leakage Detection 3 Pressure: Pressure measured in gas leakage detection point 3. Measured media is of the gas, meaning it could be air, inert gas, fuel air mixture or charge air mixture, depending on the failure mode detected. The third measurem...";
CM_ SG_ 2566673406 GssFlLkg1Cnntrtn "Gaseous Fuel Leakage 1 Concentration: Percentage of detected gaseous fuel leak compared to the lower explosion limit (LEL). 100% means the measured value is on the lower explosion limit. 0% means no detected gaseous fuel in measurement point. The mea...";
CM_ SG_ 2566673406 GssFlLkg2Cnntrtn "Gaseous Fuel Leakage 2 Concentration: Percentage of detected gaseous fuel leak compared to the lower explosion limit (LEL). 100% means the measured value is on the lower explosion limit. 0% means no detected gaseous fuel in measurement point. The sec...";
CM_ SG_ 2566673406 GssFlLkg3Cnntrtn "Gaseous Fuel Leakage 3 Concentration: Percentage of detected gaseous fuel leak compared to the lower explosion limit (LEL). 100% means the measured value is on the lower explosion limit. 0% means no detected gaseous fuel in measurement point. The thi...";
CM_ BO_ 2566674174 "SCR Operator Inducement Information 2";
CM_ SG_ 2566674174 AftrtrtmntSCRMlfntnTm "Aftertreatment SCR Malfunction Time: Indicates the amount of time an error condition has been active due to a malfunction in the Aftertreatment SCR system.The source of the malfunction condition could be a component failure, detection of tampering, o...";
CM_ SG_ 2566674174 SCROperatorInducementTotalTime "SCR Operator Inducement Total Time: Indicates the time that operator inducement has been active. This will accumulate over the life of the product and will never be reset.";
CM_ BO_ 2566674430 "SCR Operator Inducement Information 1";
CM_ SG_ 2566674430 DslExhstFldQltMlfntnTm "Diesel Exhaust Fluid Quality Malfunction Time: Indicates the amount of time an error has been active due to detection of low Diesel Exhaust Fluid Quality. This will accumulate over the life of the product and will never be reset.";
CM_ SG_ 2566674430 DslExhstFldTnk1EmptTm "Diesel Exhaust Fluid Tank 1 Empty Time: Indicates the time the Diesel Exhaust Fluid Tank 1 Level is indicated as empty. This will accumulate over the life of the product and will never be reset.";
CM_ BO_ 2566674686 "Turbocharger Information 7";
CM_ SG_ 2566674686 EngnTrhrgr2LOlPrssr "Engine Turbocharger 2 Lube Oil Pressure: Gage pressure of oil in the lubrication system for the 2nd turbocharger.";
CM_ SG_ 2566674686 EngnTrhrgr2OlTmprtr "Engine Turbocharger 2 Oil Temperature: Temperature of the lubricant for the second turbocharger.";
CM_ SG_ 2566674686 EngnTrhrgr3LOlPrssr "Engine Turbocharger 3 Lube Oil Pressure: Gage pressure of oil in the lubrication system for the 3rd turbocharger.";
CM_ SG_ 2566674686 EngnTrhrgr4LOlPrssr "Engine Turbocharger 4 Lube Oil Pressure: Gage pressure of oil in the lubrication system for the 4th turbocharger.";
CM_ BO_ 2566675966 "High Voltage Energy Storage System Configuration";
CM_ SG_ 2566675966 HVESSNominalVoltage "HVESS Nominal Voltage: Per the HVES manufacturer, this is the nominal operating voltage of the High Voltage Energy Storage System (or Pack 1 in systems with only one pack), e.g. “300V” or “600V”.This parameter provides HVES system level information. ...";
CM_ SG_ 2566675966 HVESSRmmnddMnmmOprtngVltg "HVESS Recommended Minimum Operating Voltage: Per the HVES manufacturer, this is the minimum recommended voltage level for High Voltage Energy Storage System (or Pack 1 in systems with only one pack) operation.  Operating below this value may compromi...";
CM_ SG_ 2566675966 HVESSRmmnddMxmmOprtngVltg "HVESS Recommended Maximum Operating Voltage: Per the HVES manufacturer, this is the maximum recommended voltage level for High Voltage Energy Storage System (or Pack 1 in systems with only one pack) operation.  Operating above this value may compromi...";
CM_ SG_ 2566675966 HVESSRmmnddMnmmSttOfChrg "HVESS Recommended Minimum State Of Charge: Per the HVES manufacturer, this is the recommended minimum state of charge for High Voltage Energy Storage System (or Pack 1 in systems with only one pack) operation.  Operating below this value may compromi...";
CM_ SG_ 2566675966 HVESSRmmnddMxmmSttOfChrg "HVESS Recommended Maximum State Of Charge: Per the HVES manufacturer, this is the recommended maximum state of charge for High Voltage Energy Storage System (or Pack 1 in systems with only one pack) operation.  Operating above this value may compromi...";
CM_ SG_ 2566675966 HVESSRmmnddMxmmOprtngTmprtr "HVESS Recommended Maximum Operating Temperature: Per the HVES manufacturer, this is the recommended maximum temperature for High Voltage Energy Storage System (or Pack 1 in systems with only one pack) operation.  Operating above this value may damage...";
CM_ SG_ 2566675966 HVESSRmmnddMnmmOprtngTmprtr "HVESS Recommended Minimum Operating Temperature: Per the HVES manufacturer, this is the recommended minimum temperature for High Voltage Energy Storage System (or Pack 1 in systems with only one pack) operation.  Operating below this value may damage...";
CM_ SG_ 2566675966 HVESSCellMaximumVoltageLimit "HVESS Cell Maximum Voltage Limit: Per the HVES manufacturer, this is the maximum cell voltage for High Voltage Energy Storage System (or Pack 1 in systems with only one pack) operation.  Operating above this value may damage HVES hardware, or comprom...";
CM_ SG_ 2566675966 HVESSCellMinimumVoltageLimit "HVESS Cell Minimum Voltage Limit: Per the HVES manufacturer, this is the minimum cell voltage for High Voltage Energy Storage System (or Pack 1 in systems with only one pack) operation.  Operating below this value may damage HVES hardware, or comprom...";
CM_ SG_ 2566675966 HVESSNumberofHVESPsConfigured "HVESS Number of HVESPs Configured: The number of High Voltage Energy Storage Packs that are currently configured in the HVESS system.";
CM_ BO_ 2566687742 "Aftertreatment 1 Particulate Sensor Information 2";
CM_ SG_ 2566687742 Aftrtrtmnt1PrtltSnsrDttnStts "Aftertreatment 1 Particulate Sensor Detection Status: Detection status of the particulate sensor0000b = Initialization for particulate matter detection0001b = Waiting for dew point (see SPN 6784)0010b = Particulate matter detection0011b = Heater is a...";
CM_ SG_ 2566687742 Aftrtrtmnt1PrtltSnsrHtrRsstn "Aftertreatment 1 Particulate Sensor Heater Resistance: The resistance of the particulate sensor heater.";
CM_ SG_ 2566687742 Aftrtrtmnt1PrtltSnsrMxmmRsstn "Aftertreatment 1 Particulate Sensor Maximum Resistance: This is the maximum resistance that the particulate sensor can measure.";
CM_ SG_ 2566687742 Aftrtrtmnt1PrtltSnsrPwrSppl "Aftertreatment 1 Particulate Sensor Power Supply: State signal which indicates when the Aftertreatment 1 particulate sensor has power applied to it. Note that this is referring to the power supplied to the sensor, not the power supplied to the contro...";
CM_ SG_ 2566687742 Aftrtrtmnt1PrtltSnsrTmprtr "Aftertreatment 1 Particulate Sensor Temperature: Temperature of the particulate sensor.";
CM_ SG_ 2566687742 Atttt1PttSsRtFdCt "Aftertreatment 1 Particulate Sensor Regeneration Failed Count: This is the number of times that the particulate sensor regeneration process has been attempted but failed to complete this power cycle.";
CM_ BO_ 2566687998 "Aftertreatment 1 Particulate Sensor Information 1";
CM_ SG_ 2566687998 Aftrtrtmnt1PrtltSnsrAtvAmltnTm "Aftertreatment 1 Particulate Sensor Active Accumulation Time: This is the amount of time since the last successful regeneration completed.  The sensor has been accumulating particulate matter since that time.";
CM_ SG_ 2566687998 Aftrtrtmnt1PrtltSnsrHtrStt "Aftertreatment 1 Particulate Sensor Heater State: The states of the particulate sensor heater.  The heater will change states from 11b to 10b, 10b to 01b, and 01b to 00b in a typical heating event.00b = Heater is in closed loop control01b = Heater is...";
CM_ SG_ 2566687998 Aftrtrtmnt1PrtltSnsrRgnrtnStt "Aftertreatment 1 Particulate Sensor Regeneration State: Indicates if the particulate sensor regeneration is currently active, and if so, the reason for the regeneration.0000b = Regeneration is not active0001b = Regneration is active and has been init...";
CM_ SG_ 2566687998 Aftrtrtmnt1PrtltSnsrRgnrtnStts "Aftertreatment 1 Particulate Sensor Regeneration Status: The status of the most recent attempt of this power cycle to activate the particulate sensor regeneration process. This will not be updated until the regeneration is no longer active, as indica...";
CM_ SG_ 2566687998 Aftrtrtmnt1PrtltSnsrRsstn "Aftertreatment 1 Particulate Sensor Resistance: This sensor is located in the exhaust stream somewhere after the DPF, but not necessarily immediately after the DPF.  It provides a resistance value that can be used to determine particulate matter in t...";
CM_ SG_ 2566687998 Atttt1PttSsTBtwRts "Aftertreatment 1 Particulate Sensor Time Between Regenerations: This is the time between the last two successful regenerations of the particulate sensor for the current power cycle. This parameter reflects the time when the engine was running, not a ...";
CM_ BO_ 2566689278 "Engine Exhaust NOx";
CM_ SG_ 2566689278 EngineExhaustDesiredNOx "Engine Exhaust Desired NOx: Desired NOx concentration in the engine exhaust, prior to any aftertreatment of the exhaust.";
CM_ SG_ 2566689278 EngineExhaustNOx "Engine Exhaust NOx: Calculated NOx concentration for the total engine exhaust, prior to any aftertreatment of the exhaust.  This parameter is primarily intended for engines that have separate NOx sensors in separate exhaust manifolds, but the engine ...";
CM_ SG_ 2566689278 EngnExhstNOxSnsrPwrSppl "Engine Exhaust NOx Sensor Power Supply: State signal which indicates when the engine exhaust NOx sensor power supply driver output is being driven. On means the ECU is powering the engine exhaust NOx sensor. Note that the ECU is external to the senso...";
CM_ BO_ 2566689534 "Air Fuel Ratio";
CM_ SG_ 2566689534 EngineMainChamberAirFuelRatio "Engine Main Chamber Air Fuel Ratio: Actual air to fuel ratio of the charge entering the cylinder main chamber.";
CM_ SG_ 2566689534 EnginePrechamberAirFuelRatio "Engine Prechamber Air Fuel Ratio: Actual air to fuel ratio of the charge entering the cylinder prechamber.";
CM_ SG_ 2566689534 EngnMnChmrDsrdArFlRt "Engine Main Chamber Desired Air Fuel Ratio: Desired air to fuel ratio of the charge entering the cylinder main chamber.";
CM_ SG_ 2566689534 EngnPrhmrDsrdArFlRt "Engine Prechamber Desired Air Fuel Ratio: Desired air to fuel ratio of the charge entering the cylinder prechamber.";
CM_ BO_ 2566689790 "Gaseous Fuel Pressure 2";
CM_ SG_ 2566689790 EngnMnChmrFlAsltPrssr "Engine Main Chamber Fuel Absolute Pressure: Absolute pressure of the gaseous fuel for the main chamber of the cylinder. This parameter is intended for applications, which use a pre and main chamber fuel systems, which report the pressure of more than...";
CM_ SG_ 2566689790 EngnMnChmrFlDsrdAsltPrssr "Engine Main Chamber Fuel Desired Absolute Pressure: Desired absolute pressure of the gaseous fuel for the main chamber of the cylinder. This parameter is intended for applications with pre and main chamber fuel systems, which report the pressure of m...";
CM_ SG_ 2566689790 EngnPrhmrFlAsltPrssr "Engine Prechamber Fuel Absolute Pressure: Absolute pressure of the gaseous fuel for the separate cylinder pre-chamber rail. This parameter is intended for applications, which use a pre and main chamber fuel systems, which report the pressure of more ...";
CM_ SG_ 2566689790 EngnPrhmrFlDsrdAsltPrssr "Engine Prechamber Fuel Desired Absolute Pressure: Desired absolute pressure of the gaseous fuel in the separate cylinder pre-chamber rail. This parameter is intended for applications with pre and main chamber fuel systems, which report the pressure o...";
CM_ BO_ 2566690046 "Aftertreatment System Abuse Information";
CM_ SG_ 2566690046 AfterrunCompleteThisCycle "After-run Complete This Cycle: Indication of after-run routine completion in the current power cycle.Complete This Cycle parameters are used to indicate to the engine controller that is powering the aftertreatment controller via relay that it is ok t...";
CM_ SG_ 2566690046 AttttDsExstFdDsCdwCptLstC "Aftertreatment Diesel Exhaust Fluid Doser Cooldown Complete Last Cycle: Indication of cooldown routine completion in the previous power cycle.00b = Not complete01b = Complete10b = Error11b = Not SupportedNote:  One purpose for tracking the status of ...";
CM_ SG_ 2566690046 AttttDsExstFdDsCdwCptTsC "Aftertreatment Diesel Exhaust Fluid Doser Cooldown Complete This Cycle: Indication of cooldown routine completion in the current power cycle.Complete This Cycle parameters are used to indicate to the engine controller that is powering the aftertreatm...";
CM_ SG_ 2566690046 AttttDsExstFdDsCdwItptCt "Aftertreatment Diesel Exhaust Fluid Doser Cooldown Interrupt Count: Non-volatile record of the number of interrupted cooldown routines since the last clear event.  The counter shall be reset by PGN 56832 request.";
CM_ SG_ 2566690046 AttttDsExstFdDsPCptLstC "Aftertreatment Diesel Exhaust Fluid Doser Purge Complete Last Cycle: Indication of purge routine completion in the previous power cycle00b = Not complete01b = Complete10b = Error11b = Not SupportedNote:  One purpose for tracking the status of the Die...";
CM_ SG_ 2566690046 AttttDsExstFdDsPCptTsC "Aftertreatment Diesel Exhaust Fluid Doser Purge Complete This Cycle: Indication of purge routine completion in the current power cycle.Complete This Cycle parameters are used to indicate to the engine controller that is powering the aftertreatment co...";
CM_ SG_ 2566690046 AttttDsExstFdDsPItptCt "Aftertreatment Diesel Exhaust Fluid Doser Purge Interrupt Count: Non-volatile record of the number of interrupted purge routines since the last clear event.  The counter shall be reset by PGN 56832 request.";
CM_ BO_ 2566690558 "Engine Information 2";
CM_ SG_ 2566690558 EngineCommonRailOilPressure "Engine Common Rail Oil Pressure: Gage pressure of oil in common rail's lubrication system as provided by oil pump.";
CM_ SG_ 2566690558 EngineExhaustPressure2 "Engine Exhaust Pressure 2: Gage pressure of the exhaust gasses as measured at the turbine intake of the turbocharger of exhaust bank 2. See SPN 1209 for exhaust bank 1.";
CM_ SG_ 2566690558 EngnCmmnRlOlAsltPrssr "Engine Common Rail Oil Absolute Pressure: Absolute pressure of oil in common rail's lubrication system as provided by oil pump.";
CM_ SG_ 2566690558 EngnExhstPrssr1ExtnddRng "Engine Exhaust Pressure 1 (Extended Range): Gage pressure of the exhaust gasses as measured at the turbine intake of the turbocharger. This SP to be used for inline engines or exhaust bank 1 of multiple bank engines.  See SPN 1209 for alternate resol...";
CM_ SG_ 2566690558 EOFtItPssHRstExtddR "Engine Oil Filter Intake Pressure (High Resolution/Extended Range): Gage pressure of the engine oil before the oil reaches the oil filter. See SPN 1208 for alternate resolution.";
CM_ BO_ 2566690814 "Electronic Steering Control 2";
CM_ SG_ 2566690814 CircleSteerModeActuatorState "Circle Steer Mode Actuator State: Signal which indicates the current state of the actuator that control the circle steering mode00b = Circle Steer Mode actuator inactive01b = Circle Steer Mode actuator active10b = Error11b = Not Available";
CM_ SG_ 2566690814 CrabSteerModeActuatorState "Crab Steer Mode Actuator State: Signal which indicates the current state of the actuator that control the crab steering mode00b = Crab Steer Mode actuator inactive01b = Crab Steer Mode actuator active10b = Error11b = Not Available";
CM_ SG_ 2566690814 FrontSteeringAxleCenteredStatus "Front Steering Axle Centered Status: The status of the front steering axle being centered. The axle is centered if the axle's centerline is parallel to the vehicle's X-axis, where the vehicle's X-axis is as defined in SAE J67000b = Front Axle Centere...";
CM_ SG_ 2566690814 RearSteeringAxleCenteredStatus "Rear Steering Axle Centered Status: The status of the rear steering axle being centered. The axle is centered if the axle's centerline is parallel to the vehicle's X-axis, where the vehicle's X-axis is as defined in SAE J67000b = Rear Axle Centered01...";
CM_ SG_ 2566690814 StrngCntrllrECUTmprtr "Steering Controller ECU Temperature: Temperature of the steering controller ECU";
CM_ SG_ 2566690814 Wheel2SteerActuatorState "2 Wheel Steer Actuator State: The current state of the actuator that control the 2 wheel steering mode00b = 2 Wheel Steer actuator inactive01b = 2 Wheel Steer actuator active10b = Error11b = Not Available";
CM_ SG_ 2566690814 Wheel4SteerActuatorState "4 Wheel Steer Actuator State: Signal which indicates the current state of the actuator that control the 4 wheel steering mode00b = 4 Wheel Steer actuator inactive01b = 4 Wheel Steer actuator active10b = Error11b = Not Available";
CM_ SG_ 2566690814 RequestedSteeringMode "Requested Steering Mode: The operator's desired steering input to the electronic steering controller. For the individual status parameters, reference Two Wheel, Circle, and Crab Mode Switch Inputs.000b = 2 Wheel Steer Mode001b = Circle Steer Mode010b...";
CM_ SG_ 2566690814 SteeringModeTwoWheelSwitchInput "Steering Mode Two Wheel Switch Input: The status of the Two Wheel Steering Mode input to the ECU for determining the operator requested steering mode.00b = Off01b = On10b = Error11b = Not available";
CM_ SG_ 2566690814 SteeringModeCrabSwitchInput "Steering Mode Crab Switch Input: The status of the Crab Steering Mode input to the ECU for determining the operator requested steering mode.00b = Off01b = On10b = Error11b = Not available";
CM_ SG_ 2566690814 SteeringModeCircleSwitchInput "Steering Mode Circle Switch Input: The status of the Circle Steering Mode input to the ECU for determining the operator requested steering mode00b = Off01b = On10b = Error11b = Not available";
CM_ SG_ 2566690814 SteeringModeStatus "Steering Mode Status: The actual mode of the all-wheel steering system.000b = 2 Wheel Steer Mode001b = Circle Steer Mode010b = Reserved for future use011b = Crab Steer Mode100b = Reserved for future use101b = Reserved for future use110b = Error111b =...";
CM_ BO_ 2566691326 "Assembly Unit Identification";
CM_ SG_ 2566691326 AssemblyUnitIdentification "Assembly Unit Identification: A combination of alphanumeric characters representing the Identification number of an assembly unit installed on a component.  Multiple assembly unit IDs can be transmitted by appropriately setting Number of Assembly Uni...";
CM_ SG_ 2566691326 NmrfAssmlUntIdntftnFlds "Number of Assembly Unit Identification Fields: Number of Assembly Unit Identification designators represented in the Assembly Unit Identification parameter group.";
CM_ BO_ 2566691582 "Joystick 3 Lamp Status";
CM_ SG_ 2566691582 Joystick3Lamp10Status "Joystick 3 Lamp 10 Status: Report the actual value of Joystick 3 Lamp 1000b = Off01b = On10b = Flashing11b = Not available";
CM_ SG_ 2566691582 Joystick3Lamp1Status "Joystick 3 Lamp 1 Status: Report the actual value of Joystick 3 Lamp 100b = Off01b = On10b = Flashing11b = Not available";
CM_ SG_ 2566691582 Joystick3Lamp2Status "Joystick 3 Lamp 2 Status: Report the actual value of Joystick 3 Lamp 200b = Off01b = On10b = Flashing11b = Not available";
CM_ SG_ 2566691582 Joystick3Lamp3Status "Joystick 3 Lamp 3 Status: Report the actual value of Joystick 3 Lamp 300b = Off01b = On10b = Flashing11b = Not available";
CM_ SG_ 2566691582 Joystick3Lamp4Status "Joystick 3 Lamp 4 Status: Report the actual value of Joystick 3 Lamp 400b = Off01b = On10b = Flashing11b = Not available";
CM_ SG_ 2566691582 Joystick3Lamp5Status "Joystick 3 Lamp 5 Status: Report the actual value of Joystick 3 Lamp 500b = Off01b = On10b = Flashing11b = Not available";
CM_ SG_ 2566691582 Joystick3Lamp6Status "Joystick 3 Lamp 6 Status: Report the actual value of Joystick 3 Lamp 600b = Off01b = On10b = Flashing11b = Not available";
CM_ SG_ 2566691582 Joystick3Lamp7Status "Joystick 3 Lamp 7 Status: Report the actual value of Joystick 3 Lamp 700b = Off01b = On10b = Flashing11b = Not available";
CM_ SG_ 2566691582 Joystick3Lamp8Status "Joystick 3 Lamp 8 Status: Report the actual value of Joystick 3 Lamp 800b = Off01b = On10b = Flashing11b = Not available";
CM_ SG_ 2566691582 Joystick3Lamp9Status "Joystick 3 Lamp 9 Status: Report the actual value of Joystick 3 Lamp 900b = Off01b = On10b = Flashing11b = Not available";
CM_ BO_ 2566691838 "Joystick 2 Lamp Status";
CM_ SG_ 2566691838 Joystick2Lamp10Status "Joystick 2 Lamp 10 Status: Report the actual value of Joystick 2 Lamp 1000b = Off01b = On10b = Flashing11b = Not available";
CM_ SG_ 2566691838 Joystick2Lamp1Status "Joystick 2 Lamp 1 Status: Report the actual value of Joystick 2 Lamp 100b = Off01b = On10b = Flashing11b = Not available";
CM_ SG_ 2566691838 Joystick2Lamp2Status "Joystick 2 Lamp 2 Status: Report the actual value of Joystick 2 Lamp 200b = Off01b = On10b = Flashing11b = Not available";
CM_ SG_ 2566691838 Joystick2Lamp3Status "Joystick 2 Lamp 3 Status: Report the actual value of Joystick 2 Lamp 300b = Off01b = On10b = Flashing11b = Not available";
CM_ SG_ 2566691838 Joystick2Lamp4Status "Joystick 2 Lamp 4 Status: Report the actual value of Joystick 2 Lamp 400b = Off01b = On10b = Flashing11b = Not available";
CM_ SG_ 2566691838 Joystick2Lamp5Status "Joystick 2 Lamp 5 Status: Report the actual value of Joystick 2 Lamp 500b = Off01b = On10b = Flashing11b = Not available";
CM_ SG_ 2566691838 Joystick2Lamp6Status "Joystick 2 Lamp 6 Status: Report the actual value of Joystick 2 Lamp 600b = Off01b = On10b = Flashing11b = Not available";
CM_ SG_ 2566691838 Joystick2Lamp7Status "Joystick 2 Lamp 7 Status: Report the actual value of Joystick 2 Lamp 700b = Off01b = On10b = Flashing11b = Not available";
CM_ SG_ 2566691838 Joystick2Lamp8Status "Joystick 2 Lamp 8 Status: Report the actual value of Joystick 2 Lamp 800b = Off01b = On10b = Flashing11b = Not available";
CM_ SG_ 2566691838 Joystick2Lamp9Status "Joystick 2 Lamp 9 Status: Report the actual value of Joystick 2 Lamp 900b = Off01b = On10b = Flashing11b = Not available";
CM_ BO_ 2566692094 "Joystick 1 Lamp Status";
CM_ SG_ 2566692094 Joystick1Lamp10Status "Joystick 1 Lamp 10 Status: Report the actual value of Joystick 1 Lamp 1000b = Off01b = On10b = Flashing11b = Not available";
CM_ SG_ 2566692094 Joystick1Lamp1Status "Joystick 1 Lamp 1 Status: Report the actual value of Joystick 1 Lamp 100b = Off01b = On10b = Flashing11b = Not available";
CM_ SG_ 2566692094 Joystick1Lamp2Status "Joystick 1 Lamp 2 Status: Report the actual value of Joystick 1 Lamp 200b = Off01b = On10b = Flashing11b = Not available";
CM_ SG_ 2566692094 Joystick1Lamp3Status "Joystick 1 Lamp 3 Status: Report the actual value of Joystick 1 Lamp 300b = Off01b = On10b = Flashing11b = Not available";
CM_ SG_ 2566692094 Joystick1Lamp4Status "Joystick 1 Lamp 4 Status: Report the actual value of Joystick 1 Lamp 400b = Off01b = On10b = Flashing11b = Not available";
CM_ SG_ 2566692094 Joystick1Lamp5Status "Joystick 1 Lamp 5 Status: Report the actual value of Joystick 1 Lamp 500b = Off01b = On10b = Flashing11b = Not available";
CM_ SG_ 2566692094 Joystick1Lamp6Status "Joystick 1 Lamp 6 Status: Report the actual value of Joystick 1 Lamp 600b = Off01b = On10b = Flashing11b = Not available";
CM_ SG_ 2566692094 Joystick1Lamp7Status "Joystick 1 Lamp 7 Status: Report the actual value of Joystick 1 Lamp 700b = Off01b = On10b = Flashing11b = Not available";
CM_ SG_ 2566692094 Joystick1Lamp8Status "Joystick 1 Lamp 8 Status: Report the actual value of Joystick 1 Lamp 800b = Off01b = On10b = Flashing11b = Not available";
CM_ SG_ 2566692094 Joystick1Lamp9Status "Joystick 1 Lamp 9 Status: Report the actual value of Joystick 1 Lamp 900b = Off01b = On10b = Flashing11b = Not available";
CM_ BO_ 2566692862 "Dash Display 2";
CM_ SG_ 2566692862 DisplayRemainPowered "Display Remain Powered: Indicates the ECU needs the display (i.e. monitor device) to continue to remain powered after ignition key off. An ECU would use this when the ECU needs the display to remain powered after key off so the ECU can communicate to...";
CM_ SG_ 2566692862 EngineFuel2Tank1Level "Engine Fuel 2 Tank 1 Level: Fuel level in tank 1 containing the second fuel type..";
CM_ SG_ 2566692862 EngineFuel2Tank2Level "Engine Fuel 2 Tank 2 Level: Fuel level in tank 2 containing the second fuel type.";
CM_ SG_ 2566692862 EngineFuel2Tank3Level "Engine Fuel 2 Tank 3 Level: Fuel level in tank 3 containing the second fuel type.";
CM_ SG_ 2566692862 EngineFuel2Tank4Level "Engine Fuel 2 Tank 4 Level: Fuel level in tank 4 containing the second fuel type.";
CM_ SG_ 2566692862 EngineOilLevelHighLow "Engine Oil Level High / Low: Conveys the amount of current volume of engine oil compared to recommended volume. Positive values indicate overfill.  Zero means the engine oil is filled to the recommended level. Negative values indicate the amount in w...";
CM_ SG_ 2566692862 EngnOlFltrDffrntlPrssrExtnddRng "Engine Oil Filter Differential Pressure (Extended Range): Change in engine oil differential pressure measured across the oil filter element. The differential pressure is the measured as the pressure at the filter intake with respect to the pressure a...";
CM_ BO_ 2566697470 "Engine Ignition Control Module Status";
CM_ SG_ 2566697470 EngnIgntnCntrlMdl1Stt "Engine Ignition Control Module 1 State: This parameter is used to indicate the current state of Engine Ignition Control Module 1.000b = Disabled (by user)001b = Shutdown (due to alarm)010b = Stalled (waiting for timing signals)011b = Firing Ignition ...";
CM_ SG_ 2566697470 EngnIgntnCntrlMdl1Tmprtr "Engine Ignition Control Module 1 Temperature: Measured internal temperature of the Engine Ignition Control Module 1 circuitry.";
CM_ SG_ 2566697470 EngnIgntnCntrlMdl2Stt "Engine Ignition Control Module 2 State: This parameter is used to indicate the current state of Engine Ignition Control Module 2.000b = Disabled (by user)001b = Shutdown (due to alarm)010b = Stalled (waiting for timing signals)011b = Firing Ignition ...";
CM_ SG_ 2566697470 EngnIgntnCntrlMdl2Tmprtr "Engine Ignition Control Module 2 Temperature: Measured internal temperature of the Engine Ignition Control Module 2 circuitry.";
BA_DEF_ SG_  "SPN" INT 0 524287;
BA_DEF_ BO_  "VFrameFormat" ENUM  "StandardCAN","ExtendedCAN","reserved","J1939PG";
BA_DEF_DEF_  "SPN" 0;
BA_DEF_DEF_  "VFrameFormat" "J1939PG";
BA_ "SPN" SG_ 2566648318 OlDrsMntrEltrnsTmprtrStts 8190;
BA_ "SPN" SG_ 2566648318 OlDrsMntrEnvrnmntStts 8187;
BA_ "SPN" SG_ 2566648318 OlDrsMntrSgnlPrssngEltrnsStts 8189;
BA_ "SPN" SG_ 2566648318 OlDrsMntrSnsngElmntStts 8188;
BA_ "SPN" SG_ 2566648318 OlDrsMntrSttsIdntftnNmr 8185;
BA_ "SPN" SG_ 2566648318 OlDrsMntrTtlnmrfSnsrs 8186;
BA_ "SPN" SG_ 2566649086 Atttt2DOCIttDPFOttDtPss 8165;
BA_ "SPN" SG_ 2566649086 Atttt2DsOxdtCtstItPss 8163;
BA_ "SPN" SG_ 2566649086 Atttt2DsOxdtCtstOttPss 8164;
BA_ "SPN" SG_ 2566649342 Atttt1DOCIttDPFOttDtPss 8162;
BA_ "SPN" SG_ 2566649342 Atttt1DsOxdtCtstItPss 8160;
BA_ "SPN" SG_ 2566649342 Atttt1DsOxdtCtstOttPss 8161;
BA_ "SPN" SG_ 2566649598 HorizontalDilutionofPrecision 8129;
BA_ "SPN" SG_ 2566649598 PositionDilutionofPrecision 8131;
BA_ "SPN" SG_ 2566649598 TimeDilutionofPrecision 8132;
BA_ "SPN" SG_ 2566649598 TotalNumberofSatellitesinView 8128;
BA_ "SPN" SG_ 2566649598 VerticalDilutionofPrecision 8130;
BA_ "SPN" SG_ 2566649854 PpsMtCtF3CtCdStts 8069;
BA_ "SPN" SG_ 2566649854 PpsMtCtF3CtSttsRsCd 8068;
BA_ "SPN" SG_ 2566649854 PropulsionMotorCoolantFan3Power 8072;
BA_ "SPN" SG_ 2566649854 PrplsnMtrClntFn3CntrlTmprtr 8071;
BA_ "SPN" SG_ 2566649854 PrplsnMtrClntFn3EnlStts 8067;
BA_ "SPN" SG_ 2566649854 PrplsnMtrClntFn3MtrSpd 8070;
BA_ "SPN" SG_ 2566649854 PrplsnMtrClntFn3OprtngStts 8074;
BA_ "SPN" SG_ 2566649854 PrplsnMtrClntFn3SrvIndtr 8073;
BA_ "SPN" SG_ 2566650110 PpsMtCtF2CtCdStts 8057;
BA_ "SPN" SG_ 2566650110 PpsMtCtF2CtSttsRsCd 8056;
BA_ "SPN" SG_ 2566650110 PropulsionMotorCoolantFan2Power 8060;
BA_ "SPN" SG_ 2566650110 PrplsnMtrClntFn2CntrlTmprtr 8059;
BA_ "SPN" SG_ 2566650110 PrplsnMtrClntFn2EnlStts 8055;
BA_ "SPN" SG_ 2566650110 PrplsnMtrClntFn2MtrSpd 8058;
BA_ "SPN" SG_ 2566650110 PrplsnMtrClntFn2OprtngStts 8062;
BA_ "SPN" SG_ 2566650110 PrplsnMtrClntFn2SrvIndtr 8061;
BA_ "SPN" SG_ 2566650366 PpsMtCtF1CtCdStts 8045;
BA_ "SPN" SG_ 2566650366 PpsMtCtF1CtSttsRsCd 8044;
BA_ "SPN" SG_ 2566650366 PropulsionMotorCoolantFan1Power 8048;
BA_ "SPN" SG_ 2566650366 PrplsnMtrClntFn1CntrlTmprtr 8047;
BA_ "SPN" SG_ 2566650366 PrplsnMtrClntFn1EnlStts 8043;
BA_ "SPN" SG_ 2566650366 PrplsnMtrClntFn1MtrSpd 8046;
BA_ "SPN" SG_ 2566650366 PrplsnMtrClntFn1OprtngStts 8050;
BA_ "SPN" SG_ 2566650366 PrplsnMtrClntFn1SrvIndtr 8049;
BA_ "SPN" SG_ 2566650622 PwEtsCtF3CtCdStts 8033;
BA_ "SPN" SG_ 2566650622 PwEtsCtF3CtSttsRsCd 8032;
BA_ "SPN" SG_ 2566650622 PwrEltrnsClntFn3CntrlTmprtr 8035;
BA_ "SPN" SG_ 2566650622 PwrEltrnsClntFn3EnlStts 8031;
BA_ "SPN" SG_ 2566650622 PwrEltrnsClntFn3MtrSpd 8034;
BA_ "SPN" SG_ 2566650622 PwrEltrnsClntFn3OprtngStts 8038;
BA_ "SPN" SG_ 2566650622 PwrEltrnsClntFn3Pwr 8036;
BA_ "SPN" SG_ 2566650622 PwrEltrnsClntFn3SrvIndtr 8037;
BA_ "SPN" SG_ 2566650878 PwEtsCtF2CtCdStts 8021;
BA_ "SPN" SG_ 2566650878 PwEtsCtF2CtSttsRsCd 8020;
BA_ "SPN" SG_ 2566650878 PwrEltrnsClntFn2CntrlTmprtr 8023;
BA_ "SPN" SG_ 2566650878 PwrEltrnsClntFn2EnlStts 8019;
BA_ "SPN" SG_ 2566650878 PwrEltrnsClntFn2MtrSpd 8022;
BA_ "SPN" SG_ 2566650878 PwrEltrnsClntFn2OprtngStts 8026;
BA_ "SPN" SG_ 2566650878 PwrEltrnsClntFn2Pwr 8024;
BA_ "SPN" SG_ 2566650878 PwrEltrnsClntFn2SrvIndtr 8025;
BA_ "SPN" SG_ 2566651134 PwEtsCtF1CtCdStts 8009;
BA_ "SPN" SG_ 2566651134 PwEtsCtF1CtSttsRsCd 8008;
BA_ "SPN" SG_ 2566651134 PwrEltrnsClntFn1CntrlTmprtr 8011;
BA_ "SPN" SG_ 2566651134 PwrEltrnsClntFn1EnlStts 8007;
BA_ "SPN" SG_ 2566651134 PwrEltrnsClntFn1MtrSpd 8010;
BA_ "SPN" SG_ 2566651134 PwrEltrnsClntFn1OprtngStts 8014;
BA_ "SPN" SG_ 2566651134 PwrEltrnsClntFn1Pwr 8012;
BA_ "SPN" SG_ 2566651134 PwrEltrnsClntFn1SrvIndtr 8013;
BA_ "SPN" SG_ 2566651390 PropulsionMotorOilPumpPower 8000;
BA_ "SPN" SG_ 2566651390 PrplsnMtrOlPmpCntrllrCmmndStts 7997;
BA_ "SPN" SG_ 2566651390 PrplsnMtrOlPmpCntrllrSttsRsnCd 7996;
BA_ "SPN" SG_ 2566651390 PrplsnMtrOlPmpCntrlTmprtr 7999;
BA_ "SPN" SG_ 2566651390 PrplsnMtrOlPmpEnlStts 7995;
BA_ "SPN" SG_ 2566651390 PrplsnMtrOlPmpMtrSpd 7998;
BA_ "SPN" SG_ 2566651390 PrplsnMtrOlPmpOprtngStts 8002;
BA_ "SPN" SG_ 2566651390 PrplsnMtrOlPmpSrvIndtr 8001;
BA_ "SPN" SG_ 2566651646 PpsMtCtPpCtCdStts 7985;
BA_ "SPN" SG_ 2566651646 PpsMtCtPpCtSttsRsCd 7984;
BA_ "SPN" SG_ 2566651646 PropulsionMotorCoolantPumpPower 7988;
BA_ "SPN" SG_ 2566651646 PrplsnMtrClntPmpCntrlTmprtr 7987;
BA_ "SPN" SG_ 2566651646 PrplsnMtrClntPmpEnlStts 7983;
BA_ "SPN" SG_ 2566651646 PrplsnMtrClntPmpMtrSpd 7986;
BA_ "SPN" SG_ 2566651646 PrplsnMtrClntPmpOprtngStts 7990;
BA_ "SPN" SG_ 2566651646 PrplsnMtrClntPmpSrvIndtr 7989;
BA_ "SPN" SG_ 2566651902 PwEtsCtPpCtCdStts 7973;
BA_ "SPN" SG_ 2566651902 PwEtsCtPpCtSttsRsCd 7972;
BA_ "SPN" SG_ 2566651902 PwrEltrnsClntPmpCntrlTmprtr 7975;
BA_ "SPN" SG_ 2566651902 PwrEltrnsClntPmpEnlStts 7971;
BA_ "SPN" SG_ 2566651902 PwrEltrnsClntPmpMtrSpd 7974;
BA_ "SPN" SG_ 2566651902 PwrEltrnsClntPmpOprtngStts 7978;
BA_ "SPN" SG_ 2566651902 PwrEltrnsClntPmpPwr 7976;
BA_ "SPN" SG_ 2566651902 PwrEltrnsClntPmpSrvIndtr 7977;
BA_ "SPN" SG_ 2566652414 ElectrifiedAccessoryMotorPower 7952;
BA_ "SPN" SG_ 2566652414 ElectrifiedAccessoryMotorSpeed 7950;
BA_ "SPN" SG_ 2566652414 EltrfdAssrMtrCntrllrCmmndStts 7949;
BA_ "SPN" SG_ 2566652414 EltrfdAssrMtrCntrllrSttsRsnCd 7948;
BA_ "SPN" SG_ 2566652414 EltrfdAssrMtrEnlStts 7947;
BA_ "SPN" SG_ 2566652414 EltrfdAssrMtrInstn 8308;
BA_ "SPN" SG_ 2566652414 EltrfdAssrMtrMdmTmprtr 7951;
BA_ "SPN" SG_ 2566652414 EltrfdAssrMtrOprtngStts 7954;
BA_ "SPN" SG_ 2566652414 EltrfdAssrMtrSrvIndtr 7953;
BA_ "SPN" SG_ 2566652670 Atttt1DsExstFdDsSstFz 6802;
BA_ "SPN" SG_ 2566652670 Atttt2DsExstFdDsSstFz 6803;
BA_ "SPN" SG_ 2566652670 DieselExhaustFluidFrozenTime 7938;
BA_ "SPN" SG_ 2566652670 Aftrtrtmnt1SstmHdrrn 7934;
BA_ "SPN" SG_ 2566652670 Aftrtrtmnt2SstmHdrrn 7935;
BA_ "SPN" SG_ 2566652926 SLIBatteryPack1Battery4Capacity 7928;
BA_ "SPN" SG_ 2566652926 SLIBatteryPack1Battery4Health 7929;
BA_ "SPN" SG_ 2566652926 SLIBttP1Btt4PdtdMCVt 7930;
BA_ "SPN" SG_ 2566652926 SLIBttrPk1Bttr4SttfChrg 7927;
BA_ "SPN" SG_ 2566652926 SLIBttrPk1Snsr4IntlztnStts 7931;
BA_ "SPN" SG_ 2566653182 SLIBatteryPack1Battery4Voltage 7926;
BA_ "SPN" SG_ 2566653182 SLIBttrPk1Bttr4NtCrrnt 7924;
BA_ "SPN" SG_ 2566653182 SLIBttrPk1Bttr4Tmprtr 7925;
BA_ "SPN" SG_ 2566653438 SLIBatteryPack1Battery3Capacity 7920;
BA_ "SPN" SG_ 2566653438 SLIBatteryPack1Battery3Health 7921;
BA_ "SPN" SG_ 2566653438 SLIBttP1Btt3PdtdMCVt 7922;
BA_ "SPN" SG_ 2566653438 SLIBttrPk1Bttr3SttfChrg 7919;
BA_ "SPN" SG_ 2566653438 SLIBttrPk1Snsr3IntlztnStts 7923;
BA_ "SPN" SG_ 2566653694 SLIBatteryPack1Battery3Voltage 7918;
BA_ "SPN" SG_ 2566653694 SLIBttrPk1Bttr3NtCrrnt 7916;
BA_ "SPN" SG_ 2566653694 SLIBttrPk1Bttr3Tmprtr 7917;
BA_ "SPN" SG_ 2566653950 SLIBatteryPack1Battery2Capacity 7912;
BA_ "SPN" SG_ 2566653950 SLIBatteryPack1Battery2Health 7913;
BA_ "SPN" SG_ 2566653950 SLIBttP1Btt2PdtdMCVt 7914;
BA_ "SPN" SG_ 2566653950 SLIBttrPk1Bttr2SttfChrg 7911;
BA_ "SPN" SG_ 2566653950 SLIBttrPk1Snsr2IntlztnStts 7915;
BA_ "SPN" SG_ 2566654206 SLIBatteryPack1Battery2Voltage 7910;
BA_ "SPN" SG_ 2566654206 SLIBttrPk1Bttr2NtCrrnt 7908;
BA_ "SPN" SG_ 2566654206 SLIBttrPk1Bttr2Tmprtr 7909;
BA_ "SPN" SG_ 2566654462 SLIBatteryPack1Battery1Capacity 7904;
BA_ "SPN" SG_ 2566654462 SLIBatteryPack1Battery1Health 7905;
BA_ "SPN" SG_ 2566654462 SLIBttP1Btt1PdtdMCVt 7906;
BA_ "SPN" SG_ 2566654462 SLIBttrPk1Bttr1SttfChrg 7903;
BA_ "SPN" SG_ 2566654462 SLIBttrPk1Snsr1IntlztnStts 7907;
BA_ "SPN" SG_ 2566654718 SLIBatteryPack1Battery1Voltage 7902;
BA_ "SPN" SG_ 2566654718 SLIBttrPk1Bttr1NtCrrnt 7900;
BA_ "SPN" SG_ 2566654718 SLIBttrPk1Bttr1Tmprtr 7901;
BA_ "SPN" SG_ 2566654974 AtlMxmmAvllEngnPrntFl 8630;
BA_ "SPN" SG_ 2566654974 EsttdEPstLsssPtTqHRst 7837;
BA_ "SPN" SG_ 2566654974 NmnlFrtnPrntTrqHghRsltn 12926;
BA_ "SPN" SG_ 2566654974 AsltEngnLdPrntArMss 13131;
BA_ "SPN" SG_ 2566655742 RearHitchPitchSensitivity 7813;
BA_ "SPN" SG_ 2566655742 RearHitchRollSensitivity 7812;
BA_ "SPN" SG_ 2566656254 BarometricAbsolutePressure2 7781;
BA_ "SPN" SG_ 2566656254 EngineIntake2AirTemperature 7850;
BA_ "SPN" SG_ 2566656254 EngnPwrDrtRltvHmdtDffrn 12852;
BA_ "SPN" SG_ 2566656510 EngnTtlGssFlVlmUsd 7455;
BA_ "SPN" SG_ 2566656510 EngnTtlGssIdlFlVlmUsd 7456;
BA_ "SPN" SG_ 2566658302 TotalPayloadTransactionCount 7701;
BA_ "SPN" SG_ 2566658558 TotalDeliveredPayloadWeight 7699;
BA_ "SPN" SG_ 2566658558 TotalHaulCycleCount 7700;
BA_ "SPN" SG_ 2566661118 EngineTotalDieselFuelDemand 7597;
BA_ "SPN" SG_ 2566661374 Aftrtrtmnt2DslExhstFldTnkHtr2 7575;
BA_ "SPN" SG_ 2566661374 Aftrtrtmnt2DslExhstFldTnkVlm2 7531;
BA_ "SPN" SG_ 2566661374 Atttt2DsExstFdTTpt2 7574;
BA_ "SPN" SG_ 2566661630 Aftrtrtmnt1DslExhstFldTnkHtr2 7573;
BA_ "SPN" SG_ 2566661630 Aftrtrtmnt1DslExhstFldTnkVlm2 7530;
BA_ "SPN" SG_ 2566661630 Atttt1DsExstFdTTpt2 7572;
BA_ "SPN" SG_ 2566661886 Atttt2DsExstFdCt2Tpt 7535;
BA_ "SPN" SG_ 2566661886 Atttt2DsExstFdCtTpt 7529;
BA_ "SPN" SG_ 2566662142 Atttt1DsExstFdCt1Tpt 5480;
BA_ "SPN" SG_ 2566662142 Atttt1DsExstFdCt2Tpt 7528;
BA_ "SPN" SG_ 2566662654 LaneDepartureAngleLeft 7479;
BA_ "SPN" SG_ 2566662654 LaneDepartureAngleRight 7480;
BA_ "SPN" SG_ 2566662654 LaneMarkQualityontheLeftSide 7481;
BA_ "SPN" SG_ 2566662654 LaneMarkQualityontheRightSide 7482;
BA_ "SPN" SG_ 2566662654 LeftLaneMarkerType 8144;
BA_ "SPN" SG_ 2566662654 LftDstntLnMrkfrmVhlsMddl 7476;
BA_ "SPN" SG_ 2566662654 RghtDstntLnMrkfrmVhlsMddl 7477;
BA_ "SPN" SG_ 2566662654 RightLaneMarkerType 8143;
BA_ "SPN" SG_ 2566662654 RoadCurvatureBasedonLaneMarks 7478;
BA_ "SPN" SG_ 2566662910 OprtrIndmntTmtFnlIndmntAtn 7719;
BA_ "SPN" SG_ 2566662910 OprtrIndmntTmtTrqDrtLvl1 7426;
BA_ "SPN" SG_ 2566662910 OprtrIndmntTmtTrqDrtLvl2 7428;
BA_ "SPN" SG_ 2566662910 OprtrIndmntTrqDrtLvl1 7425;
BA_ "SPN" SG_ 2566662910 OprtrIndmntTrqDrtLvl2 7427;
BA_ "SPN" SG_ 2566663166 AppldVhlSpdLmtHghRsltn 7420;
BA_ "SPN" SG_ 2566663166 CrsCntrlAdjstdMxmmSpd 7495;
BA_ "SPN" SG_ 2566663166 EngnExtrnlIdlRqstFdk 8441;
BA_ "SPN" SG_ 2566663166 SAddssCtDvSttCsCt 9844;
BA_ "SPN" SG_ 2566663422 TrlrBrkClprLnngClrnAxl1Lft 7406;
BA_ "SPN" SG_ 2566663422 TrlrBrkClprLnngClrnAxl1Rght 7407;
BA_ "SPN" SG_ 2566663422 TrlrBrkClprLnngClrnAxl2Lft 7408;
BA_ "SPN" SG_ 2566663422 TrlrBrkClprLnngClrnAxl2Rght 7409;
BA_ "SPN" SG_ 2566663422 TrlrBrkClprLnngClrnAxl3Lft 7410;
BA_ "SPN" SG_ 2566663422 TrlrBrkClprLnngClrnAxl3Rght 7411;
BA_ "SPN" SG_ 2566663422 TrlrBrkClprLnngClrnAxl4Lft 7412;
BA_ "SPN" SG_ 2566663422 TrlrBrkClprLnngClrnAxl4Rght 7413;
BA_ "SPN" SG_ 2566663422 TrlrBrkClprLnngClrnAxl5Lft 7414;
BA_ "SPN" SG_ 2566663422 TrlrBrkClprLnngClrnAxl5Rght 7415;
BA_ "SPN" SG_ 2566663422 TrtrBrkClprLnngClrnAxl1Lft 7396;
BA_ "SPN" SG_ 2566663422 TrtrBrkClprLnngClrnAxl1Rght 7397;
BA_ "SPN" SG_ 2566663422 TrtrBrkClprLnngClrnAxl2Lft 7398;
BA_ "SPN" SG_ 2566663422 TrtrBrkClprLnngClrnAxl2Rght 7399;
BA_ "SPN" SG_ 2566663422 TrtrBrkClprLnngClrnAxl3Lft 7400;
BA_ "SPN" SG_ 2566663422 TrtrBrkClprLnngClrnAxl3Rght 7401;
BA_ "SPN" SG_ 2566663422 TrtrBrkClprLnngClrnAxl4Lft 7402;
BA_ "SPN" SG_ 2566663422 TrtrBrkClprLnngClrnAxl4Rght 7403;
BA_ "SPN" SG_ 2566663422 TrtrBrkClprLnngClrnAxl5Lft 7404;
BA_ "SPN" SG_ 2566663422 TrtrBrkClprLnngClrnAxl5Rght 7405;
BA_ "SPN" SG_ 2566663678 EngnFl2InjtrMtrngRl1Tmprtr2 7514;
BA_ "SPN" SG_ 2566663678 LNGTank1VaporPressure 6787;
BA_ "SPN" SG_ 2566663678 LNGTank2VaporPressure 6788;
BA_ "SPN" SG_ 2566663934 EngnClndrHdBpssAttr1MtrCrrntDsl 7382;
BA_ "SPN" SG_ 2566663934 EngnThrttlVlv1MtrCrrntDsl 7383;
BA_ "SPN" SG_ 2566663934 EngnTrhrgrWstgtAttr1MtrCrrntDsl 7381;
BA_ "SPN" SG_ 2566663934 EngnTrhrgrWstgtAttr2MtrCrrntDsl 7710;
BA_ "SPN" SG_ 2566663934 ETCpssBpssAtt1MtCtDs 7708;
BA_ "SPN" SG_ 2566663934 ETCpssBpssAtt2MtCtDs 7709;
BA_ "SPN" SG_ 2566663934 ETCpssBwAtt1MtCtDs 7380;
BA_ "SPN" SG_ 2566664702 AftertreatmentEngineLoadRequest 7503;
BA_ "SPN" SG_ 2566664702 AftrtrtmntAmntArTmprtr 7441;
BA_ "SPN" SG_ 2566664702 AftrtrtmntDslExhstFldHtrCrtBrkr 7588;
BA_ "SPN" SG_ 2566664702 AftrtrtmntDslExhstFldTnkTmprtr 7607;
BA_ "SPN" SG_ 2566664702 AftrtrtmntDslExhstFldTnkVlm 7606;
BA_ "SPN" SG_ 2566664702 AftrtrtmntEngnSpdInrsrqst 7502;
BA_ "SPN" SG_ 2566664702 AftrtrtmntThrmlMngmntStts 7332;
BA_ "SPN" SG_ 2566664702 AttttAtvRtItdDtLwExstPss 7440;
BA_ "SPN" SG_ 2566664702 DslExhstFldQltMlfntnEvltnPrdAtv 7899;
BA_ "SPN" SG_ 2566664702 AftrtrtmntSCRDsngMdStts 9176;
BA_ "SPN" SG_ 2566664702 DPFAtvRgnrtnTmRmnng 10156;
BA_ "SPN" SG_ 2566665726 Aftrtrtmnt2DslExhstFldPmpHtr 7086;
BA_ "SPN" SG_ 2566665726 Atttt2DsExstFdPp2MtSpd 7466;
BA_ "SPN" SG_ 2566667262 EngineEndBearing17Temperature 7059;
BA_ "SPN" SG_ 2566667262 EngineEndBearing18Temperature 7060;
BA_ "SPN" SG_ 2566667262 EngineEndBearing19Temperature 7061;
BA_ "SPN" SG_ 2566667262 EngineEndBearing20Temperature 7062;
BA_ "SPN" SG_ 2566667518 EngineEndBearing10Temperature 7052;
BA_ "SPN" SG_ 2566667518 EngineEndBearing11Temperature 7053;
BA_ "SPN" SG_ 2566667518 EngineEndBearing12Temperature 7054;
BA_ "SPN" SG_ 2566667518 EngineEndBearing13Temperature 7055;
BA_ "SPN" SG_ 2566667518 EngineEndBearing14Temperature 7056;
BA_ "SPN" SG_ 2566667518 EngineEndBearing15Temperature 7057;
BA_ "SPN" SG_ 2566667518 EngineEndBearing16Temperature 7058;
BA_ "SPN" SG_ 2566667518 EngineEndBearing9Temperature 7051;
BA_ "SPN" SG_ 2566667774 EngineEndBearing1Temperature 7043;
BA_ "SPN" SG_ 2566667774 EngineEndBearing2Temperature 7044;
BA_ "SPN" SG_ 2566667774 EngineEndBearing3Temperature 7045;
BA_ "SPN" SG_ 2566667774 EngineEndBearing4Temperature 7046;
BA_ "SPN" SG_ 2566667774 EngineEndBearing5Temperature 7047;
BA_ "SPN" SG_ 2566667774 EngineEndBearing6Temperature 7048;
BA_ "SPN" SG_ 2566667774 EngineEndBearing7Temperature 7049;
BA_ "SPN" SG_ 2566667774 EngineEndBearing8Temperature 7050;
BA_ "SPN" SG_ 2566668030 HeatExchangerDebrisPurgeStatus 7035;
BA_ "SPN" SG_ 2566668030 HtExhngrDrsPrgApprhng 7036;
BA_ "SPN" SG_ 2566668286 EngnStgdTrhrgrSlndStts 7025;
BA_ "SPN" SG_ 2566668542 EngnFl2PmpHdrlDrtnlVlv 7018;
BA_ "SPN" SG_ 2566668542 EngnFl2PmpHdrlFlwCntrlVlv 7016;
BA_ "SPN" SG_ 2566668542 EngnFl2PmpHdrlPrssr 7019;
BA_ "SPN" SG_ 2566668542 EngnFl2PmpHdrlSwshPltAngl 7017;
BA_ "SPN" SG_ 2566668798 EngnFl2InjtrMtrngRl1Prssr 7021;
BA_ "SPN" SG_ 2566668798 EngnFl2InjtrMtrngRl1Prssr2 7513;
BA_ "SPN" SG_ 2566668798 EngnFl2InjtrMtrngRl1Tmprtr 7023;
BA_ "SPN" SG_ 2566668798 EngnFl2InjtrMtrngRl2Prssr 7022;
BA_ "SPN" SG_ 2566668798 EngnFl2InjtrMtrngRl2Tmprtr 7024;
BA_ "SPN" SG_ 2566669054 RequiredTirePressure 6989;
BA_ "SPN" SG_ 2566669054 TireLocation 6987;
BA_ "SPN" SG_ 2566669054 TirePressureExtendedRange 6988;
BA_ "SPN" SG_ 2566669310 ColdInflationPressure 6980;
BA_ "SPN" SG_ 2566669310 ExtrmUndrPrssrPrntgThrshld 6982;
BA_ "SPN" SG_ 2566669310 OverPressurePercentageThreshold 6983;
BA_ "SPN" SG_ 2566669310 OverTemperature 6984;
BA_ "SPN" SG_ 2566669310 TireLocation 6979;
BA_ "SPN" SG_ 2566669310 UndrPrssrPrntgThrshld 6981;
BA_ "SPN" SG_ 2566669822 AntennaNumber 6968;
BA_ "SPN" SG_ 2566669822 TireLocation 6971;
BA_ "SPN" SG_ 2566669822 TireSensorNumber 6970;
BA_ "SPN" SG_ 2566669822 TotalNumberofAntennasUsed 6967;
BA_ "SPN" SG_ 2566669822 TrWrlssSgnlStrngthIndtr 6972;
BA_ "SPN" SG_ 2566669822 TtlNmrfTrSnsrsMntrd 6969;
BA_ "SPN" SG_ 2566670078 NumberofTireSensors 6963;
BA_ "SPN" SG_ 2566670078 TireLocation 6965;
BA_ "SPN" SG_ 2566670078 TireNumber 6964;
BA_ "SPN" SG_ 2566670078 TireSensorIdentificationNumber 6966;
BA_ "SPN" SG_ 2566670334 Axle10MonitoredTireCount 6960;
BA_ "SPN" SG_ 2566670334 Axle11MonitoredTireCount 6961;
BA_ "SPN" SG_ 2566670334 Axle12MonitoredTireCount 6962;
BA_ "SPN" SG_ 2566670334 Axle1MonitoredTireCount 6951;
BA_ "SPN" SG_ 2566670334 Axle2MonitoredTireCount 6952;
BA_ "SPN" SG_ 2566670334 Axle3MonitoredTireCount 6953;
BA_ "SPN" SG_ 2566670334 Axle4MonitoredTireCount 6954;
BA_ "SPN" SG_ 2566670334 Axle5MonitoredTireCount 6955;
BA_ "SPN" SG_ 2566670334 Axle6MonitoredTireCount 6956;
BA_ "SPN" SG_ 2566670334 Axle7MonitoredTireCount 6957;
BA_ "SPN" SG_ 2566670334 Axle8MonitoredTireCount 6958;
BA_ "SPN" SG_ 2566670334 Axle9MonitoredTireCount 6959;
BA_ "SPN" SG_ 2566670334 NumberofAxlesontheVehicle 6949;
BA_ "SPN" SG_ 2566670334 NumberofTiresontheVehicle 6950;
BA_ "SPN" SG_ 2566670590 Atttt2SCRSstAvDstBtwSstCEvts 6947;
BA_ "SPN" SG_ 2566670590 Atttt2SCRSstAvTBtwSstCEvts 6946;
BA_ "SPN" SG_ 2566670590 Atttt2SCRSstTtNSstCEvts 6943;
BA_ "SPN" SG_ 2566670590 Atttt2SCRSstTtNSstCItRqsts 6944;
BA_ "SPN" SG_ 2566670590 Atttt2SCRSstTtNSstCMRqsts 6945;
BA_ "SPN" SG_ 2566670590 Atttt2SCRSstTtSstCT 6942;
BA_ "SPN" SG_ 2566670846 Aftrtrtmnt1SCRSstmTtlClnngTm 6935;
BA_ "SPN" SG_ 2566670846 Atttt1SCRSstAvDstBtwSstCEvts 6940;
BA_ "SPN" SG_ 2566670846 Atttt1SCRSstAvTBtwSstCEvts 6939;
BA_ "SPN" SG_ 2566670846 Atttt1SCRSstTtNSstCEvts 6936;
BA_ "SPN" SG_ 2566670846 Atttt1SCRSstTtNSstCItRqsts 6937;
BA_ "SPN" SG_ 2566670846 Atttt1SCRSstTtNSstCMRqsts 6938;
BA_ "SPN" SG_ 2566670846 TtlAftrtrtmntOprtngHrs 8629;
BA_ "SPN" SG_ 2566671102 Atttt1SCRSstCdtsNtMtAtvC 7848;
BA_ "SPN" SG_ 2566671102 SCRSstCItdDtAtPdOId 6922;
BA_ "SPN" SG_ 2566671102 SCRSstCItdDtLwExstTpt 6926;
BA_ "SPN" SG_ 2566671102 SCRSstCItdDtPtSstLt 6930;
BA_ "SPN" SG_ 2566671102 SCRSstCItdDtVSpdAvAwdSpd 6924;
BA_ "SPN" SG_ 2566671102 SCRSstCItdDtVSpdBwAwdSpd 6932;
BA_ "SPN" SG_ 2566671102 SCRSstmClnngAtmtInttnCnfgrtn 6933;
BA_ "SPN" SG_ 2566671102 SCRSstmClnngInhtdDtClthDsnggd 6919;
BA_ "SPN" SG_ 2566671102 SCRSstmClnngInhtdDtEngnNtWrmdUp 6931;
BA_ "SPN" SG_ 2566671102 SCRSstmClnngInhtdDtInhtSwth 6918;
BA_ "SPN" SG_ 2566671102 SCRSstmClnngInhtdDtOtfNtrl 6923;
BA_ "SPN" SG_ 2566671102 SCRSstmClnngInhtdDtPrkngBrkNtSt 6925;
BA_ "SPN" SG_ 2566671102 SCRSstmClnngInhtdDtPTOAtv 6921;
BA_ "SPN" SG_ 2566671102 SCRSstmClnngInhtdDtSrvBrkAtv 6920;
BA_ "SPN" SG_ 2566671102 SCRSstmClnngInhtdDtSstmFltAtv 6927;
BA_ "SPN" SG_ 2566671102 SCRSstmClnngInhtdDtSstmTmt 6928;
BA_ "SPN" SG_ 2566671102 SCRSstmClnngInhtdDtTmprrSstmLkt 6929;
BA_ "SPN" SG_ 2566671102 SCRSstmClnngInhtdStts 6917;
BA_ "SPN" SG_ 2566671102 SCRSystemCleaningForcedStatus 6934;
BA_ "SPN" SG_ 2566671102 SCRSystemCleaningLampCommand 6915;
BA_ "SPN" SG_ 2566671102 SCRSystemCleaningStatus 6916;
BA_ "SPN" SG_ 2566671358 CylinderFuelRate 7333;
BA_ "SPN" SG_ 2566671358 EngineExhaustFlowRate 6895;
BA_ "SPN" SG_ 2566671358 PEMSEngineFuelMassFlowRate 6893;
BA_ "SPN" SG_ 2566671358 VehicleFuelRate 6894;
BA_ "SPN" SG_ 2566671614 NSCROptIdtOvdEvtsR 6879;
BA_ "SPN" SG_ 2566671614 SCROprtrIndmntOvrrdEnl 6877;
BA_ "SPN" SG_ 2566671614 SCROprtrIndmntOvrrdTmRmnng 6878;
BA_ "SPN" SG_ 2566671614 TtlNmrfSCROprtrIndmntOvrrdEvnts 6880;
BA_ "SPN" SG_ 2566671870 Aftrtrtmnt2DslExhstFldDsr2Prssr 8153;
BA_ "SPN" SG_ 2566671870 Aftrtrtmnt2DslExhstFldDsrPrssr 6876;
BA_ "SPN" SG_ 2566671870 Atttt2DsExstFdDs2AstPss 7464;
BA_ "SPN" SG_ 2566671870 Atttt2DsExstFdDs2Tpt 7465;
BA_ "SPN" SG_ 2566672126 Aftrtrtmnt1DslExhstFldDsr2Prssr 8152;
BA_ "SPN" SG_ 2566672126 Aftrtrtmnt1DslExhstFldDsrPrssr 6875;
BA_ "SPN" SG_ 2566672126 Atttt1DsExstFdDs2AstPss 7459;
BA_ "SPN" SG_ 2566672126 Atttt1DsExstFdDs2Tpt 7460;
BA_ "SPN" SG_ 2566672382 PayloadWeightSensor1Status 6855;
BA_ "SPN" SG_ 2566672382 PayloadWeightSensor2Status 6856;
BA_ "SPN" SG_ 2566672382 PayloadWeightSensor3Status 6857;
BA_ "SPN" SG_ 2566672382 PayloadWeightSensor4Status 6858;
BA_ "SPN" SG_ 2566672382 PayloadWeightSensor5Status 6859;
BA_ "SPN" SG_ 2566672382 PayloadWeightSensor6Status 6860;
BA_ "SPN" SG_ 2566672382 PayloadWeightSensor7Status 6861;
BA_ "SPN" SG_ 2566672382 PayloadWeightSensor8Status 6862;
BA_ "SPN" SG_ 2566672638 DeliveredPayloadConfidence 6850;
BA_ "SPN" SG_ 2566672638 DeliveredPayloadWeight 6849;
BA_ "SPN" SG_ 2566672638 HaulCycleCount 6847;
BA_ "SPN" SG_ 2566672638 HaulModeStatus 6848;
BA_ "SPN" SG_ 2566672638 PldDlvrTrnstnStts 7702;
BA_ "SPN" SG_ 2566673406 GasLeakageDetection1Pressure 6837;
BA_ "SPN" SG_ 2566673406 GasLeakageDetection2Pressure 6838;
BA_ "SPN" SG_ 2566673406 GasLeakageDetection3Pressure 6839;
BA_ "SPN" SG_ 2566673406 GssFlLkg1Cnntrtn 6834;
BA_ "SPN" SG_ 2566673406 GssFlLkg2Cnntrtn 6835;
BA_ "SPN" SG_ 2566673406 GssFlLkg3Cnntrtn 6836;
BA_ "SPN" SG_ 2566674174 AftrtrtmntSCRMlfntnTm 6819;
BA_ "SPN" SG_ 2566674174 SCROperatorInducementTotalTime 7095;
BA_ "SPN" SG_ 2566674430 DslExhstFldQltMlfntnTm 6818;
BA_ "SPN" SG_ 2566674430 DslExhstFldTnk1EmptTm 6817;
BA_ "SPN" SG_ 2566674686 EngnTrhrgr2LOlPrssr 6811;
BA_ "SPN" SG_ 2566674686 EngnTrhrgr2OlTmprtr 8850;
BA_ "SPN" SG_ 2566674686 EngnTrhrgr3LOlPrssr 6812;
BA_ "SPN" SG_ 2566674686 EngnTrhrgr4LOlPrssr 6813;
BA_ "SPN" SG_ 2566675966 HVESSNominalVoltage 8115;
BA_ "SPN" SG_ 2566675966 HVESSRmmnddMnmmOprtngVltg 8116;
BA_ "SPN" SG_ 2566675966 HVESSRmmnddMxmmOprtngVltg 8117;
BA_ "SPN" SG_ 2566675966 HVESSRmmnddMnmmSttOfChrg 8118;
BA_ "SPN" SG_ 2566675966 HVESSRmmnddMxmmSttOfChrg 8119;
BA_ "SPN" SG_ 2566675966 HVESSRmmnddMxmmOprtngTmprtr 8120;
BA_ "SPN" SG_ 2566675966 HVESSRmmnddMnmmOprtngTmprtr 8208;
BA_ "SPN" SG_ 2566675966 HVESSCellMaximumVoltageLimit 8209;
BA_ "SPN" SG_ 2566675966 HVESSCellMinimumVoltageLimit 8210;
BA_ "SPN" SG_ 2566675966 HVESSNumberofHVESPsConfigured 12904;
BA_ "SPN" SG_ 2566687742 Aftrtrtmnt1PrtltSnsrDttnStts 6777;
BA_ "SPN" SG_ 2566687742 Aftrtrtmnt1PrtltSnsrHtrRsstn 7070;
BA_ "SPN" SG_ 2566687742 Aftrtrtmnt1PrtltSnsrMxmmRsstn 6781;
BA_ "SPN" SG_ 2566687742 Aftrtrtmnt1PrtltSnsrPwrSppl 6778;
BA_ "SPN" SG_ 2566687742 Aftrtrtmnt1PrtltSnsrTmprtr 6780;
BA_ "SPN" SG_ 2566687742 Atttt1PttSsRtFdCt 6779;
BA_ "SPN" SG_ 2566687998 Aftrtrtmnt1PrtltSnsrAtvAmltnTm 6775;
BA_ "SPN" SG_ 2566687998 Aftrtrtmnt1PrtltSnsrHtrStt 6772;
BA_ "SPN" SG_ 2566687998 Aftrtrtmnt1PrtltSnsrRgnrtnStt 6774;
BA_ "SPN" SG_ 2566687998 Aftrtrtmnt1PrtltSnsrRgnrtnStts 6773;
BA_ "SPN" SG_ 2566687998 Aftrtrtmnt1PrtltSnsrRsstn 6771;
BA_ "SPN" SG_ 2566687998 Atttt1PttSsTBtwRts 6776;
BA_ "SPN" SG_ 2566689278 EngineExhaustDesiredNOx 6580;
BA_ "SPN" SG_ 2566689278 EngineExhaustNOx 6579;
BA_ "SPN" SG_ 2566689278 EngnExhstNOxSnsrPwrSppl 9812;
BA_ "SPN" SG_ 2566689534 EngineMainChamberAirFuelRatio 6575;
BA_ "SPN" SG_ 2566689534 EnginePrechamberAirFuelRatio 6577;
BA_ "SPN" SG_ 2566689534 EngnMnChmrDsrdArFlRt 6576;
BA_ "SPN" SG_ 2566689534 EngnPrhmrDsrdArFlRt 6578;
BA_ "SPN" SG_ 2566689790 EngnMnChmrFlAsltPrssr 6571;
BA_ "SPN" SG_ 2566689790 EngnMnChmrFlDsrdAsltPrssr 6572;
BA_ "SPN" SG_ 2566689790 EngnPrhmrFlAsltPrssr 6573;
BA_ "SPN" SG_ 2566689790 EngnPrhmrFlDsrdAsltPrssr 6574;
BA_ "SPN" SG_ 2566690046 AfterrunCompleteThisCycle 6482;
BA_ "SPN" SG_ 2566690046 AttttDsExstFdDsCdwCptLstC 6479;
BA_ "SPN" SG_ 2566690046 AttttDsExstFdDsCdwCptTsC 6478;
BA_ "SPN" SG_ 2566690046 AttttDsExstFdDsCdwItptCt 6476;
BA_ "SPN" SG_ 2566690046 AttttDsExstFdDsPCptLstC 6481;
BA_ "SPN" SG_ 2566690046 AttttDsExstFdDsPCptTsC 6480;
BA_ "SPN" SG_ 2566690046 AttttDsExstFdDsPItptCt 6477;
BA_ "SPN" SG_ 2566690558 EngineCommonRailOilPressure 7720;
BA_ "SPN" SG_ 2566690558 EngineExhaustPressure2 5749;
BA_ "SPN" SG_ 2566690558 EngnCmmnRlOlAsltPrssr 7721;
BA_ "SPN" SG_ 2566690558 EngnExhstPrssr1ExtnddRng 6384;
BA_ "SPN" SG_ 2566690558 EOFtItPssHRstExtddR 7470;
BA_ "SPN" SG_ 2566690814 CircleSteerModeActuatorState 6380;
BA_ "SPN" SG_ 2566690814 CrabSteerModeActuatorState 6381;
BA_ "SPN" SG_ 2566690814 FrontSteeringAxleCenteredStatus 6376;
BA_ "SPN" SG_ 2566690814 RearSteeringAxleCenteredStatus 6377;
BA_ "SPN" SG_ 2566690814 StrngCntrllrECUTmprtr 6374;
BA_ "SPN" SG_ 2566690814 Wheel2SteerActuatorState 6378;
BA_ "SPN" SG_ 2566690814 Wheel4SteerActuatorState 6379;
BA_ "SPN" SG_ 2566690814 RequestedSteeringMode 6375;
BA_ "SPN" SG_ 2566690814 SteeringModeTwoWheelSwitchInput 11733;
BA_ "SPN" SG_ 2566690814 SteeringModeCrabSwitchInput 11734;
BA_ "SPN" SG_ 2566690814 SteeringModeCircleSwitchInput 11735;
BA_ "SPN" SG_ 2566690814 SteeringModeStatus 11736;
BA_ "SPN" SG_ 2566691326 AssemblyUnitIdentification 6369;
BA_ "SPN" SG_ 2566691326 NmrfAssmlUntIdntftnFlds 6368;
BA_ "SPN" SG_ 2566691582 Joystick3Lamp10Status 6367;
BA_ "SPN" SG_ 2566691582 Joystick3Lamp1Status 6358;
BA_ "SPN" SG_ 2566691582 Joystick3Lamp2Status 6359;
BA_ "SPN" SG_ 2566691582 Joystick3Lamp3Status 6360;
BA_ "SPN" SG_ 2566691582 Joystick3Lamp4Status 6361;
BA_ "SPN" SG_ 2566691582 Joystick3Lamp5Status 6362;
BA_ "SPN" SG_ 2566691582 Joystick3Lamp6Status 6363;
BA_ "SPN" SG_ 2566691582 Joystick3Lamp7Status 6364;
BA_ "SPN" SG_ 2566691582 Joystick3Lamp8Status 6365;
BA_ "SPN" SG_ 2566691582 Joystick3Lamp9Status 6366;
BA_ "SPN" SG_ 2566691838 Joystick2Lamp10Status 6357;
BA_ "SPN" SG_ 2566691838 Joystick2Lamp1Status 6348;
BA_ "SPN" SG_ 2566691838 Joystick2Lamp2Status 6349;
BA_ "SPN" SG_ 2566691838 Joystick2Lamp3Status 6350;
BA_ "SPN" SG_ 2566691838 Joystick2Lamp4Status 6351;
BA_ "SPN" SG_ 2566691838 Joystick2Lamp5Status 6352;
BA_ "SPN" SG_ 2566691838 Joystick2Lamp6Status 6353;
BA_ "SPN" SG_ 2566691838 Joystick2Lamp7Status 6354;
BA_ "SPN" SG_ 2566691838 Joystick2Lamp8Status 6355;
BA_ "SPN" SG_ 2566691838 Joystick2Lamp9Status 6356;
BA_ "SPN" SG_ 2566692094 Joystick1Lamp10Status 6347;
BA_ "SPN" SG_ 2566692094 Joystick1Lamp1Status 6338;
BA_ "SPN" SG_ 2566692094 Joystick1Lamp2Status 6339;
BA_ "SPN" SG_ 2566692094 Joystick1Lamp3Status 6340;
BA_ "SPN" SG_ 2566692094 Joystick1Lamp4Status 6341;
BA_ "SPN" SG_ 2566692094 Joystick1Lamp5Status 6342;
BA_ "SPN" SG_ 2566692094 Joystick1Lamp6Status 6343;
BA_ "SPN" SG_ 2566692094 Joystick1Lamp7Status 6344;
BA_ "SPN" SG_ 2566692094 Joystick1Lamp8Status 6345;
BA_ "SPN" SG_ 2566692094 Joystick1Lamp9Status 6346;
BA_ "SPN" SG_ 2566692862 DisplayRemainPowered 6846;
BA_ "SPN" SG_ 2566692862 EngineFuel2Tank1Level 6642;
BA_ "SPN" SG_ 2566692862 EngineFuel2Tank2Level 6643;
BA_ "SPN" SG_ 2566692862 EngineFuel2Tank3Level 6644;
BA_ "SPN" SG_ 2566692862 EngineFuel2Tank4Level 6645;
BA_ "SPN" SG_ 2566692862 EngineOilLevelHighLow 8856;
BA_ "SPN" SG_ 2566692862 EngnOlFltrDffrntlPrssrExtnddRng 6321;
BA_ "SPN" SG_ 2566697470 EngnIgntnCntrlMdl1Stt 6216;
BA_ "SPN" SG_ 2566697470 EngnIgntnCntrlMdl1Tmprtr 6214;
BA_ "SPN" SG_ 2566697470 EngnIgntnCntrlMdl2Stt 6217;
BA_ "SPN" SG_ 2566697470 EngnIgntnCntrlMdl2Tmprtr 6215;
